VERSION "HNNBNNNYNNNNNNNNNNNNNNNNNNNNNNNNNNNNNNNNNN/4/%%%/4/'%**4NNN///"

NS_ :

BS_:

BU_: BAP_Tester ELV Gateway_Max HUD Kombi

BO_ 2527679748 RDK_11: 32 Gateway_Max
 SG_ TPMS_CalTyp : 12|2@1+ (1.0,0.0) [0.0|3] ""  Vector__XXX
 SG_ TPMS_WhlChgDetFrLe : 14|1@1+ (1.0,0.0) [0.0|1] ""  Vector__XXX
 SG_ TPMS_WhlChgDetFrRi : 15|1@1+ (1.0,0.0) [0.0|1] ""  Vector__XXX
 SG_ TPMS_WhlChgDetReLe : 16|1@1+ (1.0,0.0) [0.0|1] ""  Vector__XXX
 SG_ TPMS_WhlChgDetReRi : 17|1@1+ (1.0,0.0) [0.0|1] ""  Vector__XXX
 SG_ TPMS_Warn1 : 18|1@1+ (1.0,0.0) [0.0|1] ""  Kombi
 SG_ TPMS_Warn1TireFrLe : 19|1@1+ (1.0,0.0) [0.0|1] ""  Vector__XXX
 SG_ TPMS_Warn1TireFrRi : 20|1@1+ (1.0,0.0) [0.0|1] ""  Vector__XXX
 SG_ TPMS_Warn1TireReLe : 21|1@1+ (1.0,0.0) [0.0|1] ""  Vector__XXX
 SG_ TPMS_Warn1TireReRi : 22|1@1+ (1.0,0.0) [0.0|1] ""  Vector__XXX
 SG_ TPMS_Warn2 : 23|1@1+ (1.0,0.0) [0.0|1] ""  Kombi
 SG_ TPMS_Warn2TireFrLe : 24|1@1+ (1.0,0.0) [0.0|1] ""  Vector__XXX
 SG_ TPMS_Warn2TireFrRi : 25|1@1+ (1.0,0.0) [0.0|1] ""  Vector__XXX
 SG_ TPMS_Warn2TireReLe : 26|1@1+ (1.0,0.0) [0.0|1] ""  Vector__XXX
 SG_ TPMS_Warn2TireReRi : 27|1@1+ (1.0,0.0) [0.0|1] ""  Vector__XXX
 SG_ TPMS_Warn3 : 28|1@1+ (1.0,0.0) [0.0|1] ""  Kombi
 SG_ TPMS_Warn3TireFrLe : 29|1@1+ (1.0,0.0) [0.0|1] ""  Vector__XXX
 SG_ TPMS_Warn3TireFrRi : 30|1@1+ (1.0,0.0) [0.0|1] ""  Vector__XXX
 SG_ TPMS_Warn3TireReLe : 31|1@1+ (1.0,0.0) [0.0|1] ""  Vector__XXX
 SG_ TPMS_Warn3TireReRi : 32|1@1+ (1.0,0.0) [0.0|1] ""  Vector__XXX
 SG_ TPMS_Warn4 : 33|1@1+ (1.0,0.0) [0.0|1] ""  Vector__XXX
 SG_ TPMS_Warn4TireFrLe : 34|1@1+ (1.0,0.0) [0.0|1] ""  Vector__XXX
 SG_ TPMS_Warn4TireFrRi : 35|1@1+ (1.0,0.0) [0.0|1] ""  Vector__XXX
 SG_ TPMS_Warn4TireReLe : 36|1@1+ (1.0,0.0) [0.0|1] ""  Vector__XXX
 SG_ TPMS_Warn4TireReRi : 37|1@1+ (1.0,0.0) [0.0|1] ""  Vector__XXX
 SG_ TPMS_WarnCalOk : 38|1@1+ (1.0,0.0) [0.0|1] ""  Vector__XXX
 SG_ TPMS_WarnLmpStMil : 39|1@1+ (1.0,0.0) [0.0|1] ""  Kombi
 SG_ TPMS_WarnSysLrn : 40|1@1+ (1.0,0.0) [0.0|1] ""  Vector__XXX
 SG_ TPMS_WarnTmpFlt : 41|1@1+ (1.0,0.0) [0.0|1] ""  Kombi
 SG_ TPMS_WarnWhlChgDet : 42|1@1+ (1.0,0.0) [0.0|1] ""  Vector__XXX
 SG_ TPMS_RaceTrckMdSts : 43|1@1+ (1.0,0.0) [0.0|1] ""  Vector__XXX
 SG_ TPMS_WarnAcoCalOk : 44|1@1+ (1.0,0.0) [0.0|1] ""  Vector__XXX
 SG_ TPMS_WarnCmftP : 45|1@1+ (1.0,0.0) [0.0|1] ""  Vector__XXX
 SG_ TPMS_WarnFltIdc : 46|1@1+ (1.0,0.0) [0.0|1] ""  Kombi
 SG_ TPMS_WarnFr : 47|1@1+ (1.0,0.0) [0.0|1] ""  Vector__XXX
 SG_ TPMS_WarnLmpStP : 48|1@1+ (1.0,0.0) [0.0|1] ""  Kombi
 SG_ TPMS_WarnMaxV : 49|1@1+ (1.0,0.0) [0.0|1] ""  Vector__XXX
 SG_ TPMS_WarnRaceTrckMdMinP : 50|1@1+ (1.0,0.0) [0.0|1] ""  Vector__XXX
 SG_ TPMS_WarnRe : 51|1@1+ (1.0,0.0) [0.0|1] ""  Vector__XXX
 SG_ TPMS_SensTFrLe : 52|8@1+ (1,-60) [-60|193] "Unit_DegreCelsi"  Vector__XXX
 SG_ TPMS_SensTFrRi : 60|8@1+ (1,-60) [-60|193] "Unit_DegreCelsi"  Vector__XXX
 SG_ TPMS_SensTReLe : 68|8@1+ (1,-60) [-60|193] "Unit_DegreCelsi"  Vector__XXX
 SG_ TPMS_SensTReRi : 76|8@1+ (1,-60) [-60|193] "Unit_DegreCelsi"  Vector__XXX
 SG_ TPMS_SensPFrLe : 84|6@1+ (0.1,0) [0.0|6.2] "Unit_Bar"  Vector__XXX
 SG_ TPMS_SensPFrRi : 90|6@1+ (0.1,0) [0.0|6.2] "Unit_Bar"  Vector__XXX
 SG_ TPMS_SensPReLe : 96|6@1+ (0.1,0) [0.0|6.2] "Unit_Bar"  Vector__XXX
 SG_ TPMS_SensPReRi : 102|6@1+ (0.1,0) [0.0|6.2] "Unit_Bar"  Vector__XXX
 SG_ TPMS_PDeFrLe : 108|7@1+ (0.1,-6.3) [-6.3|6.3] "Unit_Bar"  Vector__XXX
 SG_ TPMS_PDeFrRi : 115|7@1+ (0.1,-6.3) [-6.3|6.3] "Unit_Bar"  Vector__XXX
 SG_ TPMS_PDeReLe : 122|7@1+ (0.1,-6.3) [-6.3|6.3] "Unit_Bar"  Vector__XXX
 SG_ TPMS_PDeReRi : 129|7@1+ (0.1,-6.3) [-6.3|6.3] "Unit_Bar"  Vector__XXX
 SG_ TPMS_SensBattStsFrLe : 136|7@1+ (1,0) [0|100] "Unit_PerCent"  Vector__XXX
 SG_ TPMS_SensBattStsFrRi : 143|7@1+ (1,0) [0|100] "Unit_PerCent"  Vector__XXX
 SG_ TPMS_SensBattStsReLe : 150|7@1+ (1,0) [0|100] "Unit_PerCent"  Vector__XXX
 SG_ TPMS_SensBattStsReRi : 157|7@1+ (1,0) [0|100] "Unit_PerCent"  Vector__XXX
 SG_ TPMS_SensSigAgeFrLe : 164|4@1+ (1,0) [0|10] "Unit_Minut"  Vector__XXX
 SG_ TPMS_SensSigAgeFrRi : 168|4@1+ (1,0) [0|10] "Unit_Minut"  Vector__XXX
 SG_ TPMS_SensSigAgeReLe : 172|4@1+ (1,0) [0|10] "Unit_Minut"  Vector__XXX
 SG_ TPMS_SensSigAgeReRi : 176|4@1+ (1,0) [0|10] "Unit_Minut"  Vector__XXX
 SG_ TPMS_SensStsFrLe : 180|1@1+ (1.0,0.0) [0.0|1] ""  Vector__XXX
 SG_ TPMS_SensStsFrRi : 181|1@1+ (1.0,0.0) [0.0|1] ""  Vector__XXX
 SG_ TPMS_SensStsReLe : 182|1@1+ (1.0,0.0) [0.0|1] ""  Vector__XXX
 SG_ TPMS_SensStsReRi : 183|1@1+ (1.0,0.0) [0.0|1] ""  Vector__XXX
 SG_ TPMS_SensTypFrLe : 184|1@1+ (1.0,0.0) [0.0|1] ""  Vector__XXX
 SG_ TPMS_SensTypFrRi : 185|1@1+ (1.0,0.0) [0.0|1] ""  Vector__XXX
 SG_ TPMS_SensTypReLe : 186|1@1+ (1.0,0.0) [0.0|1] ""  Vector__XXX
 SG_ TPMS_SensTypReRi : 187|1@1+ (1.0,0.0) [0.0|1] ""  Vector__XXX
 SG_ TPMS_enable : 188|1@1+ (1.0,0.0) [0.0|1] ""  Vector__XXX
 SG_ TPMS_disable : 189|1@1+ (1.0,0.0) [0.0|1] ""  Vector__XXX
 SG_ TPMS_TarPTmpDepFrLe : 190|6@1+ (0.1,0) [0.0|6.2] "Unit_Bar"  Vector__XXX
 SG_ TPMS_TarPTmpDepFrRi : 196|6@1+ (0.1,0) [0.0|6.2] "Unit_Bar"  Vector__XXX
 SG_ TPMS_TarPTmpDepReLe : 202|6@1+ (0.1,0) [0.0|6.2] "Unit_Bar"  Vector__XXX
 SG_ TPMS_TarPTmpDepReRi : 208|6@1+ (0.1,0) [0.0|6.2] "Unit_Bar"  Vector__XXX
 SG_ TPMS_LearningState : 214|4@1+ (1.0,0.0) [0.0|15] ""  Vector__XXX
 SG_ SOK_RDK_11_Signatur : 224|32@1+ (1,0) [0|4294967295] ""  Vector__XXX

BO_ 2527679742 Rear_View_06: 8 Gateway_Max
 SG_ Kam_Anf_Meldung : 12|3@1+ (1.0,0.0) [0.0|7] ""  Vector__XXX
 SG_ Kam_PaCo_MainState : 15|3@1+ (1.0,0.0) [0.0|7] ""  Vector__XXX

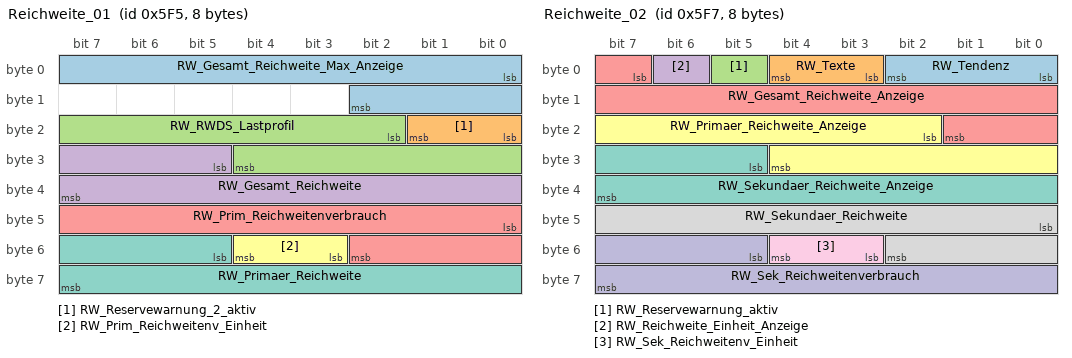
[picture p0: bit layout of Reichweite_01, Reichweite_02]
BO_ 1525 Reichweite_01: 8 Gateway_Max
 SG_ RW_Gesamt_Reichweite_Max_Anzeige : 0|11@1+ (1,0) [0|2044] "Unit_None"  Kombi
 SG_ RW_Reservewarnung_2_aktiv : 16|2@1+ (1.0,0.0) [0.0|3] ""  Vector__XXX
 SG_ RW_RWDS_Lastprofil : 18|11@1+ (1,0) [0|2045] "Unit_Amper"  Vector__XXX
 SG_ RW_Gesamt_Reichweite : 29|11@1+ (1,0) [0|2044] "Unit_KiloMeter"  Kombi
 SG_ RW_Prim_Reichweitenverbrauch : 40|11@1+ (0.1,0) [0.0|204.4] "Unit_None"  Kombi
 SG_ RW_Prim_Reichweitenv_Einheit : 51|2@1+ (1.0,0.0) [0.0|3] ""  Kombi
 SG_ RW_Primaer_Reichweite : 53|11@1+ (1,0) [0|2044] "Unit_KiloMeter"  Kombi

BO_ 1527 Reichweite_02: 8 Gateway_Max
 SG_ RW_Tendenz : 0|3@1+ (1.0,0.0) [0.0|7] ""  Vector__XXX
 SG_ RW_Texte : 3|2@1+ (1.0,0.0) [0.0|3] ""  Kombi
 SG_ RW_Reservewarnung_aktiv : 5|1@1+ (1.0,0.0) [0.0|1] ""  Kombi
 SG_ RW_Reichweite_Einheit_Anzeige : 6|1@1+ (1.0,0.0) [0.0|1] ""  Kombi
 SG_ RW_Gesamt_Reichweite_Anzeige : 7|11@1+ (1,0) [0|2044] "Unit_None"  Kombi
 SG_ RW_Primaer_Reichweite_Anzeige : 18|11@1+ (1,0) [0|2044] "Unit_None"  Kombi
 SG_ RW_Sekundaer_Reichweite_Anzeige : 29|11@1+ (1,0) [0|2044] "Unit_None"  Kombi
 SG_ RW_Sekundaer_Reichweite : 40|11@1+ (1,0) [0|2044] "Unit_KiloMeter"  Kombi
 SG_ RW_Sek_Reichweitenv_Einheit : 51|2@1+ (1.0,0.0) [0.0|3] ""  Kombi
 SG_ RW_Sek_Reichweitenverbrauch : 53|11@1+ (0.1,0) [0.0|204.4] "Unit_None"  Kombi

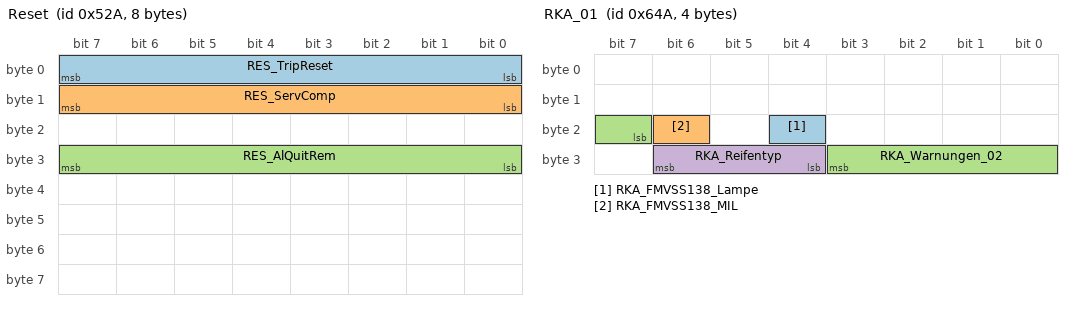
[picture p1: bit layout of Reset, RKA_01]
BO_ 1322 Reset: 8 Kombi
 SG_ RES_TripReset : 0|8@1+ (1.0,0.0) [0.0|255] ""  Vector__XXX
 SG_ RES_ServComp : 8|8@1+ (1,0) [0|255] ""  Vector__XXX
 SG_ RES_AlQuitRem : 24|8@1+ (1.0,0.0) [0.0|255] ""  Vector__XXX

BO_ 2331596042 RHP_02: 48 Gateway_Max
 SG_ RHP_02_CRC : 0|8@1+ (1,0) [0|255] ""  Kombi
 SG_ RHP_02_BZ : 8|4@1+ (1,0) [0|15] ""  Kombi
 SG_ RHP_Wunschgeschw : 12|10@1+ (0.32,0) [0.00|327.04] "Unit_KiloMeterPerHour"  Kombi
 SG_ RHP_Wunschgeschw_Farbe : 22|2@1+ (1.0,0.0) [0.0|3] ""  Kombi
 SG_ RHP_Text_02 : 24|5@1+ (1.0,0.0) [0.0|31] ""  Kombi
 SG_ RHP_Gong : 29|2@1+ (1.0,0.0) [0.0|3] ""  Kombi
 SG_ RHP_Tempolimit : 31|5@1+ (1.0,0.0) [0.0|31] ""  Kombi
 SG_ RHP_Tempolimit_Farbe : 36|2@1+ (1.0,0.0) [0.0|3] ""  Kombi
 SG_ RHP_Texte_Sekundaeranz : 38|5@1+ (1.0,0.0) [0.0|31] ""  Kombi
 SG_ RHP_aktiv_HMI : 43|2@1+ (1.0,0.0) [0.0|3] ""  Kombi
 SG_ RHP_FoD_Status : 45|2@1+ (1.0,0.0) [0.0|3] ""  Vector__XXX
 SG_ RHP_Anzeige_Objektregelung : 47|5@1+ (1.0,0.0) [0.0|31] ""  Kombi
 SG_ RHP_HMI_DetectedLane : 52|2@1+ (1.0,0.0) [0.0|3] ""  Kombi
 SG_ RHP_HMI_Ego_li_Anzeige : 54|3@1+ (1.0,0.0) [0.0|7] ""  Kombi
 SG_ RHP_HMI_Ego_li_Seg1_QuerAbst : 57|12@1+ (0.00390625,-8) [-8.00000000|7.99609375] "Unit_Meter"  Kombi
 SG_ RHP_HMI_Ego_li_Typ : 69|3@1+ (1.0,0.0) [0.0|7] ""  Kombi
 SG_ RHP_HMI_Ego_re_Anzeige : 72|3@1+ (1.0,0.0) [0.0|7] ""  Kombi
 SG_ RHP_HMI_Ego_re_Seg1_QuerAbst : 75|12@1+ (0.00390625,-8) [-8.00000000|7.99609375] "Unit_Meter"  Kombi
 SG_ RHP_HMI_Ego_re_Typ : 87|3@1+ (1.0,0.0) [0.0|7] ""  Kombi
 SG_ RHP_HMI_EgoObj_dy : 90|7@1+ (0.007874,0) [0.000000|0.999998] "Unit_PerCent"  Kombi
 SG_ RHP_HMI_Kurvenwarnung : 97|2@1+ (1.0,0.0) [0.0|3] ""  Kombi
 SG_ RHP_HMI_LaneChangeIndicator : 99|1@1+ (1.0,0.0) [0.0|1] ""  Kombi
 SG_ RHP_HMI_LaneChangeTrajectory : 100|3@1+ (1.0,0.0) [0.0|7] ""  Kombi
 SG_ RHP_HMI_Nachb_li_Anzeige : 103|3@1+ (1.0,0.0) [0.0|7] ""  Kombi
 SG_ RHP_HMI_Nachb_li_Seg1_QuerAbst : 106|12@1+ (0.00390625,-8) [-8.00000000|7.99609375] "Unit_Meter"  Kombi
 SG_ RHP_HMI_Nachb_li_Typ : 118|3@1+ (1.0,0.0) [0.0|7] ""  Kombi
 SG_ RHP_HMI_Nachb_re_Anzeige : 121|3@1+ (1.0,0.0) [0.0|7] ""  Kombi
 SG_ RHP_HMI_Nachb_re_Seg1_QuerAbst : 124|12@1+ (0.00390625,-8) [-8.00000000|7.99609375] "Unit_Meter"  Kombi
 SG_ RHP_HMI_Nachb_re_Typ : 136|3@1+ (1.0,0.0) [0.0|7] ""  Kombi
 SG_ RHP_Abstand_WZO : 139|10@1+ (0.2,0) [0.2|204.6] "Unit_Meter"  Kombi
 SG_ RHP_Sollabstand_1 : 149|10@1+ (0.2,0) [0.2|204.6] "Unit_Meter"  Kombi
 SG_ RHP_Sollabstand_2 : 159|10@1+ (0.2,0) [0.2|204.6] "Unit_Meter"  Kombi
 SG_ RHP_Sollabstand_3 : 169|10@1+ (0.2,0) [0.2|204.6] "Unit_Meter"  Kombi
 SG_ RHP_Sollabstand_4 : 179|10@1+ (0.2,0) [0.2|204.6] "Unit_Meter"  Kombi
 SG_ RHP_Sollabstand_5 : 189|10@1+ (0.2,0) [0.2|204.6] "Unit_Meter"  Kombi
 SG_ RHP_Anzeige_Zeitluecke : 199|1@1+ (1.0,0.0) [0.0|1] ""  Kombi
 SG_ RHP_Abstandsindex : 200|10@1+ (1,0) [1|1021] ""  Kombi
 SG_ RHP_Abstand_LNS : 210|10@1+ (0.2,0) [0.2|204.6] "Unit_Meter"  Kombi
 SG_ RHP_Abstand_RNS : 220|10@1+ (0.2,0) [0.2|204.6] "Unit_Meter"  Kombi
 SG_ RHP_Typ_LNS : 230|3@1+ (1.0,0.0) [0.0|7] ""  Kombi
 SG_ RHP_Typ_RNS : 233|3@1+ (1.0,0.0) [0.0|7] ""  Kombi
 SG_ RHP_Typ_WZO : 236|3@1+ (1.0,0.0) [0.0|7] ""  Kombi
 SG_ RHP_Anzeige_Maximalabstand : 239|7@1+ (2,0) [0|254] "Unit_Meter"  Kombi
 SG_ RHP_Regelgeschw : 246|10@1+ (0.32,0) [0.00|327.04] "Unit_KiloMeterPerHour"  Kombi
 SG_ RHP_EGO_Fahrzeug : 256|3@1+ (1.0,0.0) [0.0|7] ""  Kombi
 SG_ RHP_Relevantes_Objekt : 259|2@1+ (1.0,0.0) [0.0|3] ""  Kombi
 SG_ RHP_Tempolimit_Einheit : 261|1@1+ (1.0,0.0) [0.0|1] ""  Kombi
 SG_ RHP_maxSetzgeschw : 262|9@1+ (1,0) [0|510] ""  Kombi
 SG_ RHP_Einheit_maxSetzgeschw : 271|1@1+ (1.0,0.0) [0.0|1] ""  Kombi
 SG_ RHP_TOR_Lamp : 272|2@1+ (1.0,0.0) [0.0|3] ""  Kombi
 SG_ RHP_Gesetzte_Zeitluecke : 274|3@1+ (1.0,0.0) [0.0|7] ""  Kombi
 SG_ RHP_StatusLamp : 277|3@1+ (1.0,0.0) [0.0|7] ""  Kombi
 SG_ RHP_LateralLamp : 280|2@1+ (1.0,0.0) [0.0|3] ""  Kombi
 SG_ RHP_Text_01 : 282|4@1+ (1.0,0.0) [0.0|15] ""  Kombi
 SG_ RHP_ErrorStatus : 286|3@1+ (1.0,0.0) [0.0|7] ""  Kombi
 SG_ RHP_Typ_CIO : 289|3@1+ (1.0,0.0) [0.0|7] ""  Kombi
 SG_ RHP_CIO : 292|2@1+ (1.0,0.0) [0.0|3] ""  Kombi
 SG_ RHP_Abstand_CIO : 294|10@1+ (0.2,0) [0.2|204.6] "Unit_Meter"  Kombi

BO_ 1610 RKA_01: 4 Gateway_Max
 SG_ RKA_FMVSS138_Lampe : 20|1@1+ (1.0,0.0) [0.0|1] ""  Kombi
 SG_ RKA_FMVSS138_MIL : 22|1@1+ (1,0) [0|1] ""  Kombi
 SG_ RKA_Warnungen_02 : 23|5@1+ (1.0,0.0) [0.0|31] ""  Kombi
 SG_ RKA_Reifentyp : 28|3@1+ (1.0,0.0) [0.0|7] ""  Vector__XXX

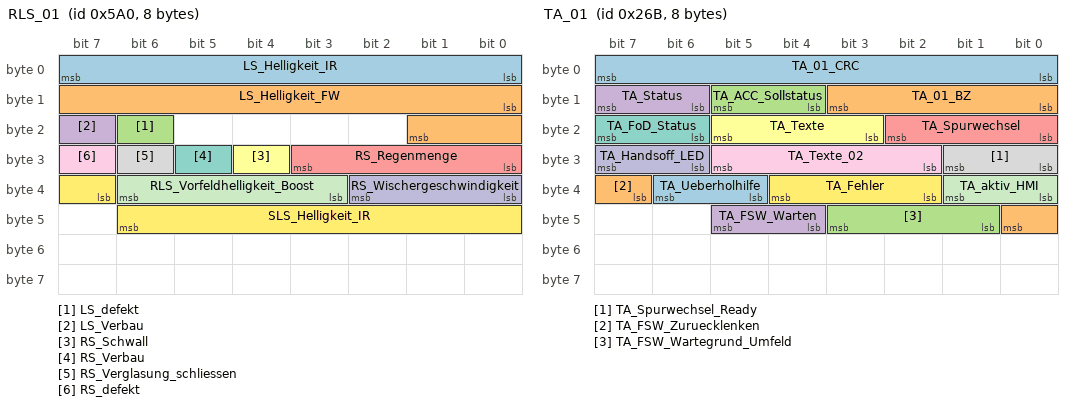
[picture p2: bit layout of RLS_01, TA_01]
BO_ 1440 RLS_01: 8 Gateway_Max
 SG_ LS_Helligkeit_IR : 0|8@1+ (400,0) [0|101200] "Unit_Lux"  Vector__XXX
 SG_ LS_Helligkeit_FW : 8|10@1+ (6,0) [0|6126] "Unit_Lux"  HUD
 SG_ LS_defekt : 22|1@1+ (1.0,0.0) [0.0|1] ""  Vector__XXX
 SG_ LS_Verbau : 23|1@1+ (1.0,0.0) [0.0|1] ""  Vector__XXX
 SG_ RS_Regenmenge : 24|4@1+ (1.0,0.0) [0.0|15] ""  Vector__XXX
 SG_ RS_Schwall : 28|1@1+ (1.0,0.0) [0.0|1] ""  Vector__XXX
 SG_ RS_Verbau : 29|1@1+ (1.0,0.0) [0.0|1] ""  Vector__XXX
 SG_ RS_Verglasung_schliessen : 30|1@1+ (1.0,0.0) [0.0|1] ""  Vector__XXX
 SG_ RS_defekt : 31|1@1+ (1.0,0.0) [0.0|1] ""  Kombi
 SG_ RS_Wischergeschwindigkeit : 32|3@1+ (1.0,0.0) [0.0|7] ""  Vector__XXX
 SG_ RLS_Vorfeldhelligkeit_Boost : 35|4@1+ (1.0,0.0) [0.0|15] ""  HUD
 SG_ SLS_Helligkeit_IR : 39|8@1+ (250,0) [0|7000] "Unit_Lux"  Vector__XXX

BO_ 2584746776 SACID_1_AuthTime_Req: 8 Gateway_Max
 SG_ SACID_1_AuthTime_Req_Data : 0|64@1+ (1.0,0.0) [0.0|18446744073709551615] ""  Kombi

BO_ 2584877848 SACID_1_AuthTime_Resp: 8 Kombi
 SG_ SACID_1_AuthTime_Resp_Data : 0|64@1+ (1.0,0.0) [0.0|18446744073709551615] ""  Gateway_Max

BO_ 1504 SAD_01: 8 Gateway_Max
 SG_ MD1_Position : 8|7@1+ (1,0) [0|100] "Unit_PerCent"  Vector__XXX
 SG_ MD1_Lage : 15|1@1+ (1.0,0.0) [0.0|1] ""  Vector__XXX
 SG_ MD3_Position : 16|7@1+ (1,0) [0|100] "Unit_PerCent"  Vector__XXX
 SG_ MD3_Lage : 23|1@1+ (1.0,0.0) [0.0|1] ""  Vector__XXX
 SG_ MRollo_Position : 24|7@1+ (1,0) [0|100] "Unit_PerCent"  Vector__XXX
 SG_ MRollo_Lage : 31|1@1+ (1.0,0.0) [0.0|1] ""  Vector__XXX
 SG_ SAD_normiert : 32|1@1+ (1.0,0.0) [0.0|1] ""  Vector__XXX
 SG_ SAD_Thermoschutz : 33|1@1+ (1.0,0.0) [0.0|1] ""  Vector__XXX
 SG_ SAD_UEKB_aktiv : 34|1@1+ (1.0,0.0) [0.0|1] ""  Vector__XXX
 SG_ Rollo_normiert : 35|1@1+ (1.0,0.0) [0.0|1] ""  Vector__XXX
 SG_ Rollo_Thermoschutz : 36|1@1+ (1.0,0.0) [0.0|1] ""  Vector__XXX
 SG_ Rollo_UEKB_aktiv : 37|1@1+ (1.0,0.0) [0.0|1] ""  Vector__XXX
 SG_ SAD_Taster_Deckel_hi : 38|4@1+ (1.0,0.0) [0.0|15] ""  Vector__XXX
 SG_ SAD_Taster_Deckel_vo : 42|4@1+ (1.0,0.0) [0.0|15] ""  Vector__XXX
 SG_ SAD_Taster_Rollo_hi : 46|3@1+ (1.0,0.0) [0.0|7] ""  Vector__XXX
 SG_ SAD_Taster_Rollo_vo : 49|3@1+ (1.0,0.0) [0.0|7] ""  Vector__XXX
 SG_ SAD_Anf_ESC_Zuschaltung : 52|1@1+ (1.0,0.0) [0.0|1] ""  Vector__XXX

BO_ 2463978605 SCode_01: 8 Kombi
 SG_ SCode_Target : 24|8@1+ (1.0,0.0) [0.0|255] ""  Gateway_Max
 SG_ SCode_Data : 32|32@1+ (1.0,0.0) [0.0|4294967295] ""  Gateway_Max

BO_ 1522 Sensorik_Dimmung_01: 2 Kombi
 SG_ KBI_Phototransistor : 0|8@1+ (1,0) [0|253] ""  Gateway_Max,HUD
 SG_ KBI_Dimmpoti : 8|7@1+ (1,0) [0|100] "Unit_PerCent"  Gateway_Max

BO_ 1167 Service_Key_01: 8 Kombi
 SG_ SK1_MUX M  : 0|8@1+ (1.0,0.0) [0.0|255] ""  Gateway_Max
 SG_ SK1_Key_Data_1 m0  : 8|56@1+ (1.0,0.0) [0.0|72057594037927935] ""  Gateway_Max
 SG_ SK1_Key_Data_2 m1  : 8|56@1+ (1.0,0.0) [0.0|72057594037927935] ""  Gateway_Max
 SG_ SK1_Key_Data_3 m2  : 8|56@1+ (1.0,0.0) [0.0|72057594037927935] ""  Gateway_Max
 SG_ SK1_Key_Data_4 m3  : 8|56@1+ (1.0,0.0) [0.0|72057594037927935] ""  Gateway_Max
 SG_ SK1_Key_Data_5 m4  : 8|56@1+ (1.0,0.0) [0.0|72057594037927935] ""  Gateway_Max
 SG_ SK1_Key_Data_6 m5  : 8|56@1+ (1.0,0.0) [0.0|72057594037927935] ""  Gateway_Max
 SG_ SK1_Key_Data_7 m6  : 8|56@1+ (1.0,0.0) [0.0|72057594037927935] ""  Gateway_Max
 SG_ SK1_Key_Data_8 m7  : 8|56@1+ (1.0,0.0) [0.0|72057594037927935] ""  Gateway_Max
 SG_ SK1_Key_Data_9 m8  : 8|56@1+ (1.0,0.0) [0.0|72057594037927935] ""  Gateway_Max
 SG_ SK1_Key_Data_10 m9  : 8|56@1+ (1.0,0.0) [0.0|72057594037927935] ""  Gateway_Max

BO_ 980 SMLS_01: 8 Gateway_Max
 SG_ SMLS_01_CRC : 0|8@1+ (1,0) [0|255] ""  Vector__XXX
 SG_ SMLS_01_BZ : 8|4@1+ (1,0) [0|15] ""  Vector__XXX
 SG_ BH_Blinker_li : 12|1@1+ (1.0,0.0) [0.0|1] ""  Vector__XXX
 SG_ BH_Blinker_re : 13|1@1+ (1.0,0.0) [0.0|1] ""  Vector__XXX
 SG_ BH_Lichthupe : 14|1@1+ (1.0,0.0) [0.0|1] ""  Vector__XXX
 SG_ BH_Fernlicht : 15|1@1+ (1.0,0.0) [0.0|1] ""  Vector__XXX
 SG_ WH_Tipwischen : 16|1@1+ (1.0,0.0) [0.0|1] ""  Vector__XXX
 SG_ WH_Intervall : 17|1@1+ (1.0,0.0) [0.0|1] ""  Vector__XXX
 SG_ WH_WischerStufe1 : 18|1@1+ (1.0,0.0) [0.0|1] ""  Vector__XXX
 SG_ WH_WischerStufe2 : 19|1@1+ (1.0,0.0) [0.0|1] ""  Vector__XXX
 SG_ WH_Frontwaschen : 20|1@1+ (1.0,0.0) [0.0|1] ""  Vector__XXX
 SG_ WH_Heckintervall : 21|1@1+ (1.0,0.0) [0.0|1] ""  Vector__XXX
 SG_ WH_Heckwaschen : 22|1@1+ (1.0,0.0) [0.0|1] ""  Vector__XXX
 SG_ WH_Intervallstufen : 23|4@1+ (1.0,0.0) [0.0|15] ""  Vector__XXX
 SG_ FAS_Taster : 27|1@1+ (1.0,0.0) [0.0|1] ""  Kombi
 SG_ FAS_Taster_Fehler : 28|1@1+ (1.0,0.0) [0.0|1] ""  Kombi
 SG_ SMLS_Hupe : 29|1@1+ (1.0,0.0) [0.0|1] ""  Vector__XXX
 SG_ LRH_On_Off : 30|2@1+ (1.0,0.0) [0.0|3] ""  Kombi
 SG_ LSS_Tastencode : 32|8@1+ (1.0,0.0) [0.0|255] ""  Kombi
 SG_ LRH_aktiv : 40|1@1+ (1.0,0.0) [0.0|1] ""  Vector__XXX
 SG_ SMLS_P_verriegelt : 41|2@1+ (1.0,0.0) [0.0|3] ""  Vector__XXX
 SG_ SMLS_P_verriegelt_plausibel : 43|1@1+ (1.0,0.0) [0.0|1] ""  Vector__XXX
 SG_ WH_SRA : 44|1@1+ (1.0,0.0) [0.0|1] ""  Vector__XXX
 SG_ WH_Wischer_Fehler : 45|1@1+ (1.0,0.0) [0.0|1] ""  Vector__XXX
 SG_ BH_Blinker_Fehler : 46|1@1+ (1.0,0.0) [0.0|1] ""  Vector__XXX
 SG_ SMLS_PTT : 47|1@1+ (1.0,0.0) [0.0|1] ""  Vector__XXX
 SG_ WH_Tipwischen_lang : 48|1@1+ (1.0,0.0) [0.0|1] ""  Vector__XXX

BO_ 2464157740 SOK_FoD_MFG_Req_Chal_02: 8 Vector__XXX
 SG_ SOK_FoD_MFG_Req_Challenge : 0|64@1+ (1,0) [0|18446744073709551615] "Unit_None"  Gateway_Max

BO_ 2464288812 SOK_FoD_MFG_Resp_Chal_02: 8 Gateway_Max
 SG_ SOK_FoD_MFG_Resp_Challenge : 0|64@1+ (1,0) [0|18446744073709551615] "Unit_None"  Vector__XXX

BO_ 2589283756 SOK_NoAuthenticTime_01: 8 Gateway_Max
 SG_ SOK_ungeschuetzte_Zeit : 8|56@1+ (1,0) [1|72057594037927935] "Unit_None"  Kombi

BO_ 2464153620 SOK_Zeit_Kombi_Chal_01: 8 Kombi
 SG_ SOK_Zeit_Kombi_Challenge : 0|64@1+ (1,0) [0|18446744073709551615] "Unit_None"  Gateway_Max

BO_ 2464284692 SOK_Zeit_Kombi_Signatur_Resp_01: 8 Gateway_Max
 SG_ SOK_Zeit_Kombi_Signatur : 0|64@1+ (1,0) [0|18446744073709551615] "Unit_None"  Kombi

BO_ 2464288788 SOK_Zeit_Kombi_Zeit_Resp_01: 8 Gateway_Max
 SG_ SOK_Zeit_Kombi_Zeit : 0|56@1+ (1,0) [0|72057594037927935] "Unit_None"  Kombi

BO_ 2464153644 SOK_Zeit_MFG_Chal_01: 8 Vector__XXX
 SG_ SOK_Zeit_MFG_Challenge : 0|64@1+ (1,0) [0|18446744073709551615] "Unit_None"  Gateway_Max

BO_ 2464284716 SOK_Zeit_MFG_Resp_01: 16 Gateway_Max
 SG_ SOK_Zeit_MFG_Zeit : 0|56@1+ (1,0) [0|72057594037927935] "Unit_None"  Vector__XXX
 SG_ SOK_Zeit_MFG_Signatur : 64|64@1+ (1,0) [0|18446744073709551615] "Unit_None"  Vector__XXX

BO_ 1467 SoSe_01: 8 Gateway_Max
 SG_ SoSe_SunInt_2D_Li : 0|8@1+ (5,0) [0|1200] "Unit_WattPerMeterSquar"  Vector__XXX
 SG_ SoSe_SunInt_2D_Re : 8|8@1+ (5,0) [0|1200] "Unit_WattPerMeterSquar"  Vector__XXX

BO_ 2527679739 Standklima_01: 8 Gateway_Max
 SG_ STK_Betriebsdauer : 5|7@1+ (1,0) [0|120] "Unit_Minut"  Vector__XXX
 SG_ STK_FSH_Anf : 12|1@1+ (1.0,0.0) [0.0|1] ""  Vector__XXX
 SG_ STK_HSH_Anf : 13|1@1+ (1.0,0.0) [0.0|1] ""  Vector__XXX
 SG_ STK_Klima_Temp : 14|5@1+ (0.5,15.5) [15.5|29.5] "Unit_DegreCelsi"  Vector__XXX
 SG_ STK_KurzVK_Anf : 19|1@1+ (1.0,0.0) [0.0|1] ""  Vector__XXX
 SG_ STK_Standklima_Anf : 20|1@1+ (1.0,0.0) [0.0|1] ""  Vector__XXX
 SG_ STK_Standklima_Timer_Status : 21|1@1+ (1.0,0.0) [0.0|1] ""  Vector__XXX
 SG_ STK_AirCLeaner_Anf : 22|1@1+ (1.0,0.0) [0.0|1] ""  Vector__XXX
 SG_ STK_VK_Modus : 23|2@1+ (1.0,0.0) [0.0|3] ""  Vector__XXX
 SG_ STK_ErwVK_Anf : 25|1@1+ (1.0,0.0) [0.0|1] ""  Vector__XXX
 SG_ STK_ErwVK_Modus : 26|4@1+ (1.0,0.0) [0.0|15] ""  Vector__XXX
 SG_ STK_Berechnungsphase : 30|2@1+ (1.0,0.0) [0.0|3] ""  Vector__XXX
 SG_ STK_VK_Timer_Status : 32|2@1+ (1.0,0.0) [0.0|3] ""  Vector__XXX
 SG_ STK_Anf_AussenspiegelHZ : 34|1@1+ (1.0,0.0) [0.0|1] ""  Vector__XXX
 SG_ STK_ErwVK_Beifahrerzone : 35|1@1+ (1.0,0.0) [0.0|1] ""  Vector__XXX
 SG_ STK_ErwVK_Fahrerzone : 36|1@1+ (1.0,0.0) [0.0|1] ""  Vector__XXX
 SG_ STK_ErwVK_Heckzone_links : 37|1@1+ (1.0,0.0) [0.0|1] ""  Vector__XXX
 SG_ STK_ErwVK_Heckzone_rechts : 38|1@1+ (1.0,0.0) [0.0|1] ""  Vector__XXX
 SG_ STK_ErwVK_Scheibenheizung : 39|1@1+ (1.0,0.0) [0.0|1] ""  Vector__XXX
 SG_ STK_VK_STH_Einsatz : 40|3@1+ (1.0,0.0) [0.0|7] ""  Vector__XXX
 SG_ STK_Voko_LED : 43|1@1+ (1.0,0.0) [0.0|1] ""  Kombi
 SG_ STK_MaxLeistung : 44|8@1+ (0.1,0) [0.0|15.0] "Unit_KiloWatt"  Vector__XXX
 SG_ STK_GesamtEnergiebedarf : 52|8@1+ (0.1,0) [0.0|15.0] "Unit_KiloWattHour"  Vector__XXX
 SG_ STK_Stecker_Status : 60|2@1+ (1.0,0.0) [0.0|3] ""  Vector__XXX
 SG_ STK_ErwVK_Heckzone2_links : 62|1@1+ (1.0,0.0) [0.0|1] ""  Vector__XXX
 SG_ STK_ErwVK_Heckzone2_rechts : 63|1@1+ (1.0,0.0) [0.0|1] ""  Vector__XXX

BO_ 1313 STH_01: 8 Gateway_Max
 SG_ STH_Funk_ein : 0|1@1+ (1.0,0.0) [0.0|1] ""  Vector__XXX
 SG_ STH_Funk_aus : 1|1@1+ (1.0,0.0) [0.0|1] ""  Vector__XXX
 SG_ STH_Zusatzheizung : 2|1@1+ (1.0,0.0) [0.0|1] ""  Vector__XXX
 SG_ STH_LED : 3|1@1+ (1.0,0.0) [0.0|1] ""  Vector__XXX
 SG_ STH_Pumpe_ein : 4|1@1+ (1,0) [0|1] ""  Vector__XXX
 SG_ STH_Geblaese : 5|1@1+ (1.0,0.0) [0.0|1] ""  Vector__XXX
 SG_ STH_EKP_Anst : 6|1@1+ (1.0,0.0) [0.0|1] ""  Vector__XXX
 SG_ STH_Start_folgt : 7|1@1+ (1.0,0.0) [0.0|1] ""  Vector__XXX
 SG_ STH_Ventiloeffnungszeit : 8|6@1+ (1,0) [0|63] "Unit_Minut"  Vector__XXX
 SG_ STH_Ventil_Status : 14|1@1+ (1.0,0.0) [0.0|1] ""  Vector__XXX
 SG_ STH_Fehler_ElWaPu : 15|1@1+ (1.0,0.0) [0.0|1] ""  Vector__XXX
 SG_ STH_Waermeeintrag : 16|6@1+ (1,0) [0|63] "Unit_None"  Vector__XXX
 SG_ STH_Pumpen_Anf_extern : 22|1@1+ (1.0,0.0) [0.0|1] ""  Vector__XXX
 SG_ STH_KL_HUP : 23|1@1+ (1.0,0.0) [0.0|1] ""  Vector__XXX
 SG_ STH_KVS : 24|13@1+ (1,0) [0|8191] "Unit_MilliLiter"  Kombi
 SG_ STH_Fehlerstatus : 37|3@1+ (1.0,0.0) [0.0|7] ""  Vector__XXX
 SG_ STH_Heizleistung : 40|8@1+ (1,0) [0|255] ""  Kombi
 SG_ STH_Wassertemp : 48|8@1+ (0.75,-40) [-40.00|142.25] "Unit_DegreCelsi"  Vector__XXX
 SG_ STH_Texte : 56|3@1+ (1.0,0.0) [0.0|7] ""  Kombi
 SG_ STH_Motorvorwaermung : 59|1@1+ (1.0,0.0) [0.0|1] ""  Vector__XXX
 SG_ STH_Servicemode : 60|1@1+ (1.0,0.0) [0.0|1] ""  Vector__XXX
 SG_ STH_war_aktiv : 61|1@1+ (1.0,0.0) [0.0|1] ""  Vector__XXX
 SG_ STH_KVS_Ueberlauf : 62|1@1+ (1.0,0.0) [0.0|1] ""  Kombi
 SG_ STH_SH_ZH : 63|1@1+ (1.0,0.0) [0.0|1] ""  Vector__XXX

BO_ 1413 Systeminfo_01: 8 Gateway_Max
 SG_ SI_Sammel_SG_Fehler : 0|6@1+ (1,0) [0|60] ""  Kombi
 SG_ SI_P_Mode_gueltig : 6|1@1+ (1.0,0.0) [0.0|1] ""  Kombi
 SG_ SI_Diagnose_Aktiv : 7|1@1+ (1.0,0.0) [0.0|1] ""  Vector__XXX
 SG_ SI_QRS_Mode : 8|1@1+ (1.0,0.0) [0.0|1] ""  HUD,Kombi
 SG_ SI_T_Mode : 9|1@1+ (1.0,0.0) [0.0|1] ""  HUD,Kombi
 SG_ SI_NWDF : 10|1@1+ (1.0,0.0) [0.0|1] ""  ELV,HUD,Kombi
 SG_ SI_NWDF_gueltig : 11|1@1+ (1.0,0.0) [0.0|1] ""  ELV,HUD,Kombi
 SG_ SI_Sammelfehler : 12|1@1+ (1.0,0.0) [0.0|1] ""  Vector__XXX
 SG_ GW_KD_Fehler : 13|1@1+ (1.0,0.0) [0.0|1] ""  Vector__XXX
 SG_ SI_T_Schutz : 14|1@1+ (1.0,0.0) [0.0|1] ""  Kombi
 SG_ SI_P_Mode : 15|1@1+ (1.0,0.0) [0.0|1] ""  Kombi
 SG_ SI_BUS_01 : 16|1@1+ (1.0,0.0) [0.0|1] ""  Kombi
 SG_ SI_BUS_02 : 17|1@1+ (1.0,0.0) [0.0|1] ""  Kombi
 SG_ SI_BUS_03 : 18|1@1+ (1.0,0.0) [0.0|1] ""  Kombi
 SG_ SI_BUS_04 : 19|1@1+ (1.0,0.0) [0.0|1] ""  Kombi
 SG_ SI_BUS_05 : 20|1@1+ (1.0,0.0) [0.0|1] ""  Kombi
 SG_ SI_BUS_06 : 21|1@1+ (1.0,0.0) [0.0|1] ""  Kombi
 SG_ SI_BUS_07 : 22|1@1+ (1.0,0.0) [0.0|1] ""  Vector__XXX
 SG_ SI_BUS_08 : 23|1@1+ (1.0,0.0) [0.0|1] ""  Vector__XXX
 SG_ SI_BUS_09 : 24|1@1+ (1.0,0.0) [0.0|1] ""  Vector__XXX
 SG_ SI_BUS_10 : 25|1@1+ (1.0,0.0) [0.0|1] ""  Kombi
 SG_ SI_BUS_11 : 26|1@1+ (1.0,0.0) [0.0|1] ""  Vector__XXX
 SG_ SI_BUS_12 : 27|1@1+ (1.0,0.0) [0.0|1] ""  Kombi
 SG_ SI_BUS_13 : 28|1@1+ (1.0,0.0) [0.0|1] ""  Kombi
 SG_ SI_BUS_14 : 29|1@1+ (1.0,0.0) [0.0|1] ""  Kombi
 SG_ SI_BUS_15 : 30|1@1+ (1.0,0.0) [0.0|1] ""  Vector__XXX
 SG_ SI_NWDF_30 : 31|1@1+ (1.0,0.0) [0.0|1] ""  Vector__XXX
 SG_ SI_Bus_Identifikation : 32|8@1+ (1.0,0.0) [0.0|255] ""  Kombi
 SG_ SI_CAB_V14 : 40|24@1+ (1.0,0.0) [0.0|16777215] ""  Kombi

BO_ 619 TA_01: 8 Gateway_Max
 SG_ TA_01_CRC : 0|8@1+ (1,0) [0|255] ""  Vector__XXX
 SG_ TA_01_BZ : 8|4@1+ (1,0) [0|15] ""  Vector__XXX
 SG_ TA_ACC_Sollstatus : 12|2@1+ (1.0,0.0) [0.0|3] ""  Vector__XXX
 SG_ TA_Status : 14|2@1+ (1.0,0.0) [0.0|3] ""  HUD,Kombi
 SG_ TA_Spurwechsel : 16|3@1+ (1.0,0.0) [0.0|7] ""  HUD,Kombi
 SG_ TA_Texte : 19|3@1+ (1.0,0.0) [0.0|7] ""  HUD,Kombi
 SG_ TA_FoD_Status : 22|2@1+ (1.0,0.0) [0.0|3] ""  Kombi
 SG_ TA_Spurwechsel_Ready : 24|2@1+ (1.0,0.0) [0.0|3] ""  Vector__XXX
 SG_ TA_Texte_02 : 26|4@1+ (1.0,0.0) [0.0|15] ""  HUD,Kombi
 SG_ TA_Handsoff_LED : 30|2@1+ (1.0,0.0) [0.0|3] ""  Kombi
 SG_ TA_aktiv_HMI : 32|2@1+ (1.0,0.0) [0.0|3] ""  HUD,Kombi
 SG_ TA_Fehler : 34|3@1+ (1.0,0.0) [0.0|7] ""  HUD,Kombi
 SG_ TA_Ueberholhilfe : 37|2@1+ (1.0,0.0) [0.0|3] ""  Vector__XXX
 SG_ TA_FSW_Zuruecklenken : 39|2@1+ (1.0,0.0) [0.0|3] ""  Vector__XXX
 SG_ TA_FSW_Wartegrund_Umfeld : 41|3@1+ (1.0,0.0) [0.0|7] ""  HUD,Kombi
 SG_ TA_FSW_Warten : 44|2@1+ (1.0,0.0) [0.0|3] ""  HUD,Kombi

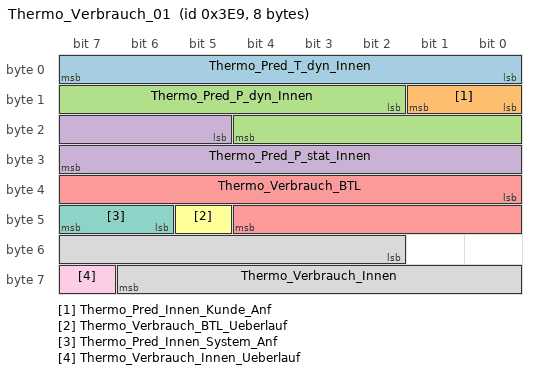
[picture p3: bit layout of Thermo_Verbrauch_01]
BO_ 1001 Thermo_Verbrauch_01: 8 Gateway_Max
 SG_ Thermo_Pred_T_dyn_Innen : 0|8@1+ (1,0) [0|253] "Unit_Minut"  Vector__XXX
 SG_ Thermo_Pred_Innen_Kunde_Anf : 8|2@1+ (1,0) [0|3] "Unit_None"  Vector__XXX
 SG_ Thermo_Pred_P_dyn_Innen : 10|11@1+ (10,0) [0|20450] "Unit_Watt"  Vector__XXX
 SG_ Thermo_Pred_P_stat_Innen : 21|11@1+ (10,0) [0|20450] "Unit_Watt"  Vector__XXX
 SG_ Thermo_Verbrauch_BTL : 32|13@1+ (1,0) [0|8191] "Unit_WattSecond"  Kombi
 SG_ Thermo_Verbrauch_BTL_Ueberlauf : 45|1@1+ (1.0,0.0) [0.0|1] ""  Kombi
 SG_ Thermo_Pred_Innen_System_Anf : 46|2@1+ (1,0) [0|3] "Unit_None"  Vector__XXX
 SG_ Thermo_Verbrauch_Innen : 50|13@1+ (1,0) [0|8191] "Unit_WattSecond"  Kombi
 SG_ Thermo_Verbrauch_Innen_Ueberlauf : 63|1@1+ (1.0,0.0) [0.0|1] ""  Kombi

BO_ 1447 TM_01: 8 Gateway_Max
 SG_ ORU_KombiTimer : 20|2@1+ (1.0,0.0) [0.0|3] ""  Kombi
 SG_ MOD_Energie_Anf : 22|2@1+ (1.0,0.0) [0.0|3] ""  Vector__XXX
 SG_ FaceRec_Enroll_Challenge_Request : 24|1@1+ (1.0,0.0) [0.0|1] ""  Vector__XXX
 SG_ eCall_Mute_Anf : 25|1@1+ (1.0,0.0) [0.0|1] ""  Kombi
 SG_ eCall_MCC : 26|10@1+ (1,0) [0|999] "Unit_None"  Vector__XXX
 SG_ FoD_Anz_Funktionsabschaltung : 36|2@1+ (1.0,0.0) [0.0|3] ""  Kombi
 SG_ iCall_active : 38|1@1+ (1.0,0.0) [0.0|1] ""  Vector__XXX
 SG_ bCall_active : 39|1@1+ (1.0,0.0) [0.0|1] ""  Vector__XXX
 SG_ MOD_Request_ServiceKey : 40|1@1+ (1.0,0.0) [0.0|1] ""  Kombi
 SG_ eCall_Funktionsstatus_02 : 41|3@1+ (1.0,0.0) [0.0|7] ""  Vector__XXX
 SG_ eCall_Funktionsstatus : 44|3@1+ (1.0,0.0) [0.0|7] ""  Kombi
 SG_ TM_Spiegel_Anklappen : 47|1@1+ (1.0,0.0) [0.0|1] ""  Vector__XXX
 SG_ TM_Nur_Hupen : 48|1@1+ (1.0,0.0) [0.0|1] ""  Vector__XXX
 SG_ TM_Door_Lock : 49|1@1+ (1.0,0.0) [0.0|1] ""  Vector__XXX
 SG_ TM_Door_Unlock : 50|1@1+ (1.0,0.0) [0.0|1] ""  Vector__XXX
 SG_ TM_Warnblinken : 51|1@1+ (1.0,0.0) [0.0|1] ""  Vector__XXX
 SG_ TM_Panik_Alarm : 52|1@1+ (1.0,0.0) [0.0|1] ""  Vector__XXX
 SG_ TM_ZV_Signatur : 53|11@1+ (1,0) [1|2047] "Unit_None"  Vector__XXX

BO_ 977 TSG_BT_01: 8 Gateway_Max
 SG_ BT_Tuer_geoeffnet : 0|1@1+ (1.0,0.0) [0.0|1] ""  HUD
 SG_ BT_verriegelt : 1|1@1+ (1.0,0.0) [0.0|1] ""  Vector__XXX
 SG_ BT_gesafet : 2|1@1+ (1.0,0.0) [0.0|1] ""  Vector__XXX
 SG_ BT_Schluesselschalter_auf : 3|1@1+ (1.0,0.0) [0.0|1] ""  Vector__XXX
 SG_ BT_Schluesselschalter_zu : 4|1@1+ (1.0,0.0) [0.0|1] ""  Vector__XXX
 SG_ BT_Unlock_Taster : 5|1@1+ (1.0,0.0) [0.0|1] ""  Vector__XXX
 SG_ BT_Lock_Taster : 6|1@1+ (1.0,0.0) [0.0|1] ""  Vector__XXX
 SG_ BT_Sperrklinke : 7|1@1+ (1.0,0.0) [0.0|1] ""  Vector__XXX
 SG_ BT_TAG_betaetigt : 8|1@1+ (1.0,0.0) [0.0|1] ""  Vector__XXX
 SG_ BT_TIG_betaetigt : 9|1@1+ (1.0,0.0) [0.0|1] ""  Vector__XXX
 SG_ BT_EC_Spiegel_Helligkeit : 10|5@1+ (3.125,0) [0.000|96.875] "Unit_PerCent"  Vector__XXX
 SG_ BT_Sp_Heizung_Anf : 15|1@1+ (100,0) [0|100] "Unit_PerCent"  Vector__XXX
 SG_ BT_Tuer_Status : 16|2@1+ (1.0,0.0) [0.0|3] ""  Vector__XXX
 SG_ BT_TSG_hinten_verbaut : 18|1@1+ (1.0,0.0) [0.0|1] ""  Vector__XXX
 SG_ BT_Sp_Blk_def : 19|1@1+ (1.0,0.0) [0.0|1] ""  Vector__XXX
 SG_ BT_FH_S_ManHoch : 20|1@1+ (1.0,0.0) [0.0|1] ""  Vector__XXX
 SG_ BT_FH_S_AutoHoch : 21|1@1+ (1.0,0.0) [0.0|1] ""  Vector__XXX
 SG_ BT_FH_S_ManTief : 22|1@1+ (1.0,0.0) [0.0|1] ""  Vector__XXX
 SG_ BT_FH_S_AutoTief : 23|1@1+ (1.0,0.0) [0.0|1] ""  Vector__XXX
 SG_ BT_FH_Oeffnung : 24|8@1+ (0.5,0) [0.0|100.0] "Unit_PerCent"  Vector__XXX
 SG_ BT_FH_Bew_hoch : 32|1@1+ (1.0,0.0) [0.0|1] ""  Vector__XXX
 SG_ BT_FH_Bew_tief : 33|1@1+ (1.0,0.0) [0.0|1] ""  Vector__XXX
 SG_ BT_FH_Fang : 34|1@1+ (1.0,0.0) [0.0|1] ""  Vector__XXX
 SG_ BT_FH_Block : 35|1@1+ (1.0,0.0) [0.0|1] ""  Vector__XXX
 SG_ BT_FH_Thermo : 36|1@1+ (1.0,0.0) [0.0|1] ""  Vector__XXX
 SG_ BT_UEKB_aktiviert : 37|1@1+ (1.0,0.0) [0.0|1] ""  Vector__XXX
 SG_ BT_Kisi_Fehler : 38|1@1+ (1.0,0.0) [0.0|1] ""  Vector__XXX
 SG_ BT_FH_normiert : 39|1@1+ (1.0,0.0) [0.0|1] ""  Vector__XXX
 SG_ BT_Schliesstaster : 40|1@1+ (1.0,0.0) [0.0|1] ""  Vector__XXX
 SG_ BT_Zuziehhilfe_aktiv : 41|1@1+ (1.0,0.0) [0.0|1] ""  Vector__XXX
 SG_ BT_SP_ausgerastet : 42|1@1+ (1.0,0.0) [0.0|1] ""  Vector__XXX
 SG_ BT_SP_lr_aktiv : 43|1@1+ (1.0,0.0) [0.0|1] ""  Vector__XXX
 SG_ BT_SP_ht_aktiv : 44|1@1+ (1.0,0.0) [0.0|1] ""  Vector__XXX
 SG_ BT_SP_Heizung_aktiv : 45|1@1+ (1.0,0.0) [0.0|1] ""  Vector__XXX
 SG_ BT_Oben_Block_erw : 46|1@1+ (1.0,0.0) [0.0|1] ""  Vector__XXX
 SG_ BT_Unten_Block_erw : 47|1@1+ (1.0,0.0) [0.0|1] ""  Vector__XXX
 SG_ BT_Tuer_Status_QBit : 48|1@1+ (1.0,0.0) [0.0|1] ""  Vector__XXX
 SG_ BFS_Status_eTAG : 49|2@1+ (1.0,0.0) [0.0|3] ""  Vector__XXX
 SG_ BT_TCR_Mode_aktiv : 51|1@1+ (1.0,0.0) [0.0|1] ""  Vector__XXX
 SG_ BT_Lock_Unlock_Taster : 52|1@1+ (1.0,0.0) [0.0|1] ""  Vector__XXX
 SG_ BT_SP_Heizung_Status : 55|1@1+ (1.0,0.0) [0.0|1] ""  Vector__XXX
 SG_ ASW_Warnung_aktiv_BFS : 56|1@1+ (1.0,0.0) [0.0|1] ""  Vector__XXX
 SG_ BT_FH_Pos_oben : 57|1@1+ (1.0,0.0) [0.0|1] ""  Vector__XXX
 SG_ BT_Tuerschloss_defekt : 58|1@1+ (1.0,0.0) [0.0|1] ""  Vector__XXX
 SG_ BT_Tueroeffnen_Warnung : 59|1@1+ (1.0,0.0) [0.0|1] ""  Vector__XXX
 SG_ BT_Lock_Taster_inv : 60|1@1+ (1.0,0.0) [0.0|1] ""  Vector__XXX
 SG_ BT_Schluesselschalter_zu_inv : 61|1@1+ (1.0,0.0) [0.0|1] ""  Vector__XXX
 SG_ BT_SWA_HMI_defekt : 62|1@1+ (1.0,0.0) [0.0|1] ""  Vector__XXX
 SG_ BT_ASW_HMI_defekt : 63|1@1+ (1.0,0.0) [0.0|1] ""  Vector__XXX

BO_ 976 TSG_FT_01: 8 Gateway_Max
 SG_ FT_Tuer_geoeffnet : 0|1@1+ (1.0,0.0) [0.0|1] ""  ELV
 SG_ FT_verriegelt : 1|1@1+ (1.0,0.0) [0.0|1] ""  Vector__XXX
 SG_ FT_gesafet : 2|1@1+ (1.0,0.0) [0.0|1] ""  Vector__XXX
 SG_ FT_Schluesselschalter_auf : 3|1@1+ (1.0,0.0) [0.0|1] ""  Vector__XXX
 SG_ FT_Schluesselschalter_zu : 4|1@1+ (1.0,0.0) [0.0|1] ""  Vector__XXX
 SG_ FT_Unlock_Taster : 5|1@1+ (1.0,0.0) [0.0|1] ""  Vector__XXX
 SG_ FT_Lock_Taster : 6|1@1+ (1.0,0.0) [0.0|1] ""  Vector__XXX
 SG_ FT_Sperrklinke : 7|1@1+ (1.0,0.0) [0.0|1] ""  Vector__XXX
 SG_ FT_TAG_betaetigt : 8|1@1+ (1.0,0.0) [0.0|1] ""  Vector__XXX
 SG_ FT_TIG_betaetigt : 9|1@1+ (1.0,0.0) [0.0|1] ""  Vector__XXX
 SG_ FT_IRUE_Taste : 10|1@1+ (1.0,0.0) [0.0|1] ""  Vector__XXX
 SG_ FT_HD_Taste : 11|1@1+ (1.0,0.0) [0.0|1] ""  Vector__XXX
 SG_ FT_TD_Taste_Fehler : 12|1@1+ (1.0,0.0) [0.0|1] ""  Vector__XXX
 SG_ FT_TD_Taste : 13|1@1+ (1.0,0.0) [0.0|1] ""  Vector__XXX
 SG_ SSR_Temp_Freigabe : 14|1@1+ (1.0,0.0) [0.0|1] ""  Vector__XXX
 SG_ FT_Sp_Heizung_Anf : 15|1@1+ (100,0) [0|100] "Unit_PerCent"  Vector__XXX
 SG_ FT_HD_Taste_2 : 16|1@1+ (1.0,0.0) [0.0|1] ""  Vector__XXX
 SG_ FT_Lock_Unlock_Taster : 17|1@1+ (1.0,0.0) [0.0|1] ""  Vector__XXX
 SG_ FT_TSG_hinten_verbaut : 18|1@1+ (1.0,0.0) [0.0|1] ""  Vector__XXX
 SG_ FT_Sp_Blk_def : 19|1@1+ (1.0,0.0) [0.0|1] ""  Vector__XXX
 SG_ FT_FH_S_ManHoch : 20|1@1+ (1.0,0.0) [0.0|1] ""  Vector__XXX
 SG_ FT_FH_S_AutoHoch : 21|1@1+ (1.0,0.0) [0.0|1] ""  Vector__XXX
 SG_ FT_FH_S_ManTief : 22|1@1+ (1.0,0.0) [0.0|1] ""  Vector__XXX
 SG_ FT_FH_S_AutoTief : 23|1@1+ (1.0,0.0) [0.0|1] ""  Vector__XXX
 SG_ FT_FH_Oeffnung : 24|8@1+ (0.5,0) [0.0|100.0] "Unit_PerCent"  Vector__XXX
 SG_ FT_FH_Bew_hoch : 32|1@1+ (1.0,0.0) [0.0|1] ""  Vector__XXX
 SG_ FT_FH_Bew_tief : 33|1@1+ (1.0,0.0) [0.0|1] ""  Vector__XXX
 SG_ FT_FH_Fang : 34|1@1+ (1.0,0.0) [0.0|1] ""  Vector__XXX
 SG_ FT_FH_Block : 35|1@1+ (1.0,0.0) [0.0|1] ""  Vector__XXX
 SG_ FT_FH_Thermo : 36|1@1+ (1.0,0.0) [0.0|1] ""  Vector__XXX
 SG_ FT_UEKB_aktiviert : 37|1@1+ (1.0,0.0) [0.0|1] ""  Vector__XXX
 SG_ ASW_HMI_defekt : 38|1@1+ (1.0,0.0) [0.0|1] ""  Vector__XXX
 SG_ FT_FH_normiert : 39|1@1+ (1.0,0.0) [0.0|1] ""  Vector__XXX
 SG_ FT_Schliesstaster : 40|1@1+ (1.0,0.0) [0.0|1] ""  Vector__XXX
 SG_ FT_Zuziehhilfe_aktiv : 41|1@1+ (1.0,0.0) [0.0|1] ""  Vector__XXX
 SG_ FT_SP_ausgerastet : 42|1@1+ (1.0,0.0) [0.0|1] ""  Vector__XXX
 SG_ FT_SP_lr_aktiv : 43|1@1+ (1.0,0.0) [0.0|1] ""  Vector__XXX
 SG_ FT_SP_ht_aktiv : 44|1@1+ (1.0,0.0) [0.0|1] ""  Vector__XXX
 SG_ ASW_wakeup : 45|1@1+ (1.0,0.0) [0.0|1] ""  Vector__XXX
 SG_ FT_Oben_Block_erw : 46|1@1+ (1.0,0.0) [0.0|1] ""  Vector__XXX
 SG_ FT_Unten_Block_erw : 47|1@1+ (1.0,0.0) [0.0|1] ""  Vector__XXX
 SG_ FT_Kisi_li_aktiv : 48|1@1+ (1.0,0.0) [0.0|1] ""  Vector__XXX
 SG_ FT_Kisi_re_aktiv : 49|1@1+ (1.0,0.0) [0.0|1] ""  Vector__XXX
 SG_ FT_Kisi_Taster_li : 50|1@1+ (1.0,0.0) [0.0|1] ""  Vector__XXX
 SG_ FT_Kisi_Taster_re : 51|1@1+ (1.0,0.0) [0.0|1] ""  Vector__XXX
 SG_ FT_BFS_Fond_Freigabe : 52|1@1+ (1.0,0.0) [0.0|1] ""  Vector__XXX
 SG_ FT_Kisi_Fehler : 53|1@1+ (1.0,0.0) [0.0|1] ""  Kombi
 SG_ FT_Daemmglas : 54|1@1+ (1.0,0.0) [0.0|1] ""  Vector__XXX
 SG_ FT_SP_Heizung_Status : 55|1@1+ (1.0,0.0) [0.0|1] ""  Vector__XXX
 SG_ ASW_Warnung_aktiv_FS : 56|1@1+ (1.0,0.0) [0.0|1] ""  Vector__XXX
 SG_ FT_FH_Pos_oben : 57|1@1+ (1.0,0.0) [0.0|1] ""  Vector__XXX
 SG_ FT_Tuerschloss_defekt : 58|1@1+ (1.0,0.0) [0.0|1] ""  Vector__XXX
 SG_ FT_SWA_Taster : 59|1@1+ (1.0,0.0) [0.0|1] ""  Vector__XXX
 SG_ SWA_HMI_Diagnose : 60|2@1+ (1.0,0.0) [0.0|3] ""  Vector__XXX
 SG_ FS_Status_eTAG : 62|2@1+ (1.0,0.0) [0.0|3] ""  Vector__XXX

CM_ BO_ 1440 "8Byte ab MLBevo
LIN-CAN (1:1) Botschaften werden geroutet
-  wenn entsprechender Slave codiert ist
-  wenn fehlerfreie Kommunikation zum Slave besteht
-  bei fehlerhafter Kommunikation zum Slave wird die Botschaft für 4s mit den letzten gültigen Werte";
CM_ BO_ 1504 "MLBevo 8Byte
LIN-CAN (1:1) Botschaft wird geroutet:
- wenn entsprechender Slave codiert ist
- wenn fehlerfreie Kommunikation zum Slave besteht
- bei fehlerhafter Kommunikation zum Slave wird die Botschaft für 4s mit den letzten gültigen Werten versend";
CM_ BO_ 1522 "MQB";
CM_ BO_ 980 "Ab MQB 7.2";
CM_ BO_ 1413 "MQB, MLBevo";
CM_ BO_ 977 "ab MQB 7.05";
CM_ BO_ 976 "ab MQB 7.05";

CM_ SG_ 2527679748 SOK_RDK_11_Signatur "Signatur im Rahmen der durch SOK geschützen Broadcast-Kommunikation
";
CM_ SG_ 2527679748 TPMS_CalTyp "Specification type of target pressure";
CM_ SG_ 2527679748 TPMS_disable "Das Signal wird zur Textanzeige im Fahrerdisplay benötigt. TPMS wird automatisch ausgeschaltet.";
CM_ SG_ 2527679748 TPMS_enable "Das Signal wird zur Textanzeige im Fahrerdisplay benötigt. TPMS wird automatisch eingeschaltet.";
CM_ SG_ 2527679748 TPMS_LearningState "Status of the TPMS learning process";
CM_ SG_ 2527679748 TPMS_PDeFrLe "Pressure deviation between actual and set pressure front left, normalized to 20°C";
CM_ SG_ 2527679748 TPMS_PDeFrRi "Pressure deviation between actual and set pressure front right, normalized to 20°C";
CM_ SG_ 2527679748 TPMS_PDeReLe "Pressure deviation between actual and set pressure rear left, normalized to 20°C";
CM_ SG_ 2527679748 TPMS_PDeReRi "Pressure deviation between actual and set pressure rear right, normalized to 20°C";
CM_ SG_ 2527679748 TPMS_RaceTrckMdSts "State of the racetrack mode";
CM_ SG_ 2527679748 TPMS_SensBattStsFrLe "Sensor Battery Status front left";
CM_ SG_ 2527679748 TPMS_SensBattStsFrRi "Sensor Battery Status front right";
CM_ SG_ 2527679748 TPMS_SensBattStsReLe "Sensor Battery Status rear left";
CM_ SG_ 2527679748 TPMS_SensBattStsReRi "Sensor Battery Status rear right";
CM_ SG_ 2527679748 TPMS_SensPFrLe "Sensor measured pressure (tire pressure uncompensated) front left";
CM_ SG_ 2527679748 TPMS_SensPFrRi "Sensor measured pressure (tire pressure uncompensated) front right";
CM_ SG_ 2527679748 TPMS_SensPReLe "Sensor measured pressure (tire pressure uncompensated) rear left";
CM_ SG_ 2527679748 TPMS_SensPReRi "Sensor measured pressure (tire pressure uncompensated) rear right";
CM_ SG_ 2527679748 TPMS_SensSigAgeFrLe "Indicates the age of the sensor signal front left";
CM_ SG_ 2527679748 TPMS_SensSigAgeFrRi "Indicates the age of the sensor signal front right";
CM_ SG_ 2527679748 TPMS_SensSigAgeReLe "Indicates the age of the sensor signal rear left";
CM_ SG_ 2527679748 TPMS_SensSigAgeReRi "Indicates the age of the sensor signal rear right";
CM_ SG_ 2527679748 TPMS_SensStsFrLe "Own diagnostic of TPMS-Sensor front left";
CM_ SG_ 2527679748 TPMS_SensStsFrRi "Own diagnostic of TPMS-Sensor front right";
CM_ SG_ 2527679748 TPMS_SensStsReLe "Own diagnostic of TPMS-Sensor rear left";
CM_ SG_ 2527679748 TPMS_SensStsReRi "Own diagnostic of TPMS-Sensor rear right";
CM_ SG_ 2527679748 TPMS_SensTFrLe "Sensor measured temperature front left";
CM_ SG_ 2527679748 TPMS_SensTFrRi "Sensor measured temperature front right";
CM_ SG_ 2527679748 TPMS_SensTReLe "Sensor measured temperature rear left";
CM_ SG_ 2527679748 TPMS_SensTReRi "Sensor measured temperature rear right";
CM_ SG_ 2527679748 TPMS_SensTypFrLe "TPM sensor type front left";
CM_ SG_ 2527679748 TPMS_SensTypFrRi "TPM sensor type front right";
CM_ SG_ 2527679748 TPMS_SensTypReLe "TPM sensor type rear left";
CM_ SG_ 2527679748 TPMS_SensTypReRi "TPM sensor type rear right";
CM_ SG_ 2527679748 TPMS_TarPTmpDepFrLe "Temperature dependent target pressure front left";
CM_ SG_ 2527679748 TPMS_TarPTmpDepFrRi "Temperature dependent target pressure front right";
CM_ SG_ 2527679748 TPMS_TarPTmpDepReLe "Temperature dependent target pressure rear left";
CM_ SG_ 2527679748 TPMS_TarPTmpDepReRi "Temperature dependent target pressure rear right";
CM_ SG_ 2527679748 TPMS_Warn1 "General Warning Level 1";
CM_ SG_ 2527679748 TPMS_Warn1TireFrLe "Stage 1 warning for left front tires";
CM_ SG_ 2527679748 TPMS_Warn1TireFrRi "Stage 1 warning for left right tires";
CM_ SG_ 2527679748 TPMS_Warn1TireReLe "Stage 1 warning for left rear tires";
CM_ SG_ 2527679748 TPMS_Warn1TireReRi "Stage 1 warning for right front tires";
CM_ SG_ 2527679748 TPMS_Warn2 "General Warning Level 2";
CM_ SG_ 2527679748 TPMS_Warn2TireFrLe "Stage 2 warning for left front tires";
CM_ SG_ 2527679748 TPMS_Warn2TireFrRi "Stage 2 warning for right front tires";
CM_ SG_ 2527679748 TPMS_Warn2TireReLe "Stage 2 warning for left rear tires";
CM_ SG_ 2527679748 TPMS_Warn2TireReRi "Stage 2 warning for right rear tires";
CM_ SG_ 2527679748 TPMS_Warn3 "General Warning Level 3";
CM_ SG_ 2527679748 TPMS_Warn3TireFrLe "Stage 3 warning for left front tire";
CM_ SG_ 2527679748 TPMS_Warn3TireFrRi "Stage 3 warning for right front tire";
CM_ SG_ 2527679748 TPMS_Warn3TireReLe "Stage 3 warning for left rear tire";
CM_ SG_ 2527679748 TPMS_Warn3TireReRi "Stage 3 warning for right rear tire";
CM_ SG_ 2527679748 TPMS_Warn4 "General Warning Level 4";
CM_ SG_ 2527679748 TPMS_Warn4TireFrLe "Stage 4 warning for left front tyres";
CM_ SG_ 2527679748 TPMS_Warn4TireFrRi "Stage 4 warning for right front tyres";
CM_ SG_ 2527679748 TPMS_Warn4TireReLe "Stage 4 warning for left rear tyres";
CM_ SG_ 2527679748 TPMS_Warn4TireReRi "Stage 4 warning for right rear tyres";
CM_ SG_ 2527679748 TPMS_WarnAcoCalOk "Acoustic output for correct calibration (only necessary for switch calibration)";
CM_ SG_ 2527679748 TPMS_WarnCalOk "Text output for correct calibration (only necessary for switch calibration)";
CM_ SG_ 2527679748 TPMS_WarnCmftP "Warning when the comfort pressure is active";
CM_ SG_ 2527679748 TPMS_WarnFltIdc "Warning when the TPMS is in fault";
CM_ SG_ 2527679748 TPMS_WarnFr "Imbalance warning - front axle";
CM_ SG_ 2527679748 TPMS_WarnLmpStMil "Control of the TPMS lamp in the instrument cluster for system fault";
CM_ SG_ 2527679748 TPMS_WarnLmpStP "Control of the TPMS warning lamp  in the instrument cluster for pressure warning";
CM_ SG_ 2527679748 TPMS_WarnMaxV "Warning when the maximum speed for TPMS is active";
CM_ SG_ 2527679748 TPMS_WarnRaceTrckMdMinP "If the minimum pressure for race track mode is not reached, a warning should be displayed";
CM_ SG_ 2527679748 TPMS_WarnRe "Imbalance warning - rear axle";
CM_ SG_ 2527679748 TPMS_WarnSysLrn "Warning when the TPMS system is learning";
CM_ SG_ 2527679748 TPMS_WarnTmpFlt "Warning when the TPMS has a temporary fault";
CM_ SG_ 2527679748 TPMS_WarnWhlChgDet "Warning on wheel change detected";
CM_ SG_ 2527679748 TPMS_WhlChgDetFrLe "Wheel change front left detected";
CM_ SG_ 2527679748 TPMS_WhlChgDetFrRi "Wheel change front right detected";
CM_ SG_ 2527679748 TPMS_WhlChgDetReLe "Wheel change rear left detected";
CM_ SG_ 2527679748 TPMS_WhlChgDetReRi "Wheel change rear right detected";

CM_ SG_ 2527679742 Kam_Anf_Meldung "Über das Signal fordert die Funktion AEB-PR die Warnmeldungen an den Fahrer an.";
CM_ SG_ 2527679742 Kam_PaCo_MainState "Hauptzustand der Kundenfunktion AEB-PR

0 Init: AEB-PR befindet sich in der Initialisierung
1 InOperation_NoError: AEB-PR befindet sich im Betrieb ohne Fehler
2 Eingeschraenkt: AEB-PR ist eingeschraenkt verfügbar
7 Fehler: AEB-PR befindet sich im Feh";

CM_ SG_ 1525 RW_Gesamt_Reichweite "Reichweite für primär und sekundär Reichweite (eventuell Gewichtet)";
CM_ SG_ 1525 RW_Gesamt_Reichweite_Max_Anzeige "Angabe der Maximalen Anzeige der gesamten Reichweite.
Ergänzt das Signal RW_Gesamt_Reichweite_Anzeige.Die Einheit dieser Signal ist über RW_Reichweite_Einheit_Anzeige bereitgestellt.";
CM_ SG_ 1525 RW_Prim_Reichweitenv_Einheit "Für primäre  Reichweitenberechnung (KBI_Prim_Reichweitenverbrauch) zugrunde gelegte Einheit";
CM_ SG_ 1525 RW_Prim_Reichweitenverbrauch "Für primäre Reichweitenberechnung zugrunde gelegter Verbrauch";
CM_ SG_ 1525 RW_Primaer_Reichweite "Reichweite der primären Antriebsart";
CM_ SG_ 1525 RW_Reservewarnung_2_aktiv "Ansteuerung der Reservewarnung im Kombiinstrument (Leuchte und MFA-Warnhinweis). Wird gesetzt bei Erreichen / Unterschreiten eines unteren Reichweitenschwellwerts und zurückgenommen bei Erreich.
Zusätzlich erfolgt eine logische Verknüpfung mit einer akti";
CM_ SG_ 1525 RW_RWDS_Lastprofil "Lastprofil zur Bestimmung der notwendigen Nachladeenergie (Reichweitendurchschnittstrom)";

CM_ SG_ 1527 RW_Gesamt_Reichweite_Anzeige "Reichweite für primär und sekundär Reichweite (eventuell Gewichtet) zur Anzeige im Kombi. Die Einheit dieser Signal ist über RW_Reichweite_Einheit_Anzeige bereitgestellt.";
CM_ SG_ 1527 RW_Primaer_Reichweite_Anzeige "Reichweite der primären Antriebsart zur Anzeige im Kombi";
CM_ SG_ 1527 RW_Reichweite_Einheit_Anzeige "Einheit für Primaer-/Sekundaer-/Gesamt- Reichweite zur Anzeige im Kombi";
CM_ SG_ 1527 RW_Reservewarnung_aktiv "Ansteuerung der Reservewarnung im Kombiinstrument (Leuchte und MFA-Warnhinweis). Wird gesetzt bei Erreichen / Unterschreiten eines unteren Reichweitenschwellwerts und zurückgenommen bei Erreichen / Überschreiten eines oberen Reichweitenschwellwerts.";
CM_ SG_ 1527 RW_Sek_Reichweitenv_Einheit "Für sekundäre Reichweitenberechnung (KBI_Sek_Reichweitenverbrauch) zugrunde gelegte Einheit";
CM_ SG_ 1527 RW_Sek_Reichweitenverbrauch "Für sekundäre Reichweitenberechnung zugrunde gelegter Verbrauch";
CM_ SG_ 1527 RW_Sekundaer_Reichweite "Reichweite der sekundaeren Antriebsart";
CM_ SG_ 1527 RW_Sekundaer_Reichweite_Anzeige "Reichweite der sekundaeren Antriebsart zur Anzeige im Kombi";
CM_ SG_ 1527 RW_Tendenz "Signalisierung der RW-Tendenz auf Basis der aktuellen Fahrweise. ";
CM_ SG_ 1527 RW_Texte "Signal zum Steuern von reichweitenbezogenen Hinweistexten für Pop-Up Anzeigen im Kombiinstrument";

CM_ SG_ 1322 RES_AlQuitRem "Alarm Quit Remote";
CM_ SG_ 1322 RES_ServComp "Service component to reset";
CM_ SG_ 1322 RES_TripReset "require ACKNOWLEDGE response";

CM_ SG_ 2331596042 RHP_02_BZ "4bit Botschaftszähler, wird mit jeder Sendebotschaft inkrementiert";
CM_ SG_ 2331596042 RHP_02_CRC "Für MLB:
Berechnung siehe Lastenheft 'Kommunikationsabsicherung für FlexRay und CAN'
Ab MQB und MLBevo:
Berechnung siehe Lastenheft 'End-to-End Kommunikationsabsicherung'

Endwerte siehe Begleitdokument 'S-PDU Kennungsfolgen'";
CM_ SG_ 2331596042 RHP_Abstand_CIO "VW: Anzeige des gemessenen Abstands zum Einschererobjekt (CIO) als Entfernung von der Hinterachse des Egofahrzeugs";
CM_ SG_ 2331596042 RHP_Abstand_LNS "VW: Anzeige des gemessenen Abstands zum linkten Nebenspurobjekt (RNS) als Entfernung von der Hinterachse des Egofahrzeugs";
CM_ SG_ 2331596042 RHP_Abstand_RNS "VW: Anzeige des gemessenen Abstands zum rechten Nebenspurobjekt (RNS) als Entfernung von der Hinterachse des Egofahrzeugs";
CM_ SG_ 2331596042 RHP_Abstand_WZO "VW: Anzeige des gemessenen Abstands zum Zielobjekt (WZO) als Entfernung von der Hinterachse des Egofahrzeugs";
CM_ SG_ 2331596042 RHP_Abstandsindex "Für die optionale Anzeige einer einheitenlosen Abstandsreserve oder einer gemessenen Zeitlücke in der Zusatzanzeige. Der Wertebereich 1..1021 entspricht aktiv_Folgefahrt";
CM_ SG_ 2331596042 RHP_aktiv_HMI "Signalwert an Anzeigegerät welche Funktion aktiv";
CM_ SG_ 2331596042 RHP_Anzeige_Maximalabstand "VW: Zur Skalierung der Anzeige auf die maximale Reichweite (geschwindigkeitsabhängig) als Entfernung von der Hinterachse des Egofahrzeugs";
CM_ SG_ 2331596042 RHP_Anzeige_Objektregelung "VW: Hervorhebung relevantes Regelobjekt in der ACC-Anzeige";
CM_ SG_ 2331596042 RHP_Anzeige_Zeitluecke "Anforderung zur Umschaltung zwischen dem Anzeigemodus 'Keine Änderung Zeitlücke' und 'Änderung Zeitlücke' (z.B. Pfeildarstellung in Zusatzanzeige)";
CM_ SG_ 2331596042 RHP_CIO "VW: Anzeige des Einschererobjektes (CIO)";
CM_ SG_ 2331596042 RHP_EGO_Fahrzeug "Ansteuerung einer Statusanzeige für RHP in verschiedenen Farben";
CM_ SG_ 2331596042 RHP_Einheit_maxSetzgeschw "Einheit zu Signal RHP_maxSetzgeschw";
CM_ SG_ 2331596042 RHP_ErrorStatus "Fehler im Modus Rush Hour Pilot";
CM_ SG_ 2331596042 RHP_FoD_Status "Informiert Kombi, ob die RHP-Funktion freigeschaltet ist oder nicht.";
CM_ SG_ 2331596042 RHP_Gesetzte_Zeitluecke "Zusatzanzeige: 0 = aus / ungleich 0 = ein;";
CM_ SG_ 2331596042 RHP_Gong "Löst ein definiertes akustisches Signal aus.";
CM_ SG_ 2331596042 RHP_HMI_DetectedLane "Anzeige für die Durchführung eines Spurwechsels im Kombi, Highlight von Spur";
CM_ SG_ 2331596042 RHP_HMI_Ego_li_Anzeige "Umfeldvisualisierung des RHP: Farbe der Spurlinie";
CM_ SG_ 2331596042 RHP_HMI_Ego_li_Seg1_QuerAbst "Umfeldvisualisierung des RHP: Querabstand der linken Egospur (bezogen auf Fahrzeug USK)";
CM_ SG_ 2331596042 RHP_HMI_Ego_li_Typ "Umfeldvisualisierung des RHP: Typ der linken Egospur";
CM_ SG_ 2331596042 RHP_HMI_Ego_re_Anzeige "Umfeldvisualisierung des RHP: Farbe der Spurlinie";
CM_ SG_ 2331596042 RHP_HMI_Ego_re_Seg1_QuerAbst "Umfeldvisualisierung des RHP: Querabstand der rechten Egospur (bezogen auf Fahrzeug USK)";
CM_ SG_ 2331596042 RHP_HMI_Ego_re_Typ "Umfeldvisualisierung des RHP: Typ der rechten Egospur";
CM_ SG_ 2331596042 RHP_HMI_EgoObj_dy "Umfeldvisualisierung des RHP: Prozentuale Position des Egofahrzeugs innerhalb der eigenen Spur";
CM_ SG_ 2331596042 RHP_HMI_Kurvenwarnung "Umfeldvisualisierung des RHP: Darstellung einer Kurvenwarnung";
CM_ SG_ 2331596042 RHP_HMI_LaneChangeIndicator "Anzeige für die Durchführung eines Spurwechsels im Kombi, Zeigen der Spurwechsel-Indikator";
CM_ SG_ 2331596042 RHP_HMI_LaneChangeTrajectory "Anzeige für die Durchführung eines Spurwechsels im Kombi, Highlight von Spurwechselpfeil";
CM_ SG_ 2331596042 RHP_HMI_Nachb_li_Anzeige "Umfeldvisualisierung des RHP: Farbe der Spurlinie";
CM_ SG_ 2331596042 RHP_HMI_Nachb_li_Seg1_QuerAbst "Umfeldvisualisierung des RHP: Querabstand der linken Nachbarspur (bezogen auf Fahrzeug USK)";
CM_ SG_ 2331596042 RHP_HMI_Nachb_li_Typ "Umfeldvisualisierung des RHP: Typ der linken Nachbarspur";
CM_ SG_ 2331596042 RHP_HMI_Nachb_re_Anzeige "Umfeldvisualisierung des RHP: Farbe der Spurlinie";
CM_ SG_ 2331596042 RHP_HMI_Nachb_re_Seg1_QuerAbst "Umfeldvisualisierung des RHP: Querabstand der rechten Nachbarspur (bezogen auf Fahrzeug USK)";
CM_ SG_ 2331596042 RHP_HMI_Nachb_re_Typ "Umfeldvisualisierung des RHP: Typ der rechten Nachbarspur";
CM_ SG_ 2331596042 RHP_LateralLamp "Anzeige Rush Hour Pilot-Lateralleuchte im Kombi";
CM_ SG_ 2331596042 RHP_maxSetzgeschw "maximale RHP-Setzgeschwindigkeit zur Ansteuerung des RHP-Setzbereichs im Kombi
Hinweis: Signal ist mit Signal RHP_Einheit_maxSetzgeschw zu interpretieren";
CM_ SG_ 2331596042 RHP_Regelgeschw "Zur Anzeige der Regelgeschwindigkeit (z.B. Kurven- / Tempolimitassistent) im Kombiinstrument";
CM_ SG_ 2331596042 RHP_Relevantes_Objekt "Ansteuerung einer primären Anzeige 'Relevantes Objekt' für RHP in verschiedenen Farben.";
CM_ SG_ 2331596042 RHP_Sollabstand_1 "VW: Anzeige der Fahrerwunschzeitlücke 1 zum Zielobjekt (WZO) als Entfernung von der Hinterachse des Egofahrzeugs";
CM_ SG_ 2331596042 RHP_Sollabstand_2 "VW: Anzeige der Fahrerwunschzeitlücke 2 zum Zielobjekt (WZO) als Entfernung von der Hinterachse des Egofahrzeugs";
CM_ SG_ 2331596042 RHP_Sollabstand_3 "VW: Anzeige der Fahrerwunschzeitlücke 3 zum Zielobjekt (WZO) als Entfernung von der Hinterachse des Egofahrzeugs";
CM_ SG_ 2331596042 RHP_Sollabstand_4 "VW: Anzeige der Fahrerwunschzeitlücke 4 zum Zielobjekt (WZO) als Entfernung von der Hinterachse des Egofahrzeugs";
CM_ SG_ 2331596042 RHP_Sollabstand_5 "VW: Anzeige der Fahrerwunschzeitlücke 5 zum Zielobjekt (WZO) als Entfernung von der Hinterachse des Egofahrzeugs";
CM_ SG_ 2331596042 RHP_StatusLamp "Anzeige Rush Hour Pilot-Statusleuchte im Kombi";
CM_ SG_ 2331596042 RHP_Tempolimit "Anzeige einer Tempolimit-Vorgabe (Geschwindigkeitsbegrenzung, Aufhebung einer Geschwindigkeitsbegrenzung)";
CM_ SG_ 2331596042 RHP_Tempolimit_Einheit "Einheit des Verkehrszeichen in RHP_Tempolimit";
CM_ SG_ 2331596042 RHP_Tempolimit_Farbe "Umschaltung der Farbe der angezeigten Tempolimit";
CM_ SG_ 2331596042 RHP_Text_01 "Anzeige Rush Hour Pilot-Texte im Kombi, FuSi relevant";
CM_ SG_ 2331596042 RHP_Text_02 "Anzeige Rush Hour Pilot-Texte im Kombi";
CM_ SG_ 2331596042 RHP_Texte_Sekundaeranz "Anzeige ACC Informationen, wie z.B. die Vorankündigung, oder die Anfahrbereitschaft";
CM_ SG_ 2331596042 RHP_TOR_Lamp "Anfordern der Anzeige des LAHO-Icon in verschiedenen Zuständen";
CM_ SG_ 2331596042 RHP_Typ_CIO "VW: Anzeige der Klasse des Einschererobjektes (CIO)";
CM_ SG_ 2331596042 RHP_Typ_LNS "VW: Anzeige der Klasse des linken Nebenspurobjektes (LNS)";
CM_ SG_ 2331596042 RHP_Typ_RNS "VW: Anzeige der Klasse des rechten Nebenspurobjektes (RNS)";
CM_ SG_ 2331596042 RHP_Typ_WZO "VW: Anzeige der Klasse des Zielobjektes (WZO)";
CM_ SG_ 2331596042 RHP_Wunschgeschw "Zur Anzeige der Wunschgeschwindigkeit im Kombiinstrument";
CM_ SG_ 2331596042 RHP_Wunschgeschw_Farbe "Umschaltung der Farbe der angezeigten Setzgeschwindigkeit im Tacho";

CM_ SG_ 1610 RKA_FMVSS138_Lampe "Kein Einsatz RKA im D4 Hybrid";
CM_ SG_ 1610 RKA_FMVSS138_MIL "Zentral blinkend für 1 Minute immer nur gelbe Lampe, dann statisch an. 

Kein Einsatz RKA im D4 Hybrid";
CM_ SG_ 1610 RKA_Reifentyp "Ausgabe von Reifentyp";
CM_ SG_ 1610 RKA_Warnungen_02 "Ansteuerung der Warnungen (Texte, Töne, Lampen) im Kombi für Funktion RKA+

Kein Einsatz RKA im D4 Hybrid";

CM_ SG_ 1440 LS_defekt "Fehlererkennung Lichtsensor
";
CM_ SG_ 1440 LS_Helligkeit_FW "Vorfeldhelligkeit";
CM_ SG_ 1440 LS_Helligkeit_IR "Globalfeldhelligkeit";
CM_ SG_ 1440 LS_Verbau "Verbauinfo Lichtsensor";
CM_ SG_ 1440 RLS_Vorfeldhelligkeit_Boost "erweiterte Helligkeitssensierung für HUD";
CM_ SG_ 1440 RS_defekt "Fehlererkennung Regensensor";
CM_ SG_ 1440 RS_Regenmenge "Regenmenge";
CM_ SG_ 1440 RS_Schwall "Schwallereignis";
CM_ SG_ 1440 RS_Verbau "Verbauinfo Regensensor";
CM_ SG_ 1440 RS_Verglasung_schliessen "Anforderung: Verglasung schliessen
";
CM_ SG_ 1440 RS_Wischergeschwindigkeit "Wischergeschwindigkeit (Hübe/min)";
CM_ SG_ 1440 SLS_Helligkeit_IR "Helligkeitswert des 'Smart-Light-Sensor' im Dashboard analog / alternativ zu LS_Helligkeit_IR.

Es ist entweder ein RLS_LIN oder ein Smart-LS im FZG verbaut.";

CM_ SG_ 2584746776 SACID_1_AuthTime_Req_Data "AuthTime - Authentische Zeit
ISO-TP Datenkanal - NA2FID

SACID_1 an Funktion Authentische Zeit (Request)";

CM_ SG_ 2584877848 SACID_1_AuthTime_Resp_Data "AuthTime - Authentische Zeit
ISO-TP Datenkanal - NA2FID
Response Funktion 0x18 AuthTime

Funktion Authentische Zeit an SACID_1 (Response)";

CM_ SG_ 1504 MD1_Lage "Lage Schiebedachstellung 1 (Signal wird 1:1 vom BCM2 geroutet; ursprünglicher Sender: SAD = LIN-Slave vom BCM2)";
CM_ SG_ 1504 MD1_Position "Aktuelle Öffnungsweite Schiebedach.";
CM_ SG_ 1504 MD3_Lage "Lage Schiebedachstellung 3 
(Signal wird 1:1 vom BCM2 geroutet; ursprünglicher Sender: SAD = LIN-Slave vom BCM2) 
";
CM_ SG_ 1504 MD3_Position "Schiebedachstellung 3 
(Signal wird 1:1 vom BCM2 geroutet; ursprünglicher Sender: SAD = LIN-Slave vom BCM2)
";
CM_ SG_ 1504 MRollo_Lage "Lage Rollo
(Signal wird 1:1 vom BCM2 geroutet; ursprünglicher Sender: Rollo = LIN-Slave vom BCM2)";
CM_ SG_ 1504 MRollo_Position "Aktuelle Öffnungsweite des Dachrollos.";
CM_ SG_ 1504 Rollo_normiert "Anzeigen Normierung des Dachrollos";
CM_ SG_ 1504 Rollo_Thermoschutz "Anzeigen aktivierter Thermoschutz des Dachrollo";
CM_ SG_ 1504 Rollo_UEKB_aktiv "Anzeigen aktivierter Überschusskraftbegrenzung des Dachrollos";
CM_ SG_ 1504 SAD_Anf_ESC_Zuschaltung "Zwangsaktivierung ESP durch SAD-SG (bei geöffnetem Schiebedach und V> xx km/h).";
CM_ SG_ 1504 SAD_normiert "Anzeige Normierung des Schiebeausstelldaches";
CM_ SG_ 1504 SAD_Taster_Deckel_hi "Taster für SAD Deckel hinten";
CM_ SG_ 1504 SAD_Taster_Deckel_vo "Taster für SAD Deckel vorne";
CM_ SG_ 1504 SAD_Taster_Rollo_hi "Taster für SAD Rollo hinten";
CM_ SG_ 1504 SAD_Taster_Rollo_vo "Taster für SAD Rollo vorne";
CM_ SG_ 1504 SAD_Thermoschutz "Anzeige aktivierter Thermoschutz des Schiebeausstelldaches";
CM_ SG_ 1504 SAD_UEKB_aktiv "Anzeige aktivierter Überschusskraftbegrenzung des Schiebeausstelldaches";

CM_ SG_ 2463978605 SCode_Data "Komfortcodierung
Antwort auf Komfort-Radio-Request
Security Acces_Mode_2
Timeout, siehe Radio-spec.";
CM_ SG_ 2463978605 SCode_Target "Komfortcodierung
Adresse des anfragenden Teilnehmers
Zieladresse Security_Request";

CM_ SG_ 1522 KBI_Dimmpoti "Signal wird benötigt für Dimmung im Audi B8. Der Signalfluss erfolgt vom Kombi an das BCM1.";
CM_ SG_ 1522 KBI_Phototransistor "Signal wird benötigt für die Dimmung von Such- Funktions- und Displaybeleuchtungen. Der Signalfluss erfolgt vom Steuergerät mit Fotosensor an die jeweiligen Dimmmaster-Steuergeräte.

Für Audi B8/Q5 und D4/C7/VW526 vor PA: 
0xFE Phototransistor nicht ve";

CM_ SG_ 1167 SK1_Key_Data_1 "1. Multiplexbotschaft der Service-Key Funktion";
CM_ SG_ 1167 SK1_Key_Data_10 "10. Multiplexbotschaft der Service-Key Funktion";
CM_ SG_ 1167 SK1_Key_Data_2 "2. Multiplexbotschaft der Service-Key Funktion";
CM_ SG_ 1167 SK1_Key_Data_3 "3. Multiplexbotschaft der Service-Key Funktion";
CM_ SG_ 1167 SK1_Key_Data_4 "4. Multiplexbotschaft der Service-Key Funktion";
CM_ SG_ 1167 SK1_Key_Data_5 "5. Multiplexbotschaft der Service-Key Funktion";
CM_ SG_ 1167 SK1_Key_Data_6 "6. Multiplexbotschaft der Service-Key Funktion";
CM_ SG_ 1167 SK1_Key_Data_7 "7. Multiplexbotschaft der Service-Key Funktion";
CM_ SG_ 1167 SK1_Key_Data_8 "8. Multiplexbotschaft der Service-Key Funktion";
CM_ SG_ 1167 SK1_Key_Data_9 "9. Multiplexbotschaft der Service-Key Funktion";
CM_ SG_ 1167 SK1_MUX "Multiplexer-Signal der Service-Key Botschaft";

CM_ SG_ 980 BH_Blinker_Fehler "Anzeige, ob am Lenkstockschalter ein Fehler anliegt.
Notwendig aufgrund ASIL-Einstufung";
CM_ SG_ 980 BH_Blinker_li "Blinkerhebel Richtung links";
CM_ SG_ 980 BH_Blinker_re "Blinkerhebel Richtung rechts";
CM_ SG_ 980 BH_Fernlicht "Betaetigung Fernlicht
";
CM_ SG_ 980 BH_Lichthupe "Betaetigung Lichthupe
";
CM_ SG_ 980 FAS_Taster "Betaetigung FAS Taster
";
CM_ SG_ 980 FAS_Taster_Fehler "Fehlerstatus FAS Taster
";
CM_ SG_ 980 LRH_aktiv "Signal gibt an, ob ein Heizstrom durch die Lenkradheizung fließt. Es dient der Auswertung durch das Energiemanagement.";
CM_ SG_ 980 LRH_On_Off "Status Lenkradheizung";
CM_ SG_ 980 LSS_Tastencode "0x00 = No key pressed / key released
0x01 = Menu
0x02 = Menu Up / Next Screen
0x03 = Menu Down / Previous Screen
0x04 = Up
0x05 = Down
0x06 = Up / Down ThumbWheel
0x07 = OK (ThumbWheel-Button)
0x08 = Cancel / Escape
0x09..0x0F = reserved for furt";
CM_ SG_ 980 SMLS_01_BZ "4bit Botschaftszaehler, wird mit jeder Sendebotschaft inkrementiert";
CM_ SG_ 980 SMLS_01_CRC "Für MLB:
'Berechnung siehe Lastenheft 'Kommunikationsabsicherung für FlexRay und CAN''

Ab MQB und MLBevo:
'Berechnung siehe Lastenheft 'End-to-End Kommunikationsabsicherung''

Endwerte siehe Begleitdokument 'S-PDU Kennungsfolgen'";
CM_ SG_ 980 SMLS_Hupe "Betaetigung Hupe
";
CM_ SG_ 980 SMLS_P_verriegelt "Signal stellt den Status des Signals P-verriegelt auf den Fahrzeugbus zur Verfügung. Nutzer sind z.B. die ELV, die das Signal für die Verriegelung benötigt und die Funktion Verlassenswarnung, die den Fahrer beim Verrollen des Fahrzeugs warnt.";
CM_ SG_ 980 SMLS_P_verriegelt_plausibel "Signal stellt den Plausibilisierungstatus des Signals p_verriegelt auf den Fahrzeugbus zur Verfügung. Eine Plausibilität muss explizit erkannt werden. Initial wird 'unplausibel' gesendet. Ein plausibles Signal wird erkannt, wenn p_verriegelt plausibel geg";
CM_ SG_ 980 SMLS_PTT "Betaetigung PTT";
CM_ SG_ 980 WH_Frontwaschen "Wischerhebel: Stellung Wisch Wasch vorne
";
CM_ SG_ 980 WH_Heckintervall "Wischerhebel: Stellung Heckintervall
";
CM_ SG_ 980 WH_Heckwaschen "Wischerhebel: Stellung Wisch Wasch hinten
";
CM_ SG_ 980 WH_Intervall "Wischerhebel: Stellung Intervall
";
CM_ SG_ 980 WH_Intervallstufen "Wischerhebel: Stellung Intervallstufen";
CM_ SG_ 980 WH_SRA "Scheinwerferreinigungsanlage

derzeit nur bei PAG umgesetzt";
CM_ SG_ 980 WH_Tipwischen "Wischerhebel: Tippwischen

MQB A0/ PQ26: Bei Verbau LSS (kein SMLS): gespiegelter Wert zu Signal WH_WischerStufe1";
CM_ SG_ 980 WH_Tipwischen_lang "Wischerhebel: Tippwischen lang
(dient zur Auswertung für die Unterscheidung Tippwischen oder Serviceposition Wischer)";
CM_ SG_ 980 WH_Wischer_Fehler "Anzeige, ob am Lenkstockschalter ein Fehler anliegt.
Notwendig aufgrund ASIL-Einstufung";
CM_ SG_ 980 WH_WischerStufe1 "Wischerhebel: Stufe Wischen 1
";
CM_ SG_ 980 WH_WischerStufe2 "Wischerhebel: Stufe Wischen 2
";

CM_ SG_ 2464157740 SOK_FoD_MFG_Req_Challenge "Challenge im Rahmen des SOK Challenge-Response Protokolls.

Geschützte Funktion: Function on Demand
Signal: FoD_MFG_Req_Data (GW-> KFG)";

CM_ SG_ 2464288812 SOK_FoD_MFG_Resp_Challenge "Challenge im Rahmen des SOK Challenge-Response Protokolls.

Geschützte Funktion: Function on Demand
Signal: FoD_MFG_Resp_Data (KFG -> GW)";

CM_ SG_ 2589283756 SOK_ungeschuetzte_Zeit "Periodisch verschickter SOK Zeitwert des SOK Zeitmasters als Referenzzeit zur Erkennung von Clockjitter durch andere SOK Teilnehmer.

Der Empfang dieses Signals ist verpflichtend für jedes Steuergerät, das durch die authentische Broadcast Funktionalität";

CM_ SG_ 2464153620 SOK_Zeit_Kombi_Challenge "Challenge im Rahmen des SOK Challenge-Response Protokolls.

Geschützte Funktion: Empfang der SOK-Zeit vom SOK-Zeitmaster; verbindlich für Steuergeräte, welche mit der durch SOK geschützten Broadcast Nachrichten empfangen oder versenden";

CM_ SG_ 2464284692 SOK_Zeit_Kombi_Signatur "SOK_Zeit_Kombi_Signatur";

CM_ SG_ 2464288788 SOK_Zeit_Kombi_Zeit "Aktueller Wert der SOK-Zeit des SOK-Zeitmasters; geschützt durch das SOK Challenge-Response Protokoll";

CM_ SG_ 2464153644 SOK_Zeit_MFG_Challenge "Challenge im Rahmen des SOK Challenge-Response Protokolls.

Geschützte Funktion: Empfang der SOK-Zeit vom SOK-Zeitmaster; verbindlich für Steuergeräte, welche mit der durch SOK geschützten Broadcast Nachrichten empfangen oder versenden";

CM_ SG_ 2464284716 SOK_Zeit_MFG_Signatur "Signatur im Rahmen des SOK Challenge-Response Protokolls.

Geschützte Funktion: Empfang der SOK-Zeit vom SOK-Zeitmaster; verbindlich für Steuergeräte, welche mit der durch SOK geschützten Broadcast Nachrichten empfangen oder versenden";
CM_ SG_ 2464284716 SOK_Zeit_MFG_Zeit "Aktueller Wert der SOK-Zeit des SOK-Zeitmasters; geschützt durch das SOK Challenge-Response Protokoll";

CM_ SG_ 1467 SoSe_SunInt_2D_Li "Sonnenintensität links (2D Sensor)";
CM_ SG_ 1467 SoSe_SunInt_2D_Re "Sonnenintensität rechts (2D Sensor)";

CM_ SG_ 2527679739 STK_AirCLeaner_Anf "Anforderung an das Klimasteuergerät dien Zustand der Umluftklappe zu ändern.";
CM_ SG_ 2527679739 STK_Anf_AussenspiegelHZ "Anforderung Außenspiegelheizung seitens Klimafunktion (z.B. bei Erweiterter VoKo)";
CM_ SG_ 2527679739 STK_Berechnungsphase "Status der Berechnungsphase Vorkonditionierung.

0 = keine Berechnungsphase
1 = Berechnungsphase erforderlich
2 = Init
3 = Fehler";
CM_ SG_ 2527679739 STK_Betriebsdauer "Betriebsdauer (TimeRemaining) Standklima Frontend";
CM_ SG_ 2527679739 STK_ErwVK_Anf "Anforderung  zur Aktivierung der Erweiterten-Vorkonditionierung  im  Innenraum";
CM_ SG_ 2527679739 STK_ErwVK_Beifahrerzone "Erweiterte Voko Beifahrerseite";
CM_ SG_ 2527679739 STK_ErwVK_Fahrerzone "Erweiterte Voko Fahrerseite";
CM_ SG_ 2527679739 STK_ErwVK_Heckzone2_links "Anforderung der erweiterten Standklimatisierung in der dritten Sitzreihe links";
CM_ SG_ 2527679739 STK_ErwVK_Heckzone2_rechts "Anforderung der erweiterten Standklimatisierung für die dritte Sitzreihe rechts.";
CM_ SG_ 2527679739 STK_ErwVK_Heckzone_links "Erweiterte Voko Sitzheizung hinten links";
CM_ SG_ 2527679739 STK_ErwVK_Heckzone_rechts "Erweiterte Voko Sitzheizung hinten rechts";
CM_ SG_ 2527679739 STK_ErwVK_Modus "Erweiterte Voko angefordert";
CM_ SG_ 2527679739 STK_ErwVK_Scheibenheizung "Erweiterte Voko Scheibenheizung Freigabe";
CM_ SG_ 2527679739 STK_FSH_Anf "Frontscheibenheizung anfordern";
CM_ SG_ 2527679739 STK_GesamtEnergiebedarf "Für den Klimavorgang benötigte Energie von ca. 15 kWh für Signal 
STK_GesamtEnergiebedarf";
CM_ SG_ 2527679739 STK_HSH_Anf "Heckscheibenheizung anfordern";
CM_ SG_ 2527679739 STK_Klima_Temp "MEB: Gewünschte Innenraumtemperatur, auf die bei der Standklimatisierung geregelt werden soll.
MQB: Temperatur die vom Nutzer vorgewählt wurde (VW: low=15,5 °C/ high=30,0°C)";
CM_ SG_ 2527679739 STK_KurzVK_Anf "Anforderung der kurz-Vorkonditionierung  zur Aktivierung der Vorkonditionierung Innenraum";
CM_ SG_ 2527679739 STK_MaxLeistung "Anforderung an  HVLM über den Maximalwert der angeforderten Energieleistung für Klima-Vorkonditionierung";
CM_ SG_ 2527679739 STK_Standklima_Anf "Anforderung der Vorkonditionierung zur Aktivierung der Vorkonditionierung Innenraum";
CM_ SG_ 2527679739 STK_Standklima_Timer_Status "Signalisierung an die Klima Black Box ob mind. ein Timer zur Standklimatisierung programmiert ist";
CM_ SG_ 2527679739 STK_Stecker_Status "Übermittlung Status des Ladesteckers für das Klima Steuergerät";
CM_ SG_ 2527679739 STK_VK_Modus "Übermittlung des aktuellen Konditionierungs-Status für HMI, Mobile Online Dienste";
CM_ SG_ 2527679739 STK_VK_STH_Einsatz "Anforderung(STK) an CCM zur Freigabe der Standheizung";
CM_ SG_ 2527679739 STK_VK_Timer_Status "Statusmeldung an BMCe zum Vorkonditionierungsmodus, zur Aktivierung der Vorkonditionierung der HV-Batterie.
'aktiv' = falls die Batterie einen Kühl-/Heizbedarf festgestellt hat, darf diese Batterie darf diese eine HV-Aktivierung anfordern und die Batteri";
CM_ SG_ 2527679739 STK_Voko_LED "Signalisierung des Standheizungsbetriebs";

CM_ SG_ 1313 STH_EKP_Anst "STH sendet die Anforderung zur Ansteuerung der EKP an den Motor, um Kraftstoffbehälter der STH zu befüllen.";
CM_ SG_ 1313 STH_Fehler_ElWaPu "Fehler der el. Zusatzwasserpumpe der zur Deaktivierung der Wasserpumpe führt ";
CM_ SG_ 1313 STH_Fehlerstatus "Übermittlung der unterschiedlichen Fehlerzustände der Standheizung";
CM_ SG_ 1313 STH_Funk_aus "Funkbefehl über Funkfernbedienung zum Ausschalten Standheizung";
CM_ SG_ 1313 STH_Funk_ein "Funkbefehl über Funkfernbedienung zum Einschalten Standheizung";
CM_ SG_ 1313 STH_Geblaese "Ein-/ Ausschaltbefehl an die Klimaanlage, Gebläse";
CM_ SG_ 1313 STH_Heizleistung "Heizleistung in %";
CM_ SG_ 1313 STH_KL_HUP "Signal HUP Aktivierung an Klima

0 = HUP aus
1 = HUP ein";
CM_ SG_ 1313 STH_KVS "Kraftstoffverbrauch";
CM_ SG_ 1313 STH_KVS_Ueberlauf "Kraftstoffverbrauch, Überlauf hat stattgefunden";
CM_ SG_ 1313 STH_LED "Funktionslampe";
CM_ SG_ 1313 STH_Motorvorwaermung "Info an der Motor, dass der Aufheizvorgang mit Motorvorwärmung erfolgt ist";
CM_ SG_ 1313 STH_Pumpen_Anf_extern "Anforderung der motorseitigen elektr. (externen) Wasserpumpe zur Kreislaufunterstützung im Standheizbetrieb";
CM_ SG_ 1313 STH_Servicemode "Rückmeldung, dass die Standheizung sich gerade im Diagnosemodus befindet, gestartet über Diagnosetester";
CM_ SG_ 1313 STH_SH_ZH "0 = Heizgerät ist Standheizung
1 = Heizgerät ist Zuheizer
Gerätekennung WZH oder ZH
";
CM_ SG_ 1313 STH_Start_folgt "Thema Start/Stop: Im Stop-Modus muß das KBT einen Wiederstart anfordern, da ein STH-Start notwendig ist.";
CM_ SG_ 1313 STH_Texte "Anforderung der unterschiedlichen Anzeigetexte im Mitteldisplay des Kombi.

0: Keine Anzeige
1: Kein Standheizungs- bzw Lueftungsbetrieb wegen Batteriemanagementeinschraenkung
2: Kein Standheizungs- bzw Lueftungsbetrieb wegen Kraftstoffmangels
3: Kei";
CM_ SG_ 1313 STH_Ventil_Status "Statusrückmeldung Ansteuerung 3/2 Wege-Ventil";
CM_ SG_ 1313 STH_Ventiloeffnungszeit "Die Standheizung sendet an den Motor die Information darüber wie lange das Magnetventil die Wasserkreisläufe von 'klein' aus 'gross' geschaltet hat. ";
CM_ SG_ 1313 STH_Waermeeintrag "Signal enthält die Brenndauer in 1min-Schritten, über welche die Standheizung gelaufen ist";
CM_ SG_ 1313 STH_war_aktiv "Bit beeinhaltet die Info, dass die Standheizung während der letzten halbe Stunde aktiv war.";
CM_ SG_ 1313 STH_Wassertemp "Kühlmitteltemperatur der Standheizung";
CM_ SG_ 1313 STH_Zusatzheizung "Kraftstoffzuheizer aktiv";

CM_ SG_ 1413 GW_KD_Fehler "Kundendienstfehlerbit Gateway zur Anzeige eines im Gateway abgelegten Fehlerspeichereintrages.";
CM_ SG_ 1413 SI_BUS_01 "MQB/MQB_A0/PQ26: ACAN
MQB2020: ACAN(FD)
MLBevo: HCAN
E3_Volumen: ACAN(FD)
MQBw_Baseline: ACAN(FD)";
CM_ SG_ 1413 SI_BUS_02 "MQB/MQB A0 Standard+, High: FCAN
MQB2020: FCAN(FD)
MLBevo: Frei
E3_Volumen: FCAN(FD)
MQBw_Baseline: FCAN(FD)";
CM_ SG_ 1413 SI_BUS_03 "MQB/MQB A0/PQ26: KCAN
MQB2020: KCAN
MLBevo: KCAN
E3_Volumen: KCAN(HS) / K2CAN(FD) (Buskopplung)
MQBw_Baseline: KCAN(HS)";
CM_ SG_ 1413 SI_BUS_04 "MQB/MQB A0 Standard+, High: ICAN
MQB2020: ICAN(HS)
MLBevo: ICAN
E3_Volumen: ABCAN(FD)
MQBw_Baseline: ICAN(HS)";
CM_ SG_ 1413 SI_BUS_05 "MQB/MQB A0/PQ26: DiagCAN
MQB2020: DiagCAN(FD)
MLBevo: DiagCAN
E3_Volumen: DiagCAN(FD)
MQBw_Baseline: DiagCAN(FD)";
CM_ SG_ 1413 SI_BUS_06 "MQB/MQB A0/PQ26: ECAN
MQB2020: FASCAN(FD)
MLBevo: ECAN
E3_Volumen: FASCAN_1(FD)
MQBw_Baseline: FASCAN_1(FD)";
CM_ SG_ 1413 SI_BUS_07 "MQB: LIN1 (Energie)
MQB2020: LIN1 (Energie)
MLBevo: LIN1 (Energie)
E3_Volumen: LIN 1 (Energie)
MQBw_Baseline: LIN1 (Energie)";
CM_ SG_ 1413 SI_BUS_08 "MQB: LIN2 (MFL)
MQB2020: LIN2 (MFL)
MLBevo: LIN2 (MFL)
E3_Volumen: LIN2 (MFL)
MQBw_Baseline: LIN2 (MFL)";
CM_ SG_ 1413 SI_BUS_09 "MQB: LIN3 (unbelegt)
MQB2020: LIN3 (Uhr/FES)
MLBevo: LIN3 (Energie2)
MEB: LIN3
E³ 1.1 UNECE: MDKCAN";
CM_ SG_ 1413 SI_BUS_10 "MLBevo: Flexray
MQB2020: MCAN
MQBw_Baseline: FASCAN_2(FD)
E³ 1.1 UNECE: FASCAN_2(FD)";
CM_ SG_ 1413 SI_BUS_11 "MLBevo: Ethernet
MEB: LIN4";
CM_ SG_ 1413 SI_BUS_12 "MQB: unbelegt
MLBevo: K2CAN
E3_Volumen: MFLCAN
MQBw_Baseline: K2CAN(FD)";
CM_ SG_ 1413 SI_BUS_13 "MQB: unbelegt
MLBevo: DCAN
MEB: CCAN
MQBw_Baseline: K3CAN(FD)";
CM_ SG_ 1413 SI_BUS_14 "MQB/MQB A0: unbelegt
MQB2020: HCAN
MLBevo: CCAN
E3_Volumen: EVCAN(FD)
MQBw_Baseline: EVCANFD(FD)";
CM_ SG_ 1413 SI_BUS_15 "MQB: frei
MQB2020: frei
MLBevo: frei
MEB: AFSCAN";
CM_ SG_ 1413 SI_Bus_Identifikation "Das Signal identifiziert den Bus eindeutig. Das Signal ist konstant auf jedem Bus.
Der Signalwert entspricht dem Wert 'Busnummer' aus der VW80127 Gateway_component_list_databus_identification (0x2A2D) 'Bus-Identifier'.";
CM_ SG_ 1413 SI_CAB_V14 "CAB = Clusteraktivbits (V14)";
CM_ SG_ 1413 SI_Diagnose_Aktiv "Gibt an ob Diagnose-Botschaften empfangen werden und somit eine Diagnose aktiv ist.
MQB: Gibt an ob Diagnose-Bus Botschaften empfangen werden und somit eine Diagnose aktiv ist.";
CM_ SG_ 1413 SI_NWDF "Netzwerk-Diagnose Freigebe zur zentralen Aktivierung der Netzwerkdiagnose";
CM_ SG_ 1413 SI_NWDF_30 "Netzwerk-Diagnose Freigabe zur zentralen Aktivierung der Netzwerkdiagnose (keine Ausblendbedingung aktiv)";
CM_ SG_ 1413 SI_NWDF_gueltig "Gültigkeitsbit zu SI_NWDF gemäß Lastenheft: Zentrale Aktivierung Netzwerkdiagnose";
CM_ SG_ 1413 SI_P_Mode "Zentrale Steuerung des Produktionsmodes gemäß Q-LAH-Produktionsmode (LAH.DUM.907.AS)";
CM_ SG_ 1413 SI_P_Mode_gueltig "zeigt an, ob es sich um ein Fahrzeug mit zentraler oder dezentraler Steu-erung des Produktionsmodes handelt
Siehe Q-LAH Produktionsmode (LAH.DUM.907.AS)";
CM_ SG_ 1413 SI_QRS_Mode "Messmodus Quick-Ruhestrom";
CM_ SG_ 1413 SI_Sammel_SG_Fehler "Anzahl der gesetzten KD-Fehler direkt angeschlossener Steuergeräte der DK3 und DK4 gemäß 80127.
Hinweis: Ein Subbusmaster stellt nur die gesammelte Information der an ihn angeschlossenen Steuergeräte der DK3 und DK4 zur Verfügung.

Für ServiceKey Auswe";
CM_ SG_ 1413 SI_Sammelfehler "Sammelfehlermeldung zur Anzeige im Kombi - siehe Spez. Sammelfehlermeldung
Hinweis: Einzelne Steuergeräte können zur Anpassung an den Produktionsprozess im Gateway auskodiert werden!";
CM_ SG_ 1413 SI_T_Mode "0x0: Transportmodus nicht aktiv
0x1: Transportmodus aktiv";
CM_ SG_ 1413 SI_T_Schutz "Transportschutz-Signal, das bei Transportmodus und Motorlauf aktiv bleibt
0x0: Transportschutz nicht aktiv
0x1: Transportschutz aktiv";

CM_ SG_ 619 TA_01_BZ "4bit Botschaftszähler, wird mit jeder Sendebotschaft inkrementiert";
CM_ SG_ 619 TA_01_CRC "Für MLB:
Berechnung siehe Lastenheft 'Kommunikationsabsicherung für FlexRay und CAN'
Ab MQB und MLBevo:
Berechnung siehe Lastenheft 'End-to-End Kommunikationsabsicherung'

Endwerte siehe Begleitdokument 'S-PDU Kennungsfolgen'";
CM_ SG_ 619 TA_ACC_Sollstatus "Status-Anforderung ACC vom TravelAssist";
CM_ SG_ 619 TA_aktiv_HMI "Signalwert an Anzeigegerät welche Funktion aktiv";
CM_ SG_ 619 TA_Fehler "Fehler im Modus Travel Assist";
CM_ SG_ 619 TA_FoD_Status "TAwird durch FoD geschützt sein und so reicht die PR/Zieldatencontainer basierte Codierung nicht mehr aus.

Aus diesem Grund brauch wir ein separates Signal, dass uns den Freischaltezustand mitteilt.";
CM_ SG_ 619 TA_FSW_Wartegrund_Umfeld "Anzeige des Wartegrunds für den assist. Spurwechsel in Sichtachse.";
CM_ SG_ 619 TA_FSW_Warten "Umsetzung Kopplung ACC <--> TA während Fahrspurwechsel";
CM_ SG_ 619 TA_FSW_Zuruecklenken "Signal zur Kopplung ACC <--> TA im FSW";
CM_ SG_ 619 TA_Handsoff_LED "Anfordern der Anzeige des LAHO-Icon in weiß und rot unabhängig von der Textmeldung";
CM_ SG_ 619 TA_Spurwechsel "Anzeige für die Durchführung eines Spurwechsels im Kombi";
CM_ SG_ 619 TA_Spurwechsel_Ready "Angabe der assistierten Spurwechselmöglichkeiten durch die Funktion 'Travel Assist'";
CM_ SG_ 619 TA_Status "Anzeige TravelAssist-Statusleuchte im Kombi";
CM_ SG_ 619 TA_Texte "Anzeige TravelAssist-Texte im Kombi";
CM_ SG_ 619 TA_Texte_02 "Anzeige TravelAssist-Texte im Kombi";
CM_ SG_ 619 TA_Ueberholhilfe "zusätzliches Signal für Handshake TA <--> ACC hinsichtlich Überholhilfe";

CM_ SG_ 1001 Thermo_Pred_Innen_Kunde_Anf "Änderung der Prädiktion iniziiert durch Kundenaktion";
CM_ SG_ 1001 Thermo_Pred_Innen_System_Anf "Systemseitig initiierte Änderung der Prädiktion; Signal ist einheitsloser Zähler mit Überlauf. 
Eine Inkrementierung steht für die Änderung der Umgebungsbedingungen mit dazugehöriger Klimaleistungsänderung.";
CM_ SG_ 1001 Thermo_Pred_P_dyn_Innen "Dynamsiche Leistung für Headup / Cooldown";
CM_ SG_ 1001 Thermo_Pred_P_stat_Innen "Stationäre Leistung für Heizen / Kühlen";
CM_ SG_ 1001 Thermo_Pred_T_dyn_Innen "Zeit bis zum Übergang vom dynamischen in stationären Betrieb";
CM_ SG_ 1001 Thermo_Verbrauch_BTL "Verbrauch für Heizen und Kühlen der Bauteile";
CM_ SG_ 1001 Thermo_Verbrauch_BTL_Ueberlauf "Überlauf-Bit Verbrauch Bauteil";
CM_ SG_ 1001 Thermo_Verbrauch_Innen "Verbrauch für Heizen und Kühlen Innenraum";
CM_ SG_ 1001 Thermo_Verbrauch_Innen_Ueberlauf "Überlauf-Bit Verbrauch Innenraum";

CM_ SG_ 1447 bCall_active "1: Breakdown call is active
0: BreakdownCall is inactive";
CM_ SG_ 1447 eCall_Funktionsstatus "HMI-Aufruf im Kombi (Broadcast)
Fehlerfälle die im Kombi angezeigt werden können";
CM_ SG_ 1447 eCall_Funktionsstatus_02 "Erweiterung des Funktionsstatus für andere Funktionen
ACN aktiv, MEC aktiv
MEC = manual emergency call = maueller Notruf
ACN = automatic emergency call = automatischer Notruf";
CM_ SG_ 1447 eCall_MCC "Mobile Country Code of the current mobile network
ITU-T E.212";
CM_ SG_ 1447 eCall_Mute_Anf "Signalisiert die Aufforderungen alle Soundquellen im Fahrzeug während eines aktiven Notrufs zu muten";
CM_ SG_ 1447 FaceRec_Enroll_Challenge_Request "When FaceRec on MIK receives this signal it will provide a challenge via SOK_FR_Enroll_MIK_Challenge.";
CM_ SG_ 1447 FoD_Anz_Funktionsabschaltung "Signal triggert Aufschaltung eines Popups, um dem Fahrer die Abschaltung einer Funktion zu melden.";
CM_ SG_ 1447 iCall_active "Statusrückmeldung von OCU über Infocall aktiv/inaktiv";
CM_ SG_ 1447 MOD_Energie_Anf "Anforderung Energieversorgung MOD-Job an das NVEM";
CM_ SG_ 1447 MOD_Request_ServiceKey "Sendet ein Signal zum ServiceKey-Master, welcher daraufhin einen aktuellen ServiceKey1c auf den Bus legt.";
CM_ SG_ 1447 ORU_KombiTimer "Ankündigung eines ORU OCU zum Kombi zur Darstellung entsprechender Symbole";
CM_ SG_ 1447 TM_Door_Lock "Remote Door lock angefordert: ZV zu/verriegeln";
CM_ SG_ 1447 TM_Door_Unlock "Remote Door unlock angefordert: ZV auf/entriegeln";
CM_ SG_ 1447 TM_Nur_Hupen "Remote Hupen (ohne Blinken) aktiviert";
CM_ SG_ 1447 TM_Panik_Alarm "Remote Hupen und Blinken aktiv";
CM_ SG_ 1447 TM_Spiegel_Anklappen "Anklappen der Außenspiegel über Remote MOD Anforderung";
CM_ SG_ 1447 TM_Warnblinken "Remote Blinken aktiviert";
CM_ SG_ 1447 TM_ZV_Signatur "Gespeicherte Signatur der ZV für Authentifizierung";

CM_ SG_ 977 ASW_Warnung_aktiv_BFS "Abschaltung der Ambientefunktion Beifahrertür bei aktiver ASW Warnung an der Fahrertür";
CM_ SG_ 977 BFS_Status_eTAG "Status des elektrischen Tueraussengriffes Beifahrertuer";
CM_ SG_ 977 BT_ASW_HMI_defekt "Zeigt an, ob die ASW-Anzeige defekt ist.";
CM_ SG_ 977 BT_EC_Spiegel_Helligkeit "Dimmung für den Aussenspiegel in %";
CM_ SG_ 977 BT_FH_Bew_hoch "Fensterheber in Bewegung Richtung hoch";
CM_ SG_ 977 BT_FH_Bew_tief "Fensterheber in Bewegung Richtung tief";
CM_ SG_ 977 BT_FH_Block "Fensterscheibe befindet sich im mechanischen Block (oben oder unten)";
CM_ SG_ 977 BT_FH_Fang "Fangbereich ist 4mm von oberer Lippendichtung";
CM_ SG_ 977 BT_FH_normiert "Die Position der Fensterheberscheibe ist bekannt";
CM_ SG_ 977 BT_FH_Oeffnung "Gibt den Fensteröffnungswert in % an.";
CM_ SG_ 977 BT_FH_S_AutoHoch "FH Schalter automatisch hoch gedrückt";
CM_ SG_ 977 BT_FH_S_AutoTief "FH Schalter automatisch tief gedrückt";
CM_ SG_ 977 BT_FH_S_ManHoch "FH Schalter manuell hoch gedrückt";
CM_ SG_ 977 BT_FH_S_ManTief "FH Schalter manuell tief gedrückt";
CM_ SG_ 977 BT_FH_Thermo "gibt an ob Fensterheber im Thermoschutz ist";
CM_ SG_ 977 BT_gesafet "Im Zustand Safe wird auch das Signal BT_verriegelt = 1 gesendet";
CM_ SG_ 977 BT_Kisi_Fehler "Fehlerstatus Kindersicherungsfunktion";
CM_ SG_ 977 BT_Lock_Taster "Verriegelungstaster";
CM_ SG_ 977 BT_Lock_Taster_inv "Lock Taster nicht betätigt";
CM_ SG_ 977 BT_Lock_Unlock_Taster "ZV Funktion Lock Unlock mit Toggle-Logik";
CM_ SG_ 977 BT_Oben_Block_erw "Fensterheber in Blockerwartung oben";
CM_ SG_ 977 BT_Schliesstaster "Schliesstaster Beifahrertür";
CM_ SG_ 977 BT_Schluesselschalter_auf "Schlüsselschalter Richtung auf betätigt";
CM_ SG_ 977 BT_Schluesselschalter_zu "Schluesselschalter Richtung zu betaetigt";
CM_ SG_ 977 BT_Schluesselschalter_zu_inv "Schluesselschalter zu nicht betaetigt";
CM_ SG_ 977 BT_SP_ausgerastet "Spiegel ausgerastet";
CM_ SG_ 977 BT_Sp_Blk_def "Blinker am Spiegel defekt";
CM_ SG_ 977 BT_SP_Heizung_aktiv "Zustand Spiegelheizung Beifahrertür";
CM_ SG_ 977 BT_Sp_Heizung_Anf "Kundenanforderung der Außenspiegelheizung Beifahrertür";
CM_ SG_ 977 BT_SP_Heizung_Status "Status der Spiegelheizung";
CM_ SG_ 977 BT_SP_ht_aktiv "Spiegelverstellung in Richtung hoch/tief aktiv";
CM_ SG_ 977 BT_SP_lr_aktiv "Spiegelverstellung in Richtung links/rechts aktiv";
CM_ SG_ 977 BT_Sperrklinke "Vorraste für Schloß

zwischen Vor- und Hauptraste Signal kurz auf 1, danach wieder auf 0 wenn Tür in Hauptraste (Tür ist sicher zu wenn Sperrklinke und Türkontakt auf 0 sind)";
CM_ SG_ 977 BT_SWA_HMI_defekt "Zeigt an, ob die SWA-Anzeige defekt ist.";
CM_ SG_ 977 BT_TAG_betaetigt "Türaussengriff";
CM_ SG_ 977 BT_TCR_Mode_aktiv "Signal zeigt eine aktive mechanische Redundanz am Türschloss an.";
CM_ SG_ 977 BT_TIG_betaetigt "Türinnengriff";
CM_ SG_ 977 BT_Tuer_geoeffnet "Zeigt eine geöffnete Tür an";
CM_ SG_ 977 BT_Tuer_Status "Türstatus mit Fehler und Initwert";
CM_ SG_ 977 BT_Tuer_Status_QBit "Dieses Bit gibt die Zuverlässigkeit des Türkontakts an. Ein auf dieses Bit folgender Fehlereintrag ist mit dem Sender des Bits abzustimmen (gültig ab PPE).";
CM_ SG_ 977 BT_Tueroeffnen_Warnung "Bit wird gesetzt, wenn Tür während der Fahrt geoeffnet werden soll.";
CM_ SG_ 977 BT_Tuerschloss_defekt "Das Beifahrertürschloss ist nicht mehr funktionsfähig.";
CM_ SG_ 977 BT_UEKB_aktiviert "Überschutzbegrenzungskraft bei Reversieren";
CM_ SG_ 977 BT_Unlock_Taster "Entriegelungstaster betätigt";
CM_ SG_ 977 BT_Unten_Block_erw "Fensterheber in Blockerwartung unten";
CM_ SG_ 977 BT_verriegelt "Zeigt eine verriegelte Tür an ( Status wird erst nach vollständiger Schlossansteuerung ausgegeben (<=1,5sek))";
CM_ SG_ 977 BT_Zuziehhilfe_aktiv "Zuziehhilfe aktiv";

CM_ SG_ 976 ASW_HMI_defekt "HMI Status der Funktion AusstiegsWarnung (ASW). HMI wird durch das TSG angesteuert.";
CM_ SG_ 976 ASW_wakeup "Trigger Start Nachlaufzeit t_1 für die Funktion Ausstieswarnung (ASW)";
CM_ SG_ 976 ASW_Warnung_aktiv_FS "Abschaltung der Ambientefunktion Fahrertür bei aktiver ASW Warnung an der Fahrertür";
CM_ SG_ 976 FS_Status_eTAG "Status des elektrischen Tueraussengriffes Fahrertuer";
CM_ SG_ 976 FT_BFS_Fond_Freigabe "Freigabe für Fondverstellung";
CM_ SG_ 976 FT_Daemmglas "Daemmglas verbaut";
CM_ SG_ 976 FT_FH_Bew_hoch "Fensterheber in Bewegung Richtung hoch";
CM_ SG_ 976 FT_FH_Bew_tief "Fensterheber in Bewegung Richtung tief";
CM_ SG_ 976 FT_FH_Block "Fensterscheibe befindet sich im mechanischen Block (oben oder unten)";
CM_ SG_ 976 FT_FH_Fang "Fangbereich ist 4mm von oberer Lippendichtung";
CM_ SG_ 976 FT_FH_normiert "Die Position der Fensterheberscheibe ist bekannt";
CM_ SG_ 976 FT_FH_Oeffnung "Gibt den Fensteröffnungswert in % an.";
CM_ SG_ 976 FT_FH_S_AutoHoch "FH Schalter automatisch hoch gedrückt";
CM_ SG_ 976 FT_FH_S_AutoTief "FH Schalter automatisch tief gedrückt";
CM_ SG_ 976 FT_FH_S_ManHoch "FH Schalter manuell hoch gedrückt";
CM_ SG_ 976 FT_FH_S_ManTief "FH Schalter manuell tief gedrückt";
CM_ SG_ 976 FT_FH_Thermo "gibt an ob Fensterheber im Thermoschutz ist";
CM_ SG_ 976 FT_gesafet "Im Zustand Safe wird auch das Signal FT_verriegelt = 1 gesendet";
CM_ SG_ 976 FT_HD_Taste "Taste in der Fahrertür zum Öffnen des Heckschlosses";
CM_ SG_ 976 FT_HD_Taste_2 "2. HD-Taste im Bedienfeld 
Funktion: Heckdeckel schließen";
CM_ SG_ 976 FT_IRUE_Taste "Betätigung IRUE-Taster (Innenraumüberwachung)
MQB: Bei Verbau eines einzelnen Taster zur Deaktivierung von IRUE und NGS wird dieses Signal als Deaktivierungsanforderung beider DWA-Alarmquellen gesendet.";
CM_ SG_ 976 FT_Kisi_Fehler "Fehlerstatus Kindersicherungsfunktion";
CM_ SG_ 976 FT_Kisi_li_aktiv "Aktivierungsstatus der Kindersicherung links";
CM_ SG_ 976 FT_Kisi_re_aktiv "Aktivierungsstatus der Kindersicherung rechts";
CM_ SG_ 976 FT_Kisi_Taster_li "Linker Kisi Taster betaetigt";
CM_ SG_ 976 FT_Kisi_Taster_re "Rechter Kisi Taster betaetigt";
CM_ SG_ 976 FT_Lock_Taster "Verriegelungstaster betätigt";
CM_ SG_ 976 FT_Lock_Unlock_Taster "ZV Funktion Lock Unlock mit Toggle-Logik";
CM_ SG_ 976 FT_Oben_Block_erw "Fensterheber in Blockerwartung oben";
CM_ SG_ 976 FT_Schliesstaster "Vorhalt";
CM_ SG_ 976 FT_Schluesselschalter_auf "Schlüsselschalter Richtung auf betätigt";
CM_ SG_ 976 FT_SP_ausgerastet "Spiegel ausgerastet";
CM_ SG_ 976 FT_Sp_Blk_def "Blinker am Spiegel defekt";
CM_ SG_ 976 FT_Sp_Heizung_Anf "Kundenanforderung der Außenspiegelheizung Fahrertür";
CM_ SG_ 976 FT_SP_Heizung_Status "Status der Spiegelheizung";
CM_ SG_ 976 FT_SP_ht_aktiv "Spiegelverstellung in Richtung hoch/tief aktiv";
CM_ SG_ 976 FT_SP_lr_aktiv "Spiegelverstellung in Richtung links/rechts aktiv";
CM_ SG_ 976 FT_Sperrklinke "Vorraste für Schloß

zwischen Vor- und Hauptraste Signal kurz auf 1, danach wieder auf 0 wenn Tür in Hauptraste (Tür ist sicher zu wenn Sperrklinke und Türkontakt auf 0 sind)";
CM_ SG_ 976 FT_SWA_Taster "SWA/ASW Taster Fahrertür";
CM_ SG_ 976 FT_TAG_betaetigt "Türaussengriff

wird nicht im MLB-B8 verwendet";
CM_ SG_ 976 FT_TD_Taste "Tankdeckelentriegelungs-Taste betätigt";
CM_ SG_ 976 FT_TD_Taste_Fehler "Fehlerstatus des Tankdeckelentriegelungstasters. Wird bei Drucktankkonzepten vom MSG zusammen mit dem Signal FT_TD_Taste ausgewertet, um Tankbereitschaft herzustellen.
Der Fehler beschreibt einen hängenden TD_Taster. Ein Kurzschluss oder Leitungsunterbre";
CM_ SG_ 976 FT_TIG_betaetigt "Türinnengriff

wird nicht im MLB-B8 verwendet";
CM_ SG_ 976 FT_Tuer_geoeffnet "Zeigt eine geöffnete Tür an";
CM_ SG_ 976 FT_Tuerschloss_defekt "Das Fahrertürschloss ist nicht mehr funktionsfähig.";
CM_ SG_ 976 FT_UEKB_aktiviert "Überschutzbegrenzungskraft bei Reversieren";
CM_ SG_ 976 FT_Unlock_Taster "Entriegelungstaster betätigt";
CM_ SG_ 976 FT_Unten_Block_erw "Fensterheber in Blockerwartung unten";
CM_ SG_ 976 FT_verriegelt "Zeigt eine verriegelte Tür an ( Status wird erst nach vollständiger Schlossansteuerung ausgegeben (<=1,5sek))";
CM_ SG_ 976 FT_Zuziehhilfe_aktiv "Zuziehhilfe aktiv";
CM_ SG_ 976 SSR_Temp_Freigabe "Freigabe des Seitenscheibenrollos. Bit wird  für die Deaktivierung des SSR bei Innenraumtemperaturen kleiner -10 Grad verwendet.";
CM_ SG_ 976 SWA_HMI_Diagnose "SWA HMI Diagnose beim TSG";
BA_DEF_REL_ BU_SG_REL_  "GenSigTimeoutTime" INT 0 65535;
BA_DEF_ BO_  "DiagRequest" ENUM "No", "Yes";
BA_DEF_ BO_  "DiagResponse" ENUM "No", "Yes";
BA_DEF_ BO_  "DiagState" ENUM "No", "Yes";
BA_DEF_ BO_  "GenMsgChkConstant" HEX 0 4095;
BA_DEF_ BO_  "GenMsgCycleTime" INT 0 65535;
BA_DEF_ BO_  "GenMsgCycleTimeFast" INT 0 65535;
BA_DEF_ BO_  "GenMsgDelayTime" INT 0 100000;
BA_DEF_ BO_  "GenMsgILSupport" ENUM "No", "Yes";
BA_DEF_ BO_  "GenMsgNrOfRepetition" INT 0 100;
BA_DEF_ BO_  "GenMsgPDUConstants" STRING;
BA_DEF_ BO_  "GenMsgSendType" ENUM "Cyclic", "not_used", "not_used", "not_used", "not_used", "not_used", "not_used", "IfActive", "NoMsgSendType";
BA_DEF_ BO_  "GenMsgStartDelayTime" INT 0 100000;
BA_DEF_ BO_  "NmMessage" ENUM "No", "Yes";
BA_DEF_ BO_  "NmhMessage" ENUM "No", "Yes";
BA_DEF_ BO_  "MsgType" ENUM "Application", "NM ", "NMH", "TP2.0", "ISO-TP ", "BAP", "EID", "KS", "XCP_PRE_CONFIGURED", "XCP_RUNTIME_CONFIGURED";
BA_DEF_ BO_  "VAGTP20_API" HEX 0 255;
BA_DEF_ BO_  "VAGTP20_DynConnection" ENUM "No", "Yes";
BA_DEF_ BO_  "VAGTP20_DynSetup" ENUM "No", "Yes";
BA_DEF_ BO_  "VAGTP20_StatConnection" ENUM "No", "Yes";
BA_DEF_ BO_  "CANFD_BRS" ENUM "0", "1";
BA_DEF_ BO_  "VFrameFormat" ENUM "StandardCAN", "ExtendedCAN", "reserved", "reserved", "reserved", "reserved", "reserved", "reserved", "reserved", "reserved", "reserved", "reserved", "reserved", "reserved", "StandardCAN_FD", "ExtendedCAN_FD";
BA_DEF_ SG_  "GenSigActiveRepetitions" INT -2147483648 2147483647;
BA_DEF_ SG_  "GenSigInactiveValue" INT -2147483648 2147483647;
BA_DEF_ SG_  "GenSigSendType" ENUM "Cyclic", "OnWrite", "OnWriteWithRepetition", "OnChange", "OnChangeWithRepetition", "IfActive", "IfActiveWithRepetition", "NoSigSendType", "OnChangeAndIfActive", "OnChangeAndIfActiveWithRepetition";
BA_DEF_ SG_  "GenSigStartValue" INT -2147483648 2147483647;
BA_DEF_ SG_  "NWM-WakeupAllowed" ENUM "No", "Yes";
BA_DEF_ SG_  "GenSigFuncType" ENUM "NoFunction", "MsgCounter", "CRC-8", "XOR", "XOR-2", "DatedBit", "SW-Kl15", "CHK", "Constant", "Protocol", "CRC-8-SAE_J1850", "CRC-32", "DataLength", "DataID", "MsgCounter16", "SOK-Signatur", "Cluster";
BA_DEF_ SG_  "GenSigSwitchedByIgnition" ENUM "No", "Yes";
BA_DEF_ SG_  "Fehlerwert" HEX 0 2147483647;
BA_DEF_ SG_  "GenSigMissingSourceValue" HEX 0 2147483647;
BA_DEF_DEF_REL_  "GenSigTimeoutTime" 0;
BA_DEF_DEF_  "DiagRequest" "No";
BA_DEF_DEF_  "DiagResponse" "No";
BA_DEF_DEF_  "DiagState" "No";
BA_DEF_DEF_  "GenMsgChkConstant" 0;
BA_DEF_DEF_  "GenMsgCycleTime" 0;
BA_DEF_DEF_  "GenMsgCycleTimeFast" 0;
BA_DEF_DEF_  "GenMsgDelayTime" 0;
BA_DEF_DEF_  "GenMsgILSupport" "No";
BA_DEF_DEF_  "GenMsgNrOfRepetition" 0;
BA_DEF_DEF_  "GenMsgPDUConstants" "";
BA_DEF_DEF_  "GenMsgSendType" "NoMsgSendType";
BA_DEF_DEF_  "GenMsgStartDelayTime" 0;
BA_DEF_DEF_  "NmMessage" "No";
BA_DEF_DEF_  "NmhMessage" "No";
BA_DEF_DEF_  "MsgType" "Application";
BA_DEF_DEF_  "VAGTP20_API" 0;
BA_DEF_DEF_  "VAGTP20_DynConnection" "No";
BA_DEF_DEF_  "VAGTP20_DynSetup" "No";
BA_DEF_DEF_  "VAGTP20_StatConnection" "No";
BA_DEF_DEF_  "CANFD_BRS" "1";
BA_DEF_DEF_  "VFrameFormat" "StandardCAN";
BA_DEF_DEF_  "GenSigActiveRepetitions" 0;
BA_DEF_DEF_  "GenSigInactiveValue" 0;
BA_DEF_DEF_  "GenSigSendType" "NoSigSendType";
BA_DEF_DEF_  "GenSigStartValue" 0;
BA_DEF_DEF_  "NWM-WakeupAllowed" "No";
BA_DEF_DEF_  "GenSigFuncType" "NoFunction";
BA_DEF_DEF_  "GenSigSwitchedByIgnition" "Yes";
BA_DEF_DEF_  "Fehlerwert" 0;
BA_DEF_DEF_  "GenSigMissingSourceValue" 0;
BA_ "GenMsgCycleTime" BO_ 2527679748 200;
BA_ "GenMsgILSupport" BO_ 2527679748 1;
BA_ "GenMsgSendType" BO_ 2527679748 0;
BA_ "VFrameFormat" BO_ 2527679748 15;
BA_ "GenMsgCycleTime" BO_ 2527679742 100;
BA_ "GenMsgILSupport" BO_ 2527679742 1;
BA_ "GenMsgSendType" BO_ 2527679742 0;
BA_ "VFrameFormat" BO_ 2527679742 15;
BA_ "GenMsgCycleTime" BO_ 1525 1000;
BA_ "GenMsgILSupport" BO_ 1525 1;
BA_ "GenMsgSendType" BO_ 1525 0;
BA_ "VFrameFormat" BO_ 1525 14;
BA_ "GenMsgCycleTime" BO_ 1527 1000;
BA_ "GenMsgDelayTime" BO_ 1527 100;
BA_ "GenMsgILSupport" BO_ 1527 1;
BA_ "GenMsgSendType" BO_ 1527 0;
BA_ "VFrameFormat" BO_ 1527 14;
BA_ "GenMsgCycleTime" BO_ 1322 1000;
BA_ "GenMsgILSupport" BO_ 1322 1;
BA_ "GenMsgSendType" BO_ 1322 0;
BA_ "VFrameFormat" BO_ 1322 14;
BA_ "GenMsgCycleTime" BO_ 2331596042 50;
BA_ "GenMsgDelayTime" BO_ 2331596042 20;
BA_ "GenMsgILSupport" BO_ 2331596042 1;
BA_ "GenMsgPDUConstants" BO_ 2331596042 "0x22,0x80,0x1e,0xd4,0x36,0x19,0x48,0x37,0xd6,0x3b,0x1a,0x91,0xe3,0x83,0xe0,0x7d";
BA_ "GenMsgSendType" BO_ 2331596042 0;
BA_ "VFrameFormat" BO_ 2331596042 15;
BA_ "GenMsgCycleTime" BO_ 1610 500;
BA_ "GenMsgILSupport" BO_ 1610 1;
BA_ "GenMsgSendType" BO_ 1610 0;
BA_ "VFrameFormat" BO_ 1610 14;
BA_ "GenMsgCycleTime" BO_ 1440 200;
BA_ "GenMsgILSupport" BO_ 1440 1;
BA_ "GenMsgSendType" BO_ 1440 0;
BA_ "VFrameFormat" BO_ 1440 14;
BA_ "MsgType" BO_ 2584746776 4;
BA_ "VFrameFormat" BO_ 2584746776 15;
BA_ "MsgType" BO_ 2584877848 4;
BA_ "VFrameFormat" BO_ 2584877848 15;
BA_ "GenMsgCycleTime" BO_ 1504 500;
BA_ "GenMsgCycleTimeFast" BO_ 1504 100;
BA_ "GenMsgDelayTime" BO_ 1504 50;
BA_ "GenMsgILSupport" BO_ 1504 1;
BA_ "GenMsgNrOfRepetition" BO_ 1504 5;
BA_ "GenMsgSendType" BO_ 1504 0;
BA_ "VFrameFormat" BO_ 1504 14;
BA_ "GenMsgCycleTimeFast" BO_ 2463978605 100;
BA_ "GenMsgILSupport" BO_ 2463978605 1;
BA_ "GenMsgSendType" BO_ 2463978605 7;
BA_ "VFrameFormat" BO_ 2463978605 15;
BA_ "GenMsgCycleTime" BO_ 1522 200;
BA_ "GenMsgDelayTime" BO_ 1522 50;
BA_ "GenMsgILSupport" BO_ 1522 1;
BA_ "GenMsgSendType" BO_ 1522 0;
BA_ "VFrameFormat" BO_ 1522 14;
BA_ "GenMsgCycleTimeFast" BO_ 1167 100;
BA_ "GenMsgILSupport" BO_ 1167 1;
BA_ "GenMsgSendType" BO_ 1167 7;
BA_ "VFrameFormat" BO_ 1167 14;
BA_ "GenMsgCycleTime" BO_ 980 1000;
BA_ "GenMsgCycleTimeFast" BO_ 980 100;
BA_ "GenMsgDelayTime" BO_ 980 50;
BA_ "GenMsgILSupport" BO_ 980 1;
BA_ "GenMsgNrOfRepetition" BO_ 980 5;
BA_ "GenMsgPDUConstants" BO_ 980 "0xc3,0x79,0xbf,0xdb,0xe9,0x11,0x46,0x86,0x69,0xb6,0x9b,0x29,0x15,0x9c,0x45,0x0d";
BA_ "GenMsgSendType" BO_ 980 0;
BA_ "VFrameFormat" BO_ 980 14;
BA_ "GenMsgDelayTime" BO_ 2464157740 50;
BA_ "GenMsgILSupport" BO_ 2464157740 1;
BA_ "VFrameFormat" BO_ 2464157740 15;
BA_ "GenMsgDelayTime" BO_ 2464288812 50;
BA_ "GenMsgILSupport" BO_ 2464288812 1;
BA_ "VFrameFormat" BO_ 2464288812 15;
BA_ "GenMsgDelayTime" BO_ 2589283756 100;
BA_ "GenMsgILSupport" BO_ 2589283756 1;
BA_ "VFrameFormat" BO_ 2589283756 15;
BA_ "DiagState" BO_ 2464153620 1;
BA_ "GenMsgDelayTime" BO_ 2464153620 100;
BA_ "GenMsgILSupport" BO_ 2464153620 1;
BA_ "VFrameFormat" BO_ 2464153620 15;
BA_ "GenMsgDelayTime" BO_ 2464284692 100;
BA_ "VFrameFormat" BO_ 2464284692 15;
BA_ "GenMsgDelayTime" BO_ 2464288788 100;
BA_ "GenMsgILSupport" BO_ 2464288788 1;
BA_ "VFrameFormat" BO_ 2464288788 15;
BA_ "GenMsgDelayTime" BO_ 2464153644 100;
BA_ "GenMsgILSupport" BO_ 2464153644 1;
BA_ "VFrameFormat" BO_ 2464153644 15;
BA_ "GenMsgDelayTime" BO_ 2464284716 100;
BA_ "GenMsgILSupport" BO_ 2464284716 1;
BA_ "VFrameFormat" BO_ 2464284716 15;
BA_ "GenMsgCycleTime" BO_ 1467 500;
BA_ "GenMsgILSupport" BO_ 1467 1;
BA_ "GenMsgSendType" BO_ 1467 0;
BA_ "VFrameFormat" BO_ 1467 14;
BA_ "GenMsgCycleTime" BO_ 2527679739 500;
BA_ "GenMsgDelayTime" BO_ 2527679739 50;
BA_ "GenMsgILSupport" BO_ 2527679739 1;
BA_ "GenMsgSendType" BO_ 2527679739 0;
BA_ "VFrameFormat" BO_ 2527679739 15;
BA_ "GenMsgCycleTime" BO_ 1313 200;
BA_ "GenMsgILSupport" BO_ 1313 1;
BA_ "GenMsgSendType" BO_ 1313 0;
BA_ "VFrameFormat" BO_ 1313 14;
BA_ "GenMsgCycleTime" BO_ 1413 1000;
BA_ "GenMsgDelayTime" BO_ 1413 10;
BA_ "GenMsgILSupport" BO_ 1413 1;
BA_ "GenMsgSendType" BO_ 1413 0;
BA_ "VFrameFormat" BO_ 1413 14;
BA_ "GenMsgCycleTime" BO_ 619 100;
BA_ "GenMsgDelayTime" BO_ 619 20;
BA_ "GenMsgILSupport" BO_ 619 1;
BA_ "GenMsgPDUConstants" BO_ 619 "0xce,0xcc,0xbd,0x69,0xa1,0x3c,0x18,0x76,0x0f,0x04,0xf2,0x3a,0x93,0x24,0x19,0x51";
BA_ "GenMsgSendType" BO_ 619 0;
BA_ "VFrameFormat" BO_ 619 14;
BA_ "GenMsgCycleTime" BO_ 1001 100;
BA_ "GenMsgILSupport" BO_ 1001 1;
BA_ "GenMsgSendType" BO_ 1001 0;
BA_ "VFrameFormat" BO_ 1001 14;
BA_ "GenMsgCycleTime" BO_ 1447 1000;
BA_ "GenMsgCycleTimeFast" BO_ 1447 100;
BA_ "GenMsgDelayTime" BO_ 1447 50;
BA_ "GenMsgILSupport" BO_ 1447 1;
BA_ "GenMsgSendType" BO_ 1447 0;
BA_ "VFrameFormat" BO_ 1447 14;
BA_ "GenMsgCycleTime" BO_ 977 100;
BA_ "GenMsgDelayTime" BO_ 977 20;
BA_ "GenMsgILSupport" BO_ 977 1;
BA_ "GenMsgSendType" BO_ 977 0;
BA_ "VFrameFormat" BO_ 977 14;
BA_ "GenMsgCycleTime" BO_ 976 100;
BA_ "GenMsgDelayTime" BO_ 976 20;
BA_ "GenMsgILSupport" BO_ 976 1;
BA_ "GenMsgSendType" BO_ 976 0;
BA_ "VFrameFormat" BO_ 976 14;
BA_ "GenSigSendType" SG_ 2527679748 SOK_RDK_11_Signatur 0;
BA_ "GenSigFuncType" SG_ 2527679748 SOK_RDK_11_Signatur 15;
BA_ "GenSigSendType" SG_ 2527679748 TPMS_CalTyp 0;
BA_ "GenSigSendType" SG_ 2527679748 TPMS_disable 0;
BA_ "GenSigSendType" SG_ 2527679748 TPMS_enable 0;
BA_ "GenSigSwitchedByIgnition" SG_ 2527679748 TPMS_enable 0;
BA_ "GenSigSendType" SG_ 2527679748 TPMS_LearningState 0;
BA_ "Fehlerwert" SG_ 2527679748 TPMS_LearningState 8;
BA_ "GenSigSendType" SG_ 2527679748 TPMS_PDeFrLe 0;
BA_ "GenSigSendType" SG_ 2527679748 TPMS_PDeFrRi 0;
BA_ "GenSigSendType" SG_ 2527679748 TPMS_PDeReLe 0;
BA_ "GenSigSendType" SG_ 2527679748 TPMS_PDeReRi 0;
BA_ "GenSigSendType" SG_ 2527679748 TPMS_RaceTrckMdSts 0;
BA_ "GenSigSendType" SG_ 2527679748 TPMS_SensBattStsFrLe 0;
BA_ "GenSigStartValue" SG_ 2527679748 TPMS_SensBattStsFrLe 126;
BA_ "Fehlerwert" SG_ 2527679748 TPMS_SensBattStsFrLe 127;
BA_ "GenSigSendType" SG_ 2527679748 TPMS_SensBattStsFrRi 0;
BA_ "GenSigStartValue" SG_ 2527679748 TPMS_SensBattStsFrRi 126;
BA_ "Fehlerwert" SG_ 2527679748 TPMS_SensBattStsFrRi 127;
BA_ "GenSigSendType" SG_ 2527679748 TPMS_SensBattStsReLe 0;
BA_ "GenSigStartValue" SG_ 2527679748 TPMS_SensBattStsReLe 126;
BA_ "Fehlerwert" SG_ 2527679748 TPMS_SensBattStsReLe 127;
BA_ "GenSigSendType" SG_ 2527679748 TPMS_SensBattStsReRi 0;
BA_ "GenSigStartValue" SG_ 2527679748 TPMS_SensBattStsReRi 126;
BA_ "Fehlerwert" SG_ 2527679748 TPMS_SensBattStsReRi 127;
BA_ "GenSigSendType" SG_ 2527679748 TPMS_SensPFrLe 0;
BA_ "GenSigStartValue" SG_ 2527679748 TPMS_SensPFrLe 63;
BA_ "GenSigSendType" SG_ 2527679748 TPMS_SensPFrRi 0;
BA_ "GenSigStartValue" SG_ 2527679748 TPMS_SensPFrRi 63;
BA_ "GenSigSendType" SG_ 2527679748 TPMS_SensPReLe 0;
BA_ "GenSigStartValue" SG_ 2527679748 TPMS_SensPReLe 63;
BA_ "GenSigSendType" SG_ 2527679748 TPMS_SensPReRi 0;
BA_ "GenSigStartValue" SG_ 2527679748 TPMS_SensPReRi 63;
BA_ "GenSigSendType" SG_ 2527679748 TPMS_SensSigAgeFrLe 0;
BA_ "GenSigStartValue" SG_ 2527679748 TPMS_SensSigAgeFrLe 14;
BA_ "Fehlerwert" SG_ 2527679748 TPMS_SensSigAgeFrLe 15;
BA_ "GenSigSendType" SG_ 2527679748 TPMS_SensSigAgeFrRi 0;
BA_ "GenSigStartValue" SG_ 2527679748 TPMS_SensSigAgeFrRi 14;
BA_ "Fehlerwert" SG_ 2527679748 TPMS_SensSigAgeFrRi 15;
BA_ "GenSigSendType" SG_ 2527679748 TPMS_SensSigAgeReLe 0;
BA_ "GenSigStartValue" SG_ 2527679748 TPMS_SensSigAgeReLe 14;
BA_ "Fehlerwert" SG_ 2527679748 TPMS_SensSigAgeReLe 15;
BA_ "GenSigSendType" SG_ 2527679748 TPMS_SensSigAgeReRi 0;
BA_ "GenSigStartValue" SG_ 2527679748 TPMS_SensSigAgeReRi 14;
BA_ "Fehlerwert" SG_ 2527679748 TPMS_SensSigAgeReRi 15;
BA_ "GenSigSendType" SG_ 2527679748 TPMS_SensStsFrLe 0;
BA_ "GenSigSendType" SG_ 2527679748 TPMS_SensStsFrRi 0;
BA_ "GenSigSendType" SG_ 2527679748 TPMS_SensStsReLe 0;
BA_ "GenSigSendType" SG_ 2527679748 TPMS_SensStsReRi 0;
BA_ "GenSigSendType" SG_ 2527679748 TPMS_SensTFrLe 0;
BA_ "GenSigStartValue" SG_ 2527679748 TPMS_SensTFrLe 254;
BA_ "Fehlerwert" SG_ 2527679748 TPMS_SensTFrLe 255;
BA_ "GenSigSendType" SG_ 2527679748 TPMS_SensTFrRi 0;
BA_ "GenSigStartValue" SG_ 2527679748 TPMS_SensTFrRi 254;
BA_ "Fehlerwert" SG_ 2527679748 TPMS_SensTFrRi 255;
BA_ "GenSigSendType" SG_ 2527679748 TPMS_SensTReLe 0;
BA_ "GenSigStartValue" SG_ 2527679748 TPMS_SensTReLe 254;
BA_ "Fehlerwert" SG_ 2527679748 TPMS_SensTReLe 255;
BA_ "GenSigSendType" SG_ 2527679748 TPMS_SensTReRi 0;
BA_ "GenSigStartValue" SG_ 2527679748 TPMS_SensTReRi 254;
BA_ "Fehlerwert" SG_ 2527679748 TPMS_SensTReRi 255;
BA_ "GenSigSendType" SG_ 2527679748 TPMS_SensTypFrLe 0;
BA_ "GenSigSendType" SG_ 2527679748 TPMS_SensTypFrRi 0;
BA_ "GenSigSendType" SG_ 2527679748 TPMS_SensTypReLe 0;
BA_ "GenSigSendType" SG_ 2527679748 TPMS_SensTypReRi 0;
BA_ "GenSigSendType" SG_ 2527679748 TPMS_TarPTmpDepFrLe 0;
BA_ "GenSigSwitchedByIgnition" SG_ 2527679748 TPMS_TarPTmpDepFrLe 0;
BA_ "GenSigSendType" SG_ 2527679748 TPMS_TarPTmpDepFrRi 0;
BA_ "GenSigSwitchedByIgnition" SG_ 2527679748 TPMS_TarPTmpDepFrRi 0;
BA_ "GenSigSendType" SG_ 2527679748 TPMS_TarPTmpDepReLe 0;
BA_ "GenSigSwitchedByIgnition" SG_ 2527679748 TPMS_TarPTmpDepReLe 0;
BA_ "GenSigSendType" SG_ 2527679748 TPMS_TarPTmpDepReRi 0;
BA_ "GenSigSwitchedByIgnition" SG_ 2527679748 TPMS_TarPTmpDepReRi 0;
BA_ "GenSigSendType" SG_ 2527679748 TPMS_Warn1 0;
BA_ "GenSigSendType" SG_ 2527679748 TPMS_Warn1TireFrLe 0;
BA_ "GenSigSendType" SG_ 2527679748 TPMS_Warn1TireFrRi 0;
BA_ "GenSigSendType" SG_ 2527679748 TPMS_Warn1TireReLe 0;
BA_ "GenSigSendType" SG_ 2527679748 TPMS_Warn1TireReRi 0;
BA_ "GenSigSendType" SG_ 2527679748 TPMS_Warn2 0;
BA_ "GenSigSendType" SG_ 2527679748 TPMS_Warn2TireFrLe 0;
BA_ "GenSigSendType" SG_ 2527679748 TPMS_Warn2TireFrRi 0;
BA_ "GenSigSendType" SG_ 2527679748 TPMS_Warn2TireReLe 0;
BA_ "GenSigSendType" SG_ 2527679748 TPMS_Warn2TireReRi 0;
BA_ "GenSigSendType" SG_ 2527679748 TPMS_Warn3 0;
BA_ "GenSigSendType" SG_ 2527679748 TPMS_Warn3TireFrLe 0;
BA_ "GenSigSendType" SG_ 2527679748 TPMS_Warn3TireFrRi 0;
BA_ "GenSigSendType" SG_ 2527679748 TPMS_Warn3TireReLe 0;
BA_ "GenSigSendType" SG_ 2527679748 TPMS_Warn3TireReRi 0;
BA_ "GenSigSendType" SG_ 2527679748 TPMS_Warn4 0;
BA_ "GenSigSendType" SG_ 2527679748 TPMS_Warn4TireFrLe 0;
BA_ "GenSigSendType" SG_ 2527679748 TPMS_Warn4TireFrRi 0;
BA_ "GenSigSendType" SG_ 2527679748 TPMS_Warn4TireReLe 0;
BA_ "GenSigSendType" SG_ 2527679748 TPMS_Warn4TireReRi 0;
BA_ "GenSigSendType" SG_ 2527679748 TPMS_WarnAcoCalOk 0;
BA_ "GenSigSendType" SG_ 2527679748 TPMS_WarnCalOk 0;
BA_ "GenSigSendType" SG_ 2527679748 TPMS_WarnCmftP 0;
BA_ "GenSigSendType" SG_ 2527679748 TPMS_WarnFltIdc 0;
BA_ "GenSigSendType" SG_ 2527679748 TPMS_WarnFr 0;
BA_ "GenSigSendType" SG_ 2527679748 TPMS_WarnLmpStMil 0;
BA_ "GenSigSendType" SG_ 2527679748 TPMS_WarnLmpStP 0;
BA_ "GenSigSendType" SG_ 2527679748 TPMS_WarnMaxV 0;
BA_ "GenSigSendType" SG_ 2527679748 TPMS_WarnRaceTrckMdMinP 0;
BA_ "GenSigSendType" SG_ 2527679748 TPMS_WarnRe 0;
BA_ "GenSigSendType" SG_ 2527679748 TPMS_WarnSysLrn 0;
BA_ "GenSigSendType" SG_ 2527679748 TPMS_WarnTmpFlt 0;
BA_ "GenSigSendType" SG_ 2527679748 TPMS_WarnWhlChgDet 0;
BA_ "GenSigSendType" SG_ 2527679748 TPMS_WhlChgDetFrLe 0;
BA_ "GenSigSendType" SG_ 2527679748 TPMS_WhlChgDetFrRi 0;
BA_ "GenSigSendType" SG_ 2527679748 TPMS_WhlChgDetReLe 0;
BA_ "GenSigSendType" SG_ 2527679748 TPMS_WhlChgDetReRi 0;
BA_ "GenSigSendType" SG_ 2527679742 Kam_Anf_Meldung 0;
BA_ "GenSigSendType" SG_ 2527679742 Kam_PaCo_MainState 0;
BA_ "GenSigSwitchedByIgnition" SG_ 2527679742 Kam_PaCo_MainState 0;
BA_ "Fehlerwert" SG_ 2527679742 Kam_PaCo_MainState 7;
BA_ "GenSigSendType" SG_ 1525 RW_Gesamt_Reichweite 0;
BA_ "GenSigStartValue" SG_ 1525 RW_Gesamt_Reichweite 2046;
BA_ "GenSigSwitchedByIgnition" SG_ 1525 RW_Gesamt_Reichweite 0;
BA_ "Fehlerwert" SG_ 1525 RW_Gesamt_Reichweite 2047;
BA_ "GenSigSendType" SG_ 1525 RW_Gesamt_Reichweite_Max_Anzeige 0;
BA_ "GenSigStartValue" SG_ 1525 RW_Gesamt_Reichweite_Max_Anzeige 2046;
BA_ "GenSigSwitchedByIgnition" SG_ 1525 RW_Gesamt_Reichweite_Max_Anzeige 0;
BA_ "Fehlerwert" SG_ 1525 RW_Gesamt_Reichweite_Max_Anzeige 2047;
BA_ "GenSigSendType" SG_ 1525 RW_Prim_Reichweitenv_Einheit 0;
BA_ "GenSigStartValue" SG_ 1525 RW_Prim_Reichweitenv_Einheit 3;
BA_ "GenSigSwitchedByIgnition" SG_ 1525 RW_Prim_Reichweitenv_Einheit 0;
BA_ "GenSigSendType" SG_ 1525 RW_Prim_Reichweitenverbrauch 0;
BA_ "GenSigStartValue" SG_ 1525 RW_Prim_Reichweitenverbrauch 2047;
BA_ "GenSigSwitchedByIgnition" SG_ 1525 RW_Prim_Reichweitenverbrauch 0;
BA_ "GenSigSendType" SG_ 1525 RW_Primaer_Reichweite 0;
BA_ "GenSigStartValue" SG_ 1525 RW_Primaer_Reichweite 2046;
BA_ "GenSigSwitchedByIgnition" SG_ 1525 RW_Primaer_Reichweite 0;
BA_ "Fehlerwert" SG_ 1525 RW_Primaer_Reichweite 2047;
BA_ "GenSigSendType" SG_ 1525 RW_Reservewarnung_2_aktiv 0;
BA_ "GenSigSwitchedByIgnition" SG_ 1525 RW_Reservewarnung_2_aktiv 0;
BA_ "GenSigSendType" SG_ 1525 RW_RWDS_Lastprofil 0;
BA_ "GenSigStartValue" SG_ 1525 RW_RWDS_Lastprofil 2046;
BA_ "GenSigSwitchedByIgnition" SG_ 1525 RW_RWDS_Lastprofil 0;
BA_ "Fehlerwert" SG_ 1525 RW_RWDS_Lastprofil 2047;
BA_ "GenSigSendType" SG_ 1527 RW_Gesamt_Reichweite_Anzeige 0;
BA_ "GenSigStartValue" SG_ 1527 RW_Gesamt_Reichweite_Anzeige 2046;
BA_ "GenSigSwitchedByIgnition" SG_ 1527 RW_Gesamt_Reichweite_Anzeige 0;
BA_ "Fehlerwert" SG_ 1527 RW_Gesamt_Reichweite_Anzeige 2047;
BA_ "GenSigSendType" SG_ 1527 RW_Primaer_Reichweite_Anzeige 0;
BA_ "GenSigStartValue" SG_ 1527 RW_Primaer_Reichweite_Anzeige 2046;
BA_ "GenSigSwitchedByIgnition" SG_ 1527 RW_Primaer_Reichweite_Anzeige 0;
BA_ "Fehlerwert" SG_ 1527 RW_Primaer_Reichweite_Anzeige 2047;
BA_ "GenSigSendType" SG_ 1527 RW_Reichweite_Einheit_Anzeige 0;
BA_ "GenSigSwitchedByIgnition" SG_ 1527 RW_Reichweite_Einheit_Anzeige 0;
BA_ "GenSigSendType" SG_ 1527 RW_Reservewarnung_aktiv 0;
BA_ "GenSigSwitchedByIgnition" SG_ 1527 RW_Reservewarnung_aktiv 0;
BA_ "GenSigSendType" SG_ 1527 RW_Sek_Reichweitenv_Einheit 0;
BA_ "GenSigStartValue" SG_ 1527 RW_Sek_Reichweitenv_Einheit 3;
BA_ "GenSigSwitchedByIgnition" SG_ 1527 RW_Sek_Reichweitenv_Einheit 0;
BA_ "GenSigSendType" SG_ 1527 RW_Sek_Reichweitenverbrauch 0;
BA_ "GenSigStartValue" SG_ 1527 RW_Sek_Reichweitenverbrauch 2047;
BA_ "GenSigSwitchedByIgnition" SG_ 1527 RW_Sek_Reichweitenverbrauch 0;
BA_ "GenSigSendType" SG_ 1527 RW_Sekundaer_Reichweite 0;
BA_ "GenSigStartValue" SG_ 1527 RW_Sekundaer_Reichweite 2046;
BA_ "GenSigSwitchedByIgnition" SG_ 1527 RW_Sekundaer_Reichweite 0;
BA_ "Fehlerwert" SG_ 1527 RW_Sekundaer_Reichweite 2047;
BA_ "GenSigSendType" SG_ 1527 RW_Sekundaer_Reichweite_Anzeige 0;
BA_ "GenSigStartValue" SG_ 1527 RW_Sekundaer_Reichweite_Anzeige 2046;
BA_ "GenSigSwitchedByIgnition" SG_ 1527 RW_Sekundaer_Reichweite_Anzeige 0;
BA_ "Fehlerwert" SG_ 1527 RW_Sekundaer_Reichweite_Anzeige 2047;
BA_ "GenSigSendType" SG_ 1527 RW_Tendenz 0;
BA_ "GenSigSwitchedByIgnition" SG_ 1527 RW_Tendenz 0;
BA_ "GenSigSendType" SG_ 1527 RW_Texte 3;
BA_ "GenSigSwitchedByIgnition" SG_ 1527 RW_Texte 0;
BA_ "GenSigSendType" SG_ 1322 RES_AlQuitRem 0;
BA_ "GenSigSendType" SG_ 1322 RES_ServComp 0;
BA_ "GenSigSendType" SG_ 1322 RES_TripReset 0;
BA_ "GenSigSendType" SG_ 2331596042 RHP_02_BZ 0;
BA_ "GenSigFuncType" SG_ 2331596042 RHP_02_BZ 1;
BA_ "GenSigSwitchedByIgnition" SG_ 2331596042 RHP_02_BZ 0;
BA_ "GenSigSendType" SG_ 2331596042 RHP_02_CRC 0;
BA_ "GenSigFuncType" SG_ 2331596042 RHP_02_CRC 2;
BA_ "GenSigSwitchedByIgnition" SG_ 2331596042 RHP_02_CRC 0;
BA_ "GenSigSendType" SG_ 2331596042 RHP_Abstand_CIO 0;
BA_ "GenSigSendType" SG_ 2331596042 RHP_Abstand_LNS 0;
BA_ "GenSigSwitchedByIgnition" SG_ 2331596042 RHP_Abstand_LNS 0;
BA_ "GenSigSendType" SG_ 2331596042 RHP_Abstand_RNS 0;
BA_ "GenSigSwitchedByIgnition" SG_ 2331596042 RHP_Abstand_RNS 0;
BA_ "GenSigSendType" SG_ 2331596042 RHP_Abstand_WZO 0;
BA_ "GenSigSwitchedByIgnition" SG_ 2331596042 RHP_Abstand_WZO 0;
BA_ "GenSigSendType" SG_ 2331596042 RHP_Abstandsindex 0;
BA_ "GenSigSwitchedByIgnition" SG_ 2331596042 RHP_Abstandsindex 0;
BA_ "GenSigSendType" SG_ 2331596042 RHP_aktiv_HMI 0;
BA_ "GenSigSwitchedByIgnition" SG_ 2331596042 RHP_aktiv_HMI 0;
BA_ "GenSigSendType" SG_ 2331596042 RHP_Anzeige_Maximalabstand 0;
BA_ "GenSigSwitchedByIgnition" SG_ 2331596042 RHP_Anzeige_Maximalabstand 0;
BA_ "GenSigSendType" SG_ 2331596042 RHP_Anzeige_Objektregelung 0;
BA_ "GenSigSwitchedByIgnition" SG_ 2331596042 RHP_Anzeige_Objektregelung 0;
BA_ "GenSigSendType" SG_ 2331596042 RHP_Anzeige_Zeitluecke 0;
BA_ "GenSigSwitchedByIgnition" SG_ 2331596042 RHP_Anzeige_Zeitluecke 0;
BA_ "GenSigSendType" SG_ 2331596042 RHP_CIO 0;
BA_ "GenSigSendType" SG_ 2331596042 RHP_EGO_Fahrzeug 0;
BA_ "GenSigSwitchedByIgnition" SG_ 2331596042 RHP_EGO_Fahrzeug 0;
BA_ "GenSigSendType" SG_ 2331596042 RHP_Einheit_maxSetzgeschw 0;
BA_ "GenSigSwitchedByIgnition" SG_ 2331596042 RHP_Einheit_maxSetzgeschw 0;
BA_ "GenSigSendType" SG_ 2331596042 RHP_ErrorStatus 3;
BA_ "GenSigSwitchedByIgnition" SG_ 2331596042 RHP_ErrorStatus 0;
BA_ "GenSigSendType" SG_ 2331596042 RHP_FoD_Status 0;
BA_ "GenSigSwitchedByIgnition" SG_ 2331596042 RHP_FoD_Status 0;
BA_ "GenSigSendType" SG_ 2331596042 RHP_Gesetzte_Zeitluecke 0;
BA_ "GenSigSwitchedByIgnition" SG_ 2331596042 RHP_Gesetzte_Zeitluecke 0;
BA_ "GenSigSendType" SG_ 2331596042 RHP_Gong 0;
BA_ "GenSigSwitchedByIgnition" SG_ 2331596042 RHP_Gong 0;
BA_ "GenSigSendType" SG_ 2331596042 RHP_HMI_DetectedLane 3;
BA_ "GenSigSendType" SG_ 2331596042 RHP_HMI_Ego_li_Anzeige 0;
BA_ "GenSigSendType" SG_ 2331596042 RHP_HMI_Ego_li_Seg1_QuerAbst 0;
BA_ "GenSigSendType" SG_ 2331596042 RHP_HMI_Ego_li_Typ 0;
BA_ "GenSigSendType" SG_ 2331596042 RHP_HMI_Ego_re_Anzeige 0;
BA_ "GenSigSendType" SG_ 2331596042 RHP_HMI_Ego_re_Seg1_QuerAbst 0;
BA_ "GenSigSendType" SG_ 2331596042 RHP_HMI_Ego_re_Typ 0;
BA_ "GenSigSendType" SG_ 2331596042 RHP_HMI_EgoObj_dy 0;
BA_ "GenSigSendType" SG_ 2331596042 RHP_HMI_Kurvenwarnung 0;
BA_ "GenSigSendType" SG_ 2331596042 RHP_HMI_LaneChangeIndicator 0;
BA_ "GenSigSendType" SG_ 2331596042 RHP_HMI_LaneChangeTrajectory 3;
BA_ "GenSigSendType" SG_ 2331596042 RHP_HMI_Nachb_li_Anzeige 0;
BA_ "GenSigSendType" SG_ 2331596042 RHP_HMI_Nachb_li_Seg1_QuerAbst 0;
BA_ "GenSigSendType" SG_ 2331596042 RHP_HMI_Nachb_li_Typ 0;
BA_ "GenSigSendType" SG_ 2331596042 RHP_HMI_Nachb_re_Anzeige 0;
BA_ "GenSigSendType" SG_ 2331596042 RHP_HMI_Nachb_re_Seg1_QuerAbst 0;
BA_ "GenSigSendType" SG_ 2331596042 RHP_HMI_Nachb_re_Typ 0;
BA_ "GenSigSendType" SG_ 2331596042 RHP_LateralLamp 3;
BA_ "GenSigSwitchedByIgnition" SG_ 2331596042 RHP_LateralLamp 0;
BA_ "GenSigSendType" SG_ 2331596042 RHP_maxSetzgeschw 0;
BA_ "GenSigStartValue" SG_ 2331596042 RHP_maxSetzgeschw 511;
BA_ "GenSigSwitchedByIgnition" SG_ 2331596042 RHP_maxSetzgeschw 0;
BA_ "GenSigSendType" SG_ 2331596042 RHP_Regelgeschw 0;
BA_ "GenSigStartValue" SG_ 2331596042 RHP_Regelgeschw 1023;
BA_ "GenSigSwitchedByIgnition" SG_ 2331596042 RHP_Regelgeschw 0;
BA_ "GenSigSendType" SG_ 2331596042 RHP_Relevantes_Objekt 0;
BA_ "GenSigSwitchedByIgnition" SG_ 2331596042 RHP_Relevantes_Objekt 0;
BA_ "GenSigSendType" SG_ 2331596042 RHP_Sollabstand_1 0;
BA_ "GenSigSwitchedByIgnition" SG_ 2331596042 RHP_Sollabstand_1 0;
BA_ "GenSigSendType" SG_ 2331596042 RHP_Sollabstand_2 0;
BA_ "GenSigSwitchedByIgnition" SG_ 2331596042 RHP_Sollabstand_2 0;
BA_ "GenSigSendType" SG_ 2331596042 RHP_Sollabstand_3 0;
BA_ "GenSigSwitchedByIgnition" SG_ 2331596042 RHP_Sollabstand_3 0;
BA_ "GenSigSendType" SG_ 2331596042 RHP_Sollabstand_4 0;
BA_ "GenSigSwitchedByIgnition" SG_ 2331596042 RHP_Sollabstand_4 0;
BA_ "GenSigSendType" SG_ 2331596042 RHP_Sollabstand_5 0;
BA_ "GenSigSwitchedByIgnition" SG_ 2331596042 RHP_Sollabstand_5 0;
BA_ "GenSigSendType" SG_ 2331596042 RHP_StatusLamp 3;
BA_ "GenSigSwitchedByIgnition" SG_ 2331596042 RHP_StatusLamp 0;
BA_ "GenSigSendType" SG_ 2331596042 RHP_Tempolimit 0;
BA_ "GenSigSwitchedByIgnition" SG_ 2331596042 RHP_Tempolimit 0;
BA_ "GenSigSendType" SG_ 2331596042 RHP_Tempolimit_Einheit 0;
BA_ "GenSigSwitchedByIgnition" SG_ 2331596042 RHP_Tempolimit_Einheit 0;
BA_ "GenSigSendType" SG_ 2331596042 RHP_Tempolimit_Farbe 0;
BA_ "GenSigSwitchedByIgnition" SG_ 2331596042 RHP_Tempolimit_Farbe 0;
BA_ "GenSigSendType" SG_ 2331596042 RHP_Text_01 3;
BA_ "GenSigSwitchedByIgnition" SG_ 2331596042 RHP_Text_01 0;
BA_ "GenSigSendType" SG_ 2331596042 RHP_Text_02 3;
BA_ "GenSigSwitchedByIgnition" SG_ 2331596042 RHP_Text_02 0;
BA_ "GenSigSendType" SG_ 2331596042 RHP_Texte_Sekundaeranz 0;
BA_ "GenSigSwitchedByIgnition" SG_ 2331596042 RHP_Texte_Sekundaeranz 0;
BA_ "GenSigSendType" SG_ 2331596042 RHP_TOR_Lamp 3;
BA_ "GenSigSwitchedByIgnition" SG_ 2331596042 RHP_TOR_Lamp 0;
BA_ "GenSigSendType" SG_ 2331596042 RHP_Typ_CIO 0;
BA_ "GenSigSendType" SG_ 2331596042 RHP_Typ_LNS 0;
BA_ "GenSigSwitchedByIgnition" SG_ 2331596042 RHP_Typ_LNS 0;
BA_ "GenSigSendType" SG_ 2331596042 RHP_Typ_RNS 0;
BA_ "GenSigSwitchedByIgnition" SG_ 2331596042 RHP_Typ_RNS 0;
BA_ "GenSigSendType" SG_ 2331596042 RHP_Typ_WZO 0;
BA_ "GenSigSwitchedByIgnition" SG_ 2331596042 RHP_Typ_WZO 0;
BA_ "GenSigSendType" SG_ 2331596042 RHP_Wunschgeschw 0;
BA_ "GenSigStartValue" SG_ 2331596042 RHP_Wunschgeschw 1023;
BA_ "GenSigSwitchedByIgnition" SG_ 2331596042 RHP_Wunschgeschw 0;
BA_ "GenSigSendType" SG_ 2331596042 RHP_Wunschgeschw_Farbe 0;
BA_ "GenSigSwitchedByIgnition" SG_ 2331596042 RHP_Wunschgeschw_Farbe 0;
BA_ "GenSigSendType" SG_ 1610 RKA_FMVSS138_Lampe 0;
BA_ "GenSigSwitchedByIgnition" SG_ 1610 RKA_FMVSS138_Lampe 0;
BA_ "GenSigSendType" SG_ 1610 RKA_FMVSS138_MIL 0;
BA_ "GenSigSwitchedByIgnition" SG_ 1610 RKA_FMVSS138_MIL 0;
BA_ "GenSigSendType" SG_ 1610 RKA_Reifentyp 0;
BA_ "GenSigSwitchedByIgnition" SG_ 1610 RKA_Reifentyp 0;
BA_ "GenSigSendType" SG_ 1610 RKA_Warnungen_02 0;
BA_ "GenSigSwitchedByIgnition" SG_ 1610 RKA_Warnungen_02 0;
BA_ "GenSigSendType" SG_ 1440 LS_defekt 0;
BA_ "GenSigSwitchedByIgnition" SG_ 1440 LS_defekt 0;
BA_ "GenSigSendType" SG_ 1440 LS_Helligkeit_FW 0;
BA_ "GenSigStartValue" SG_ 1440 LS_Helligkeit_FW 1022;
BA_ "GenSigSwitchedByIgnition" SG_ 1440 LS_Helligkeit_FW 0;
BA_ "Fehlerwert" SG_ 1440 LS_Helligkeit_FW 1023;
BA_ "GenSigMissingSourceValue" SG_ 1440 LS_Helligkeit_FW 1023;
BA_ "GenSigSendType" SG_ 1440 LS_Helligkeit_IR 0;
BA_ "GenSigStartValue" SG_ 1440 LS_Helligkeit_IR 254;
BA_ "GenSigSwitchedByIgnition" SG_ 1440 LS_Helligkeit_IR 0;
BA_ "Fehlerwert" SG_ 1440 LS_Helligkeit_IR 255;
BA_ "GenSigMissingSourceValue" SG_ 1440 LS_Helligkeit_IR 255;
BA_ "GenSigSendType" SG_ 1440 LS_Verbau 0;
BA_ "GenSigSwitchedByIgnition" SG_ 1440 LS_Verbau 0;
BA_ "GenSigSendType" SG_ 1440 RLS_Vorfeldhelligkeit_Boost 0;
BA_ "GenSigStartValue" SG_ 1440 RLS_Vorfeldhelligkeit_Boost 15;
BA_ "GenSigSwitchedByIgnition" SG_ 1440 RLS_Vorfeldhelligkeit_Boost 0;
BA_ "GenSigSendType" SG_ 1440 RS_defekt 0;
BA_ "GenSigSwitchedByIgnition" SG_ 1440 RS_defekt 0;
BA_ "GenSigSendType" SG_ 1440 RS_Regenmenge 0;
BA_ "GenSigStartValue" SG_ 1440 RS_Regenmenge 14;
BA_ "GenSigSwitchedByIgnition" SG_ 1440 RS_Regenmenge 0;
BA_ "Fehlerwert" SG_ 1440 RS_Regenmenge 15;
BA_ "GenSigMissingSourceValue" SG_ 1440 RS_Regenmenge 15;
BA_ "GenSigSendType" SG_ 1440 RS_Schwall 0;
BA_ "GenSigSwitchedByIgnition" SG_ 1440 RS_Schwall 0;
BA_ "GenSigSendType" SG_ 1440 RS_Verbau 0;
BA_ "GenSigSwitchedByIgnition" SG_ 1440 RS_Verbau 0;
BA_ "GenSigSendType" SG_ 1440 RS_Verglasung_schliessen 0;
BA_ "GenSigSwitchedByIgnition" SG_ 1440 RS_Verglasung_schliessen 0;
BA_ "GenSigSendType" SG_ 1440 RS_Wischergeschwindigkeit 0;
BA_ "GenSigSwitchedByIgnition" SG_ 1440 RS_Wischergeschwindigkeit 0;
BA_ "GenSigSendType" SG_ 1440 SLS_Helligkeit_IR 0;
BA_ "GenSigStartValue" SG_ 1440 SLS_Helligkeit_IR 254;
BA_ "GenSigSwitchedByIgnition" SG_ 1440 SLS_Helligkeit_IR 0;
BA_ "Fehlerwert" SG_ 1440 SLS_Helligkeit_IR 255;
BA_ "GenSigSendType" SG_ 2584746776 SACID_1_AuthTime_Req_Data 3;
BA_ "GenSigFuncType" SG_ 2584746776 SACID_1_AuthTime_Req_Data 9;
BA_ "GenSigSwitchedByIgnition" SG_ 2584746776 SACID_1_AuthTime_Req_Data 0;
BA_ "GenSigSendType" SG_ 2584877848 SACID_1_AuthTime_Resp_Data 3;
BA_ "GenSigFuncType" SG_ 2584877848 SACID_1_AuthTime_Resp_Data 9;
BA_ "GenSigSwitchedByIgnition" SG_ 2584877848 SACID_1_AuthTime_Resp_Data 0;
BA_ "GenSigSendType" SG_ 1504 MD1_Lage 0;
BA_ "GenSigSwitchedByIgnition" SG_ 1504 MD1_Lage 0;
BA_ "GenSigSendType" SG_ 1504 MD1_Position 0;
BA_ "GenSigStartValue" SG_ 1504 MD1_Position 126;
BA_ "GenSigSwitchedByIgnition" SG_ 1504 MD1_Position 0;
BA_ "GenSigSendType" SG_ 1504 MD3_Lage 0;
BA_ "GenSigSwitchedByIgnition" SG_ 1504 MD3_Lage 0;
BA_ "GenSigSendType" SG_ 1504 MD3_Position 0;
BA_ "GenSigSwitchedByIgnition" SG_ 1504 MD3_Position 0;
BA_ "GenSigSendType" SG_ 1504 MRollo_Lage 0;
BA_ "GenSigSwitchedByIgnition" SG_ 1504 MRollo_Lage 0;
BA_ "GenSigSendType" SG_ 1504 MRollo_Position 0;
BA_ "GenSigStartValue" SG_ 1504 MRollo_Position 126;
BA_ "GenSigSwitchedByIgnition" SG_ 1504 MRollo_Position 0;
BA_ "GenSigSendType" SG_ 1504 Rollo_normiert 3;
BA_ "GenSigSwitchedByIgnition" SG_ 1504 Rollo_normiert 0;
BA_ "GenSigSendType" SG_ 1504 Rollo_Thermoschutz 3;
BA_ "GenSigSwitchedByIgnition" SG_ 1504 Rollo_Thermoschutz 0;
BA_ "GenSigSendType" SG_ 1504 Rollo_UEKB_aktiv 3;
BA_ "GenSigSwitchedByIgnition" SG_ 1504 Rollo_UEKB_aktiv 0;
BA_ "GenSigSendType" SG_ 1504 SAD_Anf_ESC_Zuschaltung 3;
BA_ "GenSigSwitchedByIgnition" SG_ 1504 SAD_Anf_ESC_Zuschaltung 0;
BA_ "GenSigSendType" SG_ 1504 SAD_normiert 3;
BA_ "GenSigSwitchedByIgnition" SG_ 1504 SAD_normiert 0;
BA_ "GenSigSendType" SG_ 1504 SAD_Taster_Deckel_hi 4;
BA_ "GenSigSwitchedByIgnition" SG_ 1504 SAD_Taster_Deckel_hi 0;
BA_ "GenSigSendType" SG_ 1504 SAD_Taster_Deckel_vo 4;
BA_ "GenSigSwitchedByIgnition" SG_ 1504 SAD_Taster_Deckel_vo 0;
BA_ "GenSigSendType" SG_ 1504 SAD_Taster_Rollo_hi 4;
BA_ "GenSigSwitchedByIgnition" SG_ 1504 SAD_Taster_Rollo_hi 0;
BA_ "GenSigSendType" SG_ 1504 SAD_Taster_Rollo_vo 4;
BA_ "GenSigSwitchedByIgnition" SG_ 1504 SAD_Taster_Rollo_vo 0;
BA_ "GenSigSendType" SG_ 1504 SAD_Thermoschutz 3;
BA_ "GenSigSwitchedByIgnition" SG_ 1504 SAD_Thermoschutz 0;
BA_ "GenSigSendType" SG_ 1504 SAD_UEKB_aktiv 3;
BA_ "GenSigSwitchedByIgnition" SG_ 1504 SAD_UEKB_aktiv 0;
BA_ "GenSigSendType" SG_ 2463978605 SCode_Data 5;
BA_ "GenSigSwitchedByIgnition" SG_ 2463978605 SCode_Data 0;
BA_ "GenSigSendType" SG_ 2463978605 SCode_Target 5;
BA_ "GenSigSwitchedByIgnition" SG_ 2463978605 SCode_Target 0;
BA_ "GenSigSendType" SG_ 1522 KBI_Dimmpoti 0;
BA_ "GenSigSwitchedByIgnition" SG_ 1522 KBI_Dimmpoti 0;
BA_ "Fehlerwert" SG_ 1522 KBI_Dimmpoti 127;
BA_ "GenSigSendType" SG_ 1522 KBI_Phototransistor 3;
BA_ "GenSigStartValue" SG_ 1522 KBI_Phototransistor 254;
BA_ "GenSigSwitchedByIgnition" SG_ 1522 KBI_Phototransistor 0;
BA_ "Fehlerwert" SG_ 1522 KBI_Phototransistor 255;
BA_ "GenSigSwitchedByIgnition" SG_ 1167 SK1_Key_Data_1 0;
BA_ "GenSigSwitchedByIgnition" SG_ 1167 SK1_Key_Data_10 0;
BA_ "GenSigSwitchedByIgnition" SG_ 1167 SK1_Key_Data_2 0;
BA_ "GenSigSwitchedByIgnition" SG_ 1167 SK1_Key_Data_3 0;
BA_ "GenSigSwitchedByIgnition" SG_ 1167 SK1_Key_Data_4 0;
BA_ "GenSigSwitchedByIgnition" SG_ 1167 SK1_Key_Data_5 0;
BA_ "GenSigSwitchedByIgnition" SG_ 1167 SK1_Key_Data_6 0;
BA_ "GenSigSwitchedByIgnition" SG_ 1167 SK1_Key_Data_7 0;
BA_ "GenSigSwitchedByIgnition" SG_ 1167 SK1_Key_Data_8 0;
BA_ "GenSigSwitchedByIgnition" SG_ 1167 SK1_Key_Data_9 0;
BA_ "GenSigSendType" SG_ 1167 SK1_MUX 3;
BA_ "GenSigSwitchedByIgnition" SG_ 1167 SK1_MUX 0;
BA_ "GenSigSendType" SG_ 980 BH_Blinker_Fehler 4;
BA_ "GenSigSwitchedByIgnition" SG_ 980 BH_Blinker_Fehler 0;
BA_ "Fehlerwert" SG_ 980 BH_Blinker_Fehler 1;
BA_ "GenSigSendType" SG_ 980 BH_Blinker_li 4;
BA_ "GenSigSwitchedByIgnition" SG_ 980 BH_Blinker_li 0;
BA_ "GenSigSendType" SG_ 980 BH_Blinker_re 4;
BA_ "GenSigSwitchedByIgnition" SG_ 980 BH_Blinker_re 0;
BA_ "GenSigSendType" SG_ 980 BH_Fernlicht 3;
BA_ "GenSigSwitchedByIgnition" SG_ 980 BH_Fernlicht 0;
BA_ "GenSigSendType" SG_ 980 BH_Lichthupe 4;
BA_ "GenSigSwitchedByIgnition" SG_ 980 BH_Lichthupe 0;
BA_ "GenSigSendType" SG_ 980 FAS_Taster 3;
BA_ "GenSigSwitchedByIgnition" SG_ 980 FAS_Taster 0;
BA_ "GenSigSendType" SG_ 980 FAS_Taster_Fehler 3;
BA_ "GenSigSwitchedByIgnition" SG_ 980 FAS_Taster_Fehler 0;
BA_ "Fehlerwert" SG_ 980 FAS_Taster_Fehler 1;
BA_ "GenSigSendType" SG_ 980 LRH_aktiv 3;
BA_ "GenSigSwitchedByIgnition" SG_ 980 LRH_aktiv 0;
BA_ "GenSigSendType" SG_ 980 LRH_On_Off 3;
BA_ "GenSigSwitchedByIgnition" SG_ 980 LRH_On_Off 0;
BA_ "Fehlerwert" SG_ 980 LRH_On_Off 3;
BA_ "GenSigSendType" SG_ 980 LSS_Tastencode 3;
BA_ "GenSigSwitchedByIgnition" SG_ 980 LSS_Tastencode 0;
BA_ "GenSigSendType" SG_ 980 SMLS_01_BZ 0;
BA_ "GenSigFuncType" SG_ 980 SMLS_01_BZ 1;
BA_ "GenSigSwitchedByIgnition" SG_ 980 SMLS_01_BZ 0;
BA_ "GenSigSendType" SG_ 980 SMLS_01_CRC 0;
BA_ "GenSigFuncType" SG_ 980 SMLS_01_CRC 2;
BA_ "GenSigSwitchedByIgnition" SG_ 980 SMLS_01_CRC 0;
BA_ "GenSigSendType" SG_ 980 SMLS_Hupe 4;
BA_ "GenSigSwitchedByIgnition" SG_ 980 SMLS_Hupe 0;
BA_ "GenSigSendType" SG_ 980 SMLS_P_verriegelt 4;
BA_ "GenSigSwitchedByIgnition" SG_ 980 SMLS_P_verriegelt 0;
BA_ "Fehlerwert" SG_ 980 SMLS_P_verriegelt 3;
BA_ "GenSigSendType" SG_ 980 SMLS_P_verriegelt_plausibel 3;
BA_ "GenSigSwitchedByIgnition" SG_ 980 SMLS_P_verriegelt_plausibel 0;
BA_ "GenSigSendType" SG_ 980 SMLS_PTT 4;
BA_ "GenSigSendType" SG_ 980 WH_Frontwaschen 3;
BA_ "GenSigSwitchedByIgnition" SG_ 980 WH_Frontwaschen 0;
BA_ "GenSigSendType" SG_ 980 WH_Heckintervall 3;
BA_ "GenSigSwitchedByIgnition" SG_ 980 WH_Heckintervall 0;
BA_ "GenSigSendType" SG_ 980 WH_Heckwaschen 3;
BA_ "GenSigSwitchedByIgnition" SG_ 980 WH_Heckwaschen 0;
BA_ "GenSigSendType" SG_ 980 WH_Intervall 3;
BA_ "GenSigSwitchedByIgnition" SG_ 980 WH_Intervall 0;
BA_ "GenSigSendType" SG_ 980 WH_Intervallstufen 3;
BA_ "GenSigSwitchedByIgnition" SG_ 980 WH_Intervallstufen 0;
BA_ "Fehlerwert" SG_ 980 WH_Intervallstufen 15;
BA_ "GenSigMissingSourceValue" SG_ 980 WH_Intervallstufen 15;
BA_ "GenSigSendType" SG_ 980 WH_SRA 3;
BA_ "GenSigSwitchedByIgnition" SG_ 980 WH_SRA 0;
BA_ "GenSigSendType" SG_ 980 WH_Tipwischen 4;
BA_ "GenSigSwitchedByIgnition" SG_ 980 WH_Tipwischen 0;
BA_ "GenSigSendType" SG_ 980 WH_Tipwischen_lang 4;
BA_ "GenSigSwitchedByIgnition" SG_ 980 WH_Tipwischen_lang 0;
BA_ "GenSigSendType" SG_ 980 WH_Wischer_Fehler 3;
BA_ "GenSigSwitchedByIgnition" SG_ 980 WH_Wischer_Fehler 0;
BA_ "Fehlerwert" SG_ 980 WH_Wischer_Fehler 1;
BA_ "GenSigSendType" SG_ 980 WH_WischerStufe1 3;
BA_ "GenSigSwitchedByIgnition" SG_ 980 WH_WischerStufe1 0;
BA_ "GenSigSendType" SG_ 980 WH_WischerStufe2 3;
BA_ "GenSigSwitchedByIgnition" SG_ 980 WH_WischerStufe2 0;
BA_ "GenSigSendType" SG_ 2464157740 SOK_FoD_MFG_Req_Challenge 3;
BA_ "GenSigSwitchedByIgnition" SG_ 2464157740 SOK_FoD_MFG_Req_Challenge 0;
BA_ "GenSigSendType" SG_ 2464288812 SOK_FoD_MFG_Resp_Challenge 3;
BA_ "GenSigSwitchedByIgnition" SG_ 2464288812 SOK_FoD_MFG_Resp_Challenge 0;
BA_ "GenSigSendType" SG_ 2589283756 SOK_ungeschuetzte_Zeit 3;
BA_ "GenSigSwitchedByIgnition" SG_ 2589283756 SOK_ungeschuetzte_Zeit 0;
BA_ "GenSigSendType" SG_ 2464153620 SOK_Zeit_Kombi_Challenge 3;
BA_ "GenSigSwitchedByIgnition" SG_ 2464153620 SOK_Zeit_Kombi_Challenge 0;
BA_ "GenSigSendType" SG_ 2464284692 SOK_Zeit_Kombi_Signatur 3;
BA_ "GenSigFuncType" SG_ 2464284692 SOK_Zeit_Kombi_Signatur 15;
BA_ "GenSigSwitchedByIgnition" SG_ 2464284692 SOK_Zeit_Kombi_Signatur 0;
BA_ "GenSigSendType" SG_ 2464288788 SOK_Zeit_Kombi_Zeit 3;
BA_ "GenSigSwitchedByIgnition" SG_ 2464288788 SOK_Zeit_Kombi_Zeit 0;
BA_ "GenSigSendType" SG_ 2464153644 SOK_Zeit_MFG_Challenge 3;
BA_ "GenSigSwitchedByIgnition" SG_ 2464153644 SOK_Zeit_MFG_Challenge 0;
BA_ "GenSigSendType" SG_ 2464284716 SOK_Zeit_MFG_Signatur 3;
BA_ "GenSigFuncType" SG_ 2464284716 SOK_Zeit_MFG_Signatur 15;
BA_ "GenSigSwitchedByIgnition" SG_ 2464284716 SOK_Zeit_MFG_Signatur 0;
BA_ "GenSigSendType" SG_ 2464284716 SOK_Zeit_MFG_Zeit 3;
BA_ "GenSigSwitchedByIgnition" SG_ 2464284716 SOK_Zeit_MFG_Zeit 0;
BA_ "GenSigSendType" SG_ 1467 SoSe_SunInt_2D_Li 0;
BA_ "GenSigStartValue" SG_ 1467 SoSe_SunInt_2D_Li 254;
BA_ "GenSigSwitchedByIgnition" SG_ 1467 SoSe_SunInt_2D_Li 0;
BA_ "Fehlerwert" SG_ 1467 SoSe_SunInt_2D_Li 255;
BA_ "GenSigSendType" SG_ 1467 SoSe_SunInt_2D_Re 0;
BA_ "GenSigStartValue" SG_ 1467 SoSe_SunInt_2D_Re 254;
BA_ "GenSigSwitchedByIgnition" SG_ 1467 SoSe_SunInt_2D_Re 0;
BA_ "Fehlerwert" SG_ 1467 SoSe_SunInt_2D_Re 255;
BA_ "GenSigSendType" SG_ 2527679739 STK_AirCLeaner_Anf 3;
BA_ "GenSigSwitchedByIgnition" SG_ 2527679739 STK_AirCLeaner_Anf 0;
BA_ "GenSigSendType" SG_ 2527679739 STK_Anf_AussenspiegelHZ 0;
BA_ "GenSigSwitchedByIgnition" SG_ 2527679739 STK_Anf_AussenspiegelHZ 0;
BA_ "GenSigSendType" SG_ 2527679739 STK_Berechnungsphase 3;
BA_ "GenSigStartValue" SG_ 2527679739 STK_Berechnungsphase 2;
BA_ "GenSigSwitchedByIgnition" SG_ 2527679739 STK_Berechnungsphase 0;
BA_ "Fehlerwert" SG_ 2527679739 STK_Berechnungsphase 3;
BA_ "GenSigSendType" SG_ 2527679739 STK_Betriebsdauer 0;
BA_ "GenSigSwitchedByIgnition" SG_ 2527679739 STK_Betriebsdauer 0;
BA_ "GenSigSendType" SG_ 2527679739 STK_ErwVK_Anf 3;
BA_ "GenSigSwitchedByIgnition" SG_ 2527679739 STK_ErwVK_Anf 0;
BA_ "GenSigSendType" SG_ 2527679739 STK_ErwVK_Beifahrerzone 3;
BA_ "GenSigSwitchedByIgnition" SG_ 2527679739 STK_ErwVK_Beifahrerzone 0;
BA_ "GenSigSendType" SG_ 2527679739 STK_ErwVK_Fahrerzone 3;
BA_ "GenSigSwitchedByIgnition" SG_ 2527679739 STK_ErwVK_Fahrerzone 0;
BA_ "GenSigSendType" SG_ 2527679739 STK_ErwVK_Heckzone2_links 0;
BA_ "GenSigSwitchedByIgnition" SG_ 2527679739 STK_ErwVK_Heckzone2_links 0;
BA_ "GenSigSendType" SG_ 2527679739 STK_ErwVK_Heckzone2_rechts 0;
BA_ "GenSigSwitchedByIgnition" SG_ 2527679739 STK_ErwVK_Heckzone2_rechts 0;
BA_ "GenSigSendType" SG_ 2527679739 STK_ErwVK_Heckzone_links 3;
BA_ "GenSigSwitchedByIgnition" SG_ 2527679739 STK_ErwVK_Heckzone_links 0;
BA_ "GenSigSendType" SG_ 2527679739 STK_ErwVK_Heckzone_rechts 3;
BA_ "GenSigSwitchedByIgnition" SG_ 2527679739 STK_ErwVK_Heckzone_rechts 0;
BA_ "GenSigSendType" SG_ 2527679739 STK_ErwVK_Modus 3;
BA_ "GenSigSwitchedByIgnition" SG_ 2527679739 STK_ErwVK_Modus 0;
BA_ "GenSigSendType" SG_ 2527679739 STK_ErwVK_Scheibenheizung 3;
BA_ "GenSigSwitchedByIgnition" SG_ 2527679739 STK_ErwVK_Scheibenheizung 0;
BA_ "GenSigSendType" SG_ 2527679739 STK_FSH_Anf 3;
BA_ "GenSigSwitchedByIgnition" SG_ 2527679739 STK_FSH_Anf 0;
BA_ "GenSigSendType" SG_ 2527679739 STK_GesamtEnergiebedarf 0;
BA_ "GenSigStartValue" SG_ 2527679739 STK_GesamtEnergiebedarf 254;
BA_ "GenSigSwitchedByIgnition" SG_ 2527679739 STK_GesamtEnergiebedarf 0;
BA_ "Fehlerwert" SG_ 2527679739 STK_GesamtEnergiebedarf 255;
BA_ "GenSigSendType" SG_ 2527679739 STK_HSH_Anf 3;
BA_ "GenSigSwitchedByIgnition" SG_ 2527679739 STK_HSH_Anf 0;
BA_ "GenSigSendType" SG_ 2527679739 STK_Klima_Temp 0;
BA_ "GenSigStartValue" SG_ 2527679739 STK_Klima_Temp 30;
BA_ "GenSigSwitchedByIgnition" SG_ 2527679739 STK_Klima_Temp 0;
BA_ "Fehlerwert" SG_ 2527679739 STK_Klima_Temp 31;
BA_ "GenSigSendType" SG_ 2527679739 STK_KurzVK_Anf 3;
BA_ "GenSigSwitchedByIgnition" SG_ 2527679739 STK_KurzVK_Anf 0;
BA_ "GenSigSendType" SG_ 2527679739 STK_MaxLeistung 0;
BA_ "GenSigStartValue" SG_ 2527679739 STK_MaxLeistung 254;
BA_ "GenSigSwitchedByIgnition" SG_ 2527679739 STK_MaxLeistung 0;
BA_ "Fehlerwert" SG_ 2527679739 STK_MaxLeistung 255;
BA_ "GenSigSendType" SG_ 2527679739 STK_Standklima_Anf 3;
BA_ "GenSigSwitchedByIgnition" SG_ 2527679739 STK_Standklima_Anf 0;
BA_ "GenSigSendType" SG_ 2527679739 STK_Standklima_Timer_Status 3;
BA_ "GenSigSwitchedByIgnition" SG_ 2527679739 STK_Standklima_Timer_Status 0;
BA_ "GenSigSendType" SG_ 2527679739 STK_Stecker_Status 0;
BA_ "GenSigSwitchedByIgnition" SG_ 2527679739 STK_Stecker_Status 0;
BA_ "GenSigSendType" SG_ 2527679739 STK_VK_Modus 3;
BA_ "GenSigSwitchedByIgnition" SG_ 2527679739 STK_VK_Modus 0;
BA_ "Fehlerwert" SG_ 2527679739 STK_VK_Modus 3;
BA_ "GenSigSendType" SG_ 2527679739 STK_VK_STH_Einsatz 3;
BA_ "GenSigStartValue" SG_ 2527679739 STK_VK_STH_Einsatz 6;
BA_ "GenSigSwitchedByIgnition" SG_ 2527679739 STK_VK_STH_Einsatz 0;
BA_ "Fehlerwert" SG_ 2527679739 STK_VK_STH_Einsatz 7;
BA_ "GenSigSendType" SG_ 2527679739 STK_VK_Timer_Status 3;
BA_ "GenSigSwitchedByIgnition" SG_ 2527679739 STK_VK_Timer_Status 0;
BA_ "GenSigSendType" SG_ 2527679739 STK_Voko_LED 3;
BA_ "GenSigSwitchedByIgnition" SG_ 2527679739 STK_Voko_LED 0;
BA_ "GenSigSendType" SG_ 1313 STH_EKP_Anst 0;
BA_ "GenSigSwitchedByIgnition" SG_ 1313 STH_EKP_Anst 0;
BA_ "GenSigSendType" SG_ 1313 STH_Fehler_ElWaPu 0;
BA_ "GenSigSwitchedByIgnition" SG_ 1313 STH_Fehler_ElWaPu 0;
BA_ "Fehlerwert" SG_ 1313 STH_Fehler_ElWaPu 1;
BA_ "GenSigSendType" SG_ 1313 STH_Fehlerstatus 0;
BA_ "GenSigSwitchedByIgnition" SG_ 1313 STH_Fehlerstatus 0;
BA_ "GenSigSendType" SG_ 1313 STH_Funk_aus 0;
BA_ "GenSigSwitchedByIgnition" SG_ 1313 STH_Funk_aus 0;
BA_ "GenSigSendType" SG_ 1313 STH_Funk_ein 0;
BA_ "GenSigSwitchedByIgnition" SG_ 1313 STH_Funk_ein 0;
BA_ "GenSigSendType" SG_ 1313 STH_Geblaese 0;
BA_ "GenSigSwitchedByIgnition" SG_ 1313 STH_Geblaese 0;
BA_ "GenSigSendType" SG_ 1313 STH_Heizleistung 0;
BA_ "GenSigSwitchedByIgnition" SG_ 1313 STH_Heizleistung 0;
BA_ "GenSigSendType" SG_ 1313 STH_KL_HUP 0;
BA_ "GenSigSwitchedByIgnition" SG_ 1313 STH_KL_HUP 0;
BA_ "GenSigSendType" SG_ 1313 STH_KVS 0;
BA_ "GenSigSwitchedByIgnition" SG_ 1313 STH_KVS 0;
BA_ "GenSigSendType" SG_ 1313 STH_KVS_Ueberlauf 0;
BA_ "GenSigSwitchedByIgnition" SG_ 1313 STH_KVS_Ueberlauf 0;
BA_ "GenSigSendType" SG_ 1313 STH_LED 0;
BA_ "GenSigSwitchedByIgnition" SG_ 1313 STH_LED 0;
BA_ "GenSigSendType" SG_ 1313 STH_Motorvorwaermung 0;
BA_ "GenSigSwitchedByIgnition" SG_ 1313 STH_Motorvorwaermung 0;
BA_ "GenSigSendType" SG_ 1313 STH_Pumpe_ein 0;
BA_ "GenSigSwitchedByIgnition" SG_ 1313 STH_Pumpe_ein 0;
BA_ "GenSigSendType" SG_ 1313 STH_Pumpen_Anf_extern 0;
BA_ "GenSigSwitchedByIgnition" SG_ 1313 STH_Pumpen_Anf_extern 0;
BA_ "GenSigSendType" SG_ 1313 STH_Servicemode 0;
BA_ "GenSigSwitchedByIgnition" SG_ 1313 STH_Servicemode 0;
BA_ "GenSigSendType" SG_ 1313 STH_SH_ZH 0;
BA_ "GenSigSwitchedByIgnition" SG_ 1313 STH_SH_ZH 0;
BA_ "GenSigSendType" SG_ 1313 STH_Start_folgt 0;
BA_ "GenSigSwitchedByIgnition" SG_ 1313 STH_Start_folgt 0;
BA_ "GenSigSendType" SG_ 1313 STH_Texte 0;
BA_ "GenSigSwitchedByIgnition" SG_ 1313 STH_Texte 0;
BA_ "GenSigSendType" SG_ 1313 STH_Ventil_Status 0;
BA_ "GenSigSwitchedByIgnition" SG_ 1313 STH_Ventil_Status 0;
BA_ "GenSigSendType" SG_ 1313 STH_Ventiloeffnungszeit 0;
BA_ "GenSigSwitchedByIgnition" SG_ 1313 STH_Ventiloeffnungszeit 0;
BA_ "GenSigSendType" SG_ 1313 STH_Waermeeintrag 0;
BA_ "GenSigSwitchedByIgnition" SG_ 1313 STH_Waermeeintrag 0;
BA_ "GenSigSendType" SG_ 1313 STH_war_aktiv 0;
BA_ "GenSigSwitchedByIgnition" SG_ 1313 STH_war_aktiv 0;
BA_ "GenSigSendType" SG_ 1313 STH_Wassertemp 0;
BA_ "GenSigStartValue" SG_ 1313 STH_Wassertemp 254;
BA_ "GenSigSwitchedByIgnition" SG_ 1313 STH_Wassertemp 0;
BA_ "Fehlerwert" SG_ 1313 STH_Wassertemp 255;
BA_ "GenSigSendType" SG_ 1313 STH_Zusatzheizung 0;
BA_ "GenSigSwitchedByIgnition" SG_ 1313 STH_Zusatzheizung 0;
BA_ "GenSigSendType" SG_ 1413 GW_KD_Fehler 3;
BA_ "GenSigSendType" SG_ 1413 SI_BUS_01 3;
BA_ "GenSigStartValue" SG_ 1413 SI_BUS_01 1;
BA_ "GenSigSwitchedByIgnition" SG_ 1413 SI_BUS_01 0;
BA_ "GenSigSendType" SG_ 1413 SI_BUS_02 3;
BA_ "GenSigStartValue" SG_ 1413 SI_BUS_02 1;
BA_ "GenSigSwitchedByIgnition" SG_ 1413 SI_BUS_02 0;
BA_ "GenSigSendType" SG_ 1413 SI_BUS_03 3;
BA_ "GenSigStartValue" SG_ 1413 SI_BUS_03 1;
BA_ "GenSigSwitchedByIgnition" SG_ 1413 SI_BUS_03 0;
BA_ "GenSigSendType" SG_ 1413 SI_BUS_04 3;
BA_ "GenSigStartValue" SG_ 1413 SI_BUS_04 1;
BA_ "GenSigSwitchedByIgnition" SG_ 1413 SI_BUS_04 0;
BA_ "GenSigSendType" SG_ 1413 SI_BUS_05 3;
BA_ "GenSigStartValue" SG_ 1413 SI_BUS_05 1;
BA_ "GenSigSwitchedByIgnition" SG_ 1413 SI_BUS_05 0;
BA_ "GenSigSendType" SG_ 1413 SI_BUS_06 3;
BA_ "GenSigStartValue" SG_ 1413 SI_BUS_06 1;
BA_ "GenSigSwitchedByIgnition" SG_ 1413 SI_BUS_06 0;
BA_ "GenSigSendType" SG_ 1413 SI_BUS_07 3;
BA_ "GenSigStartValue" SG_ 1413 SI_BUS_07 1;
BA_ "GenSigSwitchedByIgnition" SG_ 1413 SI_BUS_07 0;
BA_ "GenSigSendType" SG_ 1413 SI_BUS_08 3;
BA_ "GenSigStartValue" SG_ 1413 SI_BUS_08 1;
BA_ "GenSigSwitchedByIgnition" SG_ 1413 SI_BUS_08 0;
BA_ "GenSigSendType" SG_ 1413 SI_BUS_09 3;
BA_ "GenSigStartValue" SG_ 1413 SI_BUS_09 1;
BA_ "GenSigSwitchedByIgnition" SG_ 1413 SI_BUS_09 0;
BA_ "GenSigSendType" SG_ 1413 SI_BUS_10 3;
BA_ "GenSigStartValue" SG_ 1413 SI_BUS_10 1;
BA_ "GenSigSwitchedByIgnition" SG_ 1413 SI_BUS_10 0;
BA_ "GenSigSendType" SG_ 1413 SI_BUS_11 3;
BA_ "GenSigStartValue" SG_ 1413 SI_BUS_11 1;
BA_ "GenSigSwitchedByIgnition" SG_ 1413 SI_BUS_11 0;
BA_ "GenSigSendType" SG_ 1413 SI_BUS_12 3;
BA_ "GenSigStartValue" SG_ 1413 SI_BUS_12 1;
BA_ "GenSigSwitchedByIgnition" SG_ 1413 SI_BUS_12 0;
BA_ "GenSigSendType" SG_ 1413 SI_BUS_13 3;
BA_ "GenSigStartValue" SG_ 1413 SI_BUS_13 1;
BA_ "GenSigSwitchedByIgnition" SG_ 1413 SI_BUS_13 0;
BA_ "GenSigSendType" SG_ 1413 SI_BUS_14 3;
BA_ "GenSigStartValue" SG_ 1413 SI_BUS_14 1;
BA_ "GenSigSwitchedByIgnition" SG_ 1413 SI_BUS_14 0;
BA_ "GenSigSendType" SG_ 1413 SI_BUS_15 3;
BA_ "GenSigStartValue" SG_ 1413 SI_BUS_15 1;
BA_ "GenSigSwitchedByIgnition" SG_ 1413 SI_BUS_15 0;
BA_ "GenSigSendType" SG_ 1413 SI_Bus_Identifikation 0;
BA_ "GenSigSwitchedByIgnition" SG_ 1413 SI_Bus_Identifikation 0;
BA_ "GenSigSendType" SG_ 1413 SI_CAB_V14 3;
BA_ "GenSigSwitchedByIgnition" SG_ 1413 SI_CAB_V14 0;
BA_ "GenSigSendType" SG_ 1413 SI_Diagnose_Aktiv 3;
BA_ "GenSigSwitchedByIgnition" SG_ 1413 SI_Diagnose_Aktiv 0;
BA_ "GenSigSendType" SG_ 1413 SI_NWDF 3;
BA_ "GenSigSwitchedByIgnition" SG_ 1413 SI_NWDF 0;
BA_ "GenSigSendType" SG_ 1413 SI_NWDF_30 3;
BA_ "GenSigSwitchedByIgnition" SG_ 1413 SI_NWDF_30 0;
BA_ "GenSigSendType" SG_ 1413 SI_NWDF_gueltig 3;
BA_ "GenSigFuncType" SG_ 1413 SI_NWDF_gueltig 8;
BA_ "GenSigSwitchedByIgnition" SG_ 1413 SI_NWDF_gueltig 0;
BA_ "GenSigSendType" SG_ 1413 SI_P_Mode 3;
BA_ "GenSigSwitchedByIgnition" SG_ 1413 SI_P_Mode 0;
BA_ "GenSigSendType" SG_ 1413 SI_P_Mode_gueltig 3;
BA_ "GenSigSwitchedByIgnition" SG_ 1413 SI_P_Mode_gueltig 0;
BA_ "GenSigSendType" SG_ 1413 SI_QRS_Mode 3;
BA_ "GenSigSwitchedByIgnition" SG_ 1413 SI_QRS_Mode 0;
BA_ "GenSigSendType" SG_ 1413 SI_Sammel_SG_Fehler 0;
BA_ "GenSigStartValue" SG_ 1413 SI_Sammel_SG_Fehler 63;
BA_ "GenSigSwitchedByIgnition" SG_ 1413 SI_Sammel_SG_Fehler 0;
BA_ "GenSigSendType" SG_ 1413 SI_Sammelfehler 3;
BA_ "GenSigSwitchedByIgnition" SG_ 1413 SI_Sammelfehler 0;
BA_ "GenSigSendType" SG_ 1413 SI_T_Mode 3;
BA_ "GenSigSwitchedByIgnition" SG_ 1413 SI_T_Mode 0;
BA_ "GenSigSendType" SG_ 1413 SI_T_Schutz 3;
BA_ "GenSigSwitchedByIgnition" SG_ 1413 SI_T_Schutz 0;
BA_ "GenSigSendType" SG_ 619 TA_01_BZ 0;
BA_ "GenSigFuncType" SG_ 619 TA_01_BZ 1;
BA_ "GenSigSendType" SG_ 619 TA_01_CRC 0;
BA_ "GenSigFuncType" SG_ 619 TA_01_CRC 2;
BA_ "GenSigSendType" SG_ 619 TA_ACC_Sollstatus 3;
BA_ "GenSigSendType" SG_ 619 TA_aktiv_HMI 0;
BA_ "GenSigSendType" SG_ 619 TA_Fehler 0;
BA_ "GenSigSendType" SG_ 619 TA_FoD_Status 3;
BA_ "GenSigSendType" SG_ 619 TA_FSW_Wartegrund_Umfeld 0;
BA_ "GenSigSendType" SG_ 619 TA_FSW_Warten 0;
BA_ "GenSigSendType" SG_ 619 TA_FSW_Zuruecklenken 0;
BA_ "GenSigSendType" SG_ 619 TA_Handsoff_LED 0;
BA_ "GenSigSendType" SG_ 619 TA_Spurwechsel 0;
BA_ "GenSigSendType" SG_ 619 TA_Spurwechsel_Ready 3;
BA_ "GenSigSendType" SG_ 619 TA_Status 0;
BA_ "GenSigSendType" SG_ 619 TA_Texte 0;
BA_ "GenSigSendType" SG_ 619 TA_Texte_02 0;
BA_ "GenSigSendType" SG_ 619 TA_Ueberholhilfe 0;
BA_ "GenSigSendType" SG_ 1001 Thermo_Pred_Innen_Kunde_Anf 0;
BA_ "GenSigSwitchedByIgnition" SG_ 1001 Thermo_Pred_Innen_Kunde_Anf 0;
BA_ "GenSigSendType" SG_ 1001 Thermo_Pred_Innen_System_Anf 0;
BA_ "GenSigSwitchedByIgnition" SG_ 1001 Thermo_Pred_Innen_System_Anf 0;
BA_ "GenSigSendType" SG_ 1001 Thermo_Pred_P_dyn_Innen 0;
BA_ "GenSigStartValue" SG_ 1001 Thermo_Pred_P_dyn_Innen 2046;
BA_ "GenSigSwitchedByIgnition" SG_ 1001 Thermo_Pred_P_dyn_Innen 0;
BA_ "Fehlerwert" SG_ 1001 Thermo_Pred_P_dyn_Innen 2047;
BA_ "GenSigSendType" SG_ 1001 Thermo_Pred_P_stat_Innen 0;
BA_ "GenSigStartValue" SG_ 1001 Thermo_Pred_P_stat_Innen 2046;
BA_ "GenSigSwitchedByIgnition" SG_ 1001 Thermo_Pred_P_stat_Innen 0;
BA_ "Fehlerwert" SG_ 1001 Thermo_Pred_P_stat_Innen 2047;
BA_ "GenSigSendType" SG_ 1001 Thermo_Pred_T_dyn_Innen 0;
BA_ "GenSigStartValue" SG_ 1001 Thermo_Pred_T_dyn_Innen 254;
BA_ "GenSigSwitchedByIgnition" SG_ 1001 Thermo_Pred_T_dyn_Innen 0;
BA_ "Fehlerwert" SG_ 1001 Thermo_Pred_T_dyn_Innen 255;
BA_ "GenSigSendType" SG_ 1001 Thermo_Verbrauch_BTL 0;
BA_ "GenSigSwitchedByIgnition" SG_ 1001 Thermo_Verbrauch_BTL 0;
BA_ "GenSigSendType" SG_ 1001 Thermo_Verbrauch_BTL_Ueberlauf 0;
BA_ "GenSigSwitchedByIgnition" SG_ 1001 Thermo_Verbrauch_BTL_Ueberlauf 0;
BA_ "GenSigSendType" SG_ 1001 Thermo_Verbrauch_Innen 0;
BA_ "GenSigSwitchedByIgnition" SG_ 1001 Thermo_Verbrauch_Innen 0;
BA_ "GenSigSendType" SG_ 1001 Thermo_Verbrauch_Innen_Ueberlauf 0;
BA_ "GenSigSwitchedByIgnition" SG_ 1001 Thermo_Verbrauch_Innen_Ueberlauf 0;
BA_ "GenSigSendType" SG_ 1447 bCall_active 3;
BA_ "GenSigSwitchedByIgnition" SG_ 1447 bCall_active 0;
BA_ "GenSigSendType" SG_ 1447 eCall_Funktionsstatus 0;
BA_ "GenSigSwitchedByIgnition" SG_ 1447 eCall_Funktionsstatus 0;
BA_ "GenSigSendType" SG_ 1447 eCall_Funktionsstatus_02 0;
BA_ "GenSigStartValue" SG_ 1447 eCall_Funktionsstatus_02 7;
BA_ "GenSigSwitchedByIgnition" SG_ 1447 eCall_Funktionsstatus_02 0;
BA_ "GenSigSendType" SG_ 1447 eCall_MCC 0;
BA_ "GenSigSwitchedByIgnition" SG_ 1447 eCall_MCC 0;
BA_ "GenSigSendType" SG_ 1447 eCall_Mute_Anf 3;
BA_ "GenSigSwitchedByIgnition" SG_ 1447 eCall_Mute_Anf 0;
BA_ "GenSigSendType" SG_ 1447 FaceRec_Enroll_Challenge_Request 3;
BA_ "GenSigSwitchedByIgnition" SG_ 1447 FaceRec_Enroll_Challenge_Request 0;
BA_ "GenSigSendType" SG_ 1447 FoD_Anz_Funktionsabschaltung 3;
BA_ "GenSigSwitchedByIgnition" SG_ 1447 FoD_Anz_Funktionsabschaltung 0;
BA_ "GenSigSendType" SG_ 1447 iCall_active 3;
BA_ "GenSigSwitchedByIgnition" SG_ 1447 iCall_active 0;
BA_ "GenSigSendType" SG_ 1447 MOD_Energie_Anf 0;
BA_ "GenSigSwitchedByIgnition" SG_ 1447 MOD_Energie_Anf 0;
BA_ "Fehlerwert" SG_ 1447 MOD_Energie_Anf 3;
BA_ "GenSigSendType" SG_ 1447 MOD_Request_ServiceKey 3;
BA_ "GenSigSwitchedByIgnition" SG_ 1447 MOD_Request_ServiceKey 0;
BA_ "GenSigSendType" SG_ 1447 ORU_KombiTimer 0;
BA_ "GenSigSwitchedByIgnition" SG_ 1447 ORU_KombiTimer 0;
BA_ "GenSigSendType" SG_ 1447 TM_Door_Lock 5;
BA_ "GenSigSwitchedByIgnition" SG_ 1447 TM_Door_Lock 0;
BA_ "GenSigSendType" SG_ 1447 TM_Door_Unlock 5;
BA_ "GenSigSwitchedByIgnition" SG_ 1447 TM_Door_Unlock 0;
BA_ "GenSigSendType" SG_ 1447 TM_Nur_Hupen 5;
BA_ "GenSigSwitchedByIgnition" SG_ 1447 TM_Nur_Hupen 0;
BA_ "GenSigSendType" SG_ 1447 TM_Panik_Alarm 5;
BA_ "GenSigSwitchedByIgnition" SG_ 1447 TM_Panik_Alarm 0;
BA_ "GenSigSendType" SG_ 1447 TM_Spiegel_Anklappen 5;
BA_ "GenSigSwitchedByIgnition" SG_ 1447 TM_Spiegel_Anklappen 0;
BA_ "GenSigSendType" SG_ 1447 TM_Warnblinken 5;
BA_ "GenSigSwitchedByIgnition" SG_ 1447 TM_Warnblinken 0;
BA_ "GenSigSendType" SG_ 1447 TM_ZV_Signatur 0;
BA_ "GenSigSwitchedByIgnition" SG_ 1447 TM_ZV_Signatur 0;
BA_ "GenSigSendType" SG_ 977 ASW_Warnung_aktiv_BFS 3;
BA_ "GenSigSwitchedByIgnition" SG_ 977 ASW_Warnung_aktiv_BFS 0;
BA_ "GenSigSendType" SG_ 977 BFS_Status_eTAG 0;
BA_ "GenSigSwitchedByIgnition" SG_ 977 BFS_Status_eTAG 0;
BA_ "Fehlerwert" SG_ 977 BFS_Status_eTAG 3;
BA_ "GenSigSendType" SG_ 977 BT_ASW_HMI_defekt 0;
BA_ "GenSigSwitchedByIgnition" SG_ 977 BT_ASW_HMI_defekt 0;
BA_ "GenSigSendType" SG_ 977 BT_EC_Spiegel_Helligkeit 3;
BA_ "GenSigSwitchedByIgnition" SG_ 977 BT_EC_Spiegel_Helligkeit 0;
BA_ "GenSigSendType" SG_ 977 BT_FH_Bew_hoch 3;
BA_ "GenSigSwitchedByIgnition" SG_ 977 BT_FH_Bew_hoch 0;
BA_ "GenSigSendType" SG_ 977 BT_FH_Bew_tief 3;
BA_ "GenSigSwitchedByIgnition" SG_ 977 BT_FH_Bew_tief 0;
BA_ "GenSigSendType" SG_ 977 BT_FH_Block 3;
BA_ "GenSigSwitchedByIgnition" SG_ 977 BT_FH_Block 0;
BA_ "GenSigSendType" SG_ 977 BT_FH_Fang 3;
BA_ "GenSigSwitchedByIgnition" SG_ 977 BT_FH_Fang 0;
BA_ "GenSigSendType" SG_ 977 BT_FH_normiert 3;
BA_ "GenSigSwitchedByIgnition" SG_ 977 BT_FH_normiert 0;
BA_ "GenSigSendType" SG_ 977 BT_FH_Oeffnung 3;
BA_ "GenSigSwitchedByIgnition" SG_ 977 BT_FH_Oeffnung 0;
BA_ "GenSigSendType" SG_ 977 BT_FH_Pos_oben 3;
BA_ "GenSigSwitchedByIgnition" SG_ 977 BT_FH_Pos_oben 0;
BA_ "GenSigSendType" SG_ 977 BT_FH_S_AutoHoch 3;
BA_ "GenSigSwitchedByIgnition" SG_ 977 BT_FH_S_AutoHoch 0;
BA_ "GenSigSendType" SG_ 977 BT_FH_S_AutoTief 3;
BA_ "GenSigSwitchedByIgnition" SG_ 977 BT_FH_S_AutoTief 0;
BA_ "GenSigSendType" SG_ 977 BT_FH_S_ManHoch 3;
BA_ "GenSigSwitchedByIgnition" SG_ 977 BT_FH_S_ManHoch 0;
BA_ "GenSigSendType" SG_ 977 BT_FH_S_ManTief 3;
BA_ "GenSigSwitchedByIgnition" SG_ 977 BT_FH_S_ManTief 0;
BA_ "GenSigSendType" SG_ 977 BT_FH_Thermo 3;
BA_ "GenSigSwitchedByIgnition" SG_ 977 BT_FH_Thermo 0;
BA_ "GenSigSendType" SG_ 977 BT_gesafet 3;
BA_ "GenSigSwitchedByIgnition" SG_ 977 BT_gesafet 0;
BA_ "GenSigSendType" SG_ 977 BT_Kisi_Fehler 3;
BA_ "GenSigSwitchedByIgnition" SG_ 977 BT_Kisi_Fehler 0;
BA_ "Fehlerwert" SG_ 977 BT_Kisi_Fehler 1;
BA_ "GenSigSendType" SG_ 977 BT_Lock_Taster 3;
BA_ "GenSigSwitchedByIgnition" SG_ 977 BT_Lock_Taster 0;
BA_ "GenSigSendType" SG_ 977 BT_Lock_Taster_inv 3;
BA_ "GenSigSwitchedByIgnition" SG_ 977 BT_Lock_Taster_inv 0;
BA_ "GenSigSendType" SG_ 977 BT_Lock_Unlock_Taster 3;
BA_ "GenSigSwitchedByIgnition" SG_ 977 BT_Lock_Unlock_Taster 0;
BA_ "GenSigSendType" SG_ 977 BT_Oben_Block_erw 3;
BA_ "GenSigSwitchedByIgnition" SG_ 977 BT_Oben_Block_erw 0;
BA_ "GenSigSendType" SG_ 977 BT_Schliesstaster 3;
BA_ "GenSigSwitchedByIgnition" SG_ 977 BT_Schliesstaster 0;
BA_ "GenSigSendType" SG_ 977 BT_Schluesselschalter_auf 3;
BA_ "GenSigSwitchedByIgnition" SG_ 977 BT_Schluesselschalter_auf 0;
BA_ "GenSigSendType" SG_ 977 BT_Schluesselschalter_zu 3;
BA_ "GenSigSwitchedByIgnition" SG_ 977 BT_Schluesselschalter_zu 0;
BA_ "GenSigSendType" SG_ 977 BT_Schluesselschalter_zu_inv 3;
BA_ "GenSigSwitchedByIgnition" SG_ 977 BT_Schluesselschalter_zu_inv 0;
BA_ "GenSigSendType" SG_ 977 BT_SP_ausgerastet 3;
BA_ "GenSigSwitchedByIgnition" SG_ 977 BT_SP_ausgerastet 0;
BA_ "GenSigSendType" SG_ 977 BT_Sp_Blk_def 3;
BA_ "GenSigSwitchedByIgnition" SG_ 977 BT_Sp_Blk_def 0;
BA_ "GenSigSendType" SG_ 977 BT_SP_Heizung_aktiv 3;
BA_ "GenSigSwitchedByIgnition" SG_ 977 BT_SP_Heizung_aktiv 0;
BA_ "GenSigSendType" SG_ 977 BT_Sp_Heizung_Anf 0;
BA_ "GenSigSwitchedByIgnition" SG_ 977 BT_Sp_Heizung_Anf 0;
BA_ "GenSigSendType" SG_ 977 BT_SP_Heizung_Status 3;
BA_ "GenSigSwitchedByIgnition" SG_ 977 BT_SP_Heizung_Status 0;
BA_ "GenSigSendType" SG_ 977 BT_SP_ht_aktiv 3;
BA_ "GenSigSwitchedByIgnition" SG_ 977 BT_SP_ht_aktiv 0;
BA_ "GenSigSendType" SG_ 977 BT_SP_lr_aktiv 3;
BA_ "GenSigSwitchedByIgnition" SG_ 977 BT_SP_lr_aktiv 0;
BA_ "GenSigSendType" SG_ 977 BT_Sperrklinke 3;
BA_ "GenSigSwitchedByIgnition" SG_ 977 BT_Sperrklinke 0;
BA_ "GenSigSendType" SG_ 977 BT_SWA_HMI_defekt 0;
BA_ "GenSigSwitchedByIgnition" SG_ 977 BT_SWA_HMI_defekt 0;
BA_ "GenSigSendType" SG_ 977 BT_TAG_betaetigt 3;
BA_ "GenSigSwitchedByIgnition" SG_ 977 BT_TAG_betaetigt 0;
BA_ "GenSigSendType" SG_ 977 BT_TCR_Mode_aktiv 3;
BA_ "GenSigSwitchedByIgnition" SG_ 977 BT_TCR_Mode_aktiv 0;
BA_ "GenSigSendType" SG_ 977 BT_TIG_betaetigt 3;
BA_ "GenSigSwitchedByIgnition" SG_ 977 BT_TIG_betaetigt 0;
BA_ "GenSigSendType" SG_ 977 BT_TSG_hinten_verbaut 3;
BA_ "GenSigSwitchedByIgnition" SG_ 977 BT_TSG_hinten_verbaut 0;
BA_ "GenSigSendType" SG_ 977 BT_Tuer_geoeffnet 3;
BA_ "GenSigSwitchedByIgnition" SG_ 977 BT_Tuer_geoeffnet 0;
BA_ "GenSigSendType" SG_ 977 BT_Tuer_Status 3;
BA_ "GenSigSwitchedByIgnition" SG_ 977 BT_Tuer_Status 0;
BA_ "Fehlerwert" SG_ 977 BT_Tuer_Status 3;
BA_ "GenSigSendType" SG_ 977 BT_Tuer_Status_QBit 0;
BA_ "GenSigSwitchedByIgnition" SG_ 977 BT_Tuer_Status_QBit 0;
BA_ "GenSigSendType" SG_ 977 BT_Tueroeffnen_Warnung 3;
BA_ "GenSigSwitchedByIgnition" SG_ 977 BT_Tueroeffnen_Warnung 0;
BA_ "GenSigSendType" SG_ 977 BT_Tuerschloss_defekt 0;
BA_ "GenSigSwitchedByIgnition" SG_ 977 BT_Tuerschloss_defekt 0;
BA_ "GenSigSendType" SG_ 977 BT_UEKB_aktiviert 3;
BA_ "GenSigSwitchedByIgnition" SG_ 977 BT_UEKB_aktiviert 0;
BA_ "GenSigSendType" SG_ 977 BT_Unlock_Taster 3;
BA_ "GenSigSwitchedByIgnition" SG_ 977 BT_Unlock_Taster 0;
BA_ "GenSigSendType" SG_ 977 BT_Unten_Block_erw 3;
BA_ "GenSigSwitchedByIgnition" SG_ 977 BT_Unten_Block_erw 0;
BA_ "GenSigSendType" SG_ 977 BT_verriegelt 3;
BA_ "GenSigSwitchedByIgnition" SG_ 977 BT_verriegelt 0;
BA_ "GenSigSendType" SG_ 977 BT_Zuziehhilfe_aktiv 3;
BA_ "GenSigSwitchedByIgnition" SG_ 977 BT_Zuziehhilfe_aktiv 0;
BA_ "GenSigSendType" SG_ 976 ASW_HMI_defekt 0;
BA_ "GenSigSwitchedByIgnition" SG_ 976 ASW_HMI_defekt 0;
BA_ "GenSigSendType" SG_ 976 ASW_wakeup 3;
BA_ "GenSigSwitchedByIgnition" SG_ 976 ASW_wakeup 0;
BA_ "GenSigSendType" SG_ 976 ASW_Warnung_aktiv_FS 3;
BA_ "GenSigSwitchedByIgnition" SG_ 976 ASW_Warnung_aktiv_FS 0;
BA_ "GenSigSendType" SG_ 976 FS_Status_eTAG 3;
BA_ "GenSigSwitchedByIgnition" SG_ 976 FS_Status_eTAG 0;
BA_ "Fehlerwert" SG_ 976 FS_Status_eTAG 3;
BA_ "GenSigSendType" SG_ 976 FT_BFS_Fond_Freigabe 3;
BA_ "GenSigSwitchedByIgnition" SG_ 976 FT_BFS_Fond_Freigabe 0;
BA_ "GenSigSendType" SG_ 976 FT_Daemmglas 3;
BA_ "GenSigSwitchedByIgnition" SG_ 976 FT_Daemmglas 0;
BA_ "GenSigSendType" SG_ 976 FT_FH_Bew_hoch 3;
BA_ "GenSigSwitchedByIgnition" SG_ 976 FT_FH_Bew_hoch 0;
BA_ "GenSigSendType" SG_ 976 FT_FH_Bew_tief 3;
BA_ "GenSigSwitchedByIgnition" SG_ 976 FT_FH_Bew_tief 0;
BA_ "GenSigSendType" SG_ 976 FT_FH_Block 3;
BA_ "GenSigSwitchedByIgnition" SG_ 976 FT_FH_Block 0;
BA_ "GenSigSendType" SG_ 976 FT_FH_Fang 3;
BA_ "GenSigSwitchedByIgnition" SG_ 976 FT_FH_Fang 0;
BA_ "GenSigSendType" SG_ 976 FT_FH_normiert 3;
BA_ "GenSigSwitchedByIgnition" SG_ 976 FT_FH_normiert 0;
BA_ "GenSigSendType" SG_ 976 FT_FH_Oeffnung 3;
BA_ "GenSigSwitchedByIgnition" SG_ 976 FT_FH_Oeffnung 0;
BA_ "GenSigSendType" SG_ 976 FT_FH_Pos_oben 3;
BA_ "GenSigSwitchedByIgnition" SG_ 976 FT_FH_Pos_oben 0;
BA_ "GenSigSendType" SG_ 976 FT_FH_S_AutoHoch 3;
BA_ "GenSigSwitchedByIgnition" SG_ 976 FT_FH_S_AutoHoch 0;
BA_ "GenSigSendType" SG_ 976 FT_FH_S_AutoTief 3;
BA_ "GenSigSwitchedByIgnition" SG_ 976 FT_FH_S_AutoTief 0;
BA_ "GenSigSendType" SG_ 976 FT_FH_S_ManHoch 3;
BA_ "GenSigSwitchedByIgnition" SG_ 976 FT_FH_S_ManHoch 0;
BA_ "GenSigSendType" SG_ 976 FT_FH_S_ManTief 3;
BA_ "GenSigSwitchedByIgnition" SG_ 976 FT_FH_S_ManTief 0;
BA_ "GenSigSendType" SG_ 976 FT_FH_Thermo 3;
BA_ "GenSigSwitchedByIgnition" SG_ 976 FT_FH_Thermo 0;
BA_ "GenSigSendType" SG_ 976 FT_gesafet 3;
BA_ "GenSigSwitchedByIgnition" SG_ 976 FT_gesafet 0;
BA_ "GenSigSendType" SG_ 976 FT_HD_Taste 3;
BA_ "GenSigSwitchedByIgnition" SG_ 976 FT_HD_Taste 0;
BA_ "GenSigSendType" SG_ 976 FT_HD_Taste_2 3;
BA_ "GenSigSwitchedByIgnition" SG_ 976 FT_HD_Taste_2 0;
BA_ "GenSigSendType" SG_ 976 FT_IRUE_Taste 3;
BA_ "GenSigSwitchedByIgnition" SG_ 976 FT_IRUE_Taste 0;
BA_ "GenSigSendType" SG_ 976 FT_Kisi_Fehler 3;
BA_ "GenSigSwitchedByIgnition" SG_ 976 FT_Kisi_Fehler 0;
BA_ "Fehlerwert" SG_ 976 FT_Kisi_Fehler 1;
BA_ "GenSigSendType" SG_ 976 FT_Kisi_li_aktiv 3;
BA_ "GenSigSwitchedByIgnition" SG_ 976 FT_Kisi_li_aktiv 0;
BA_ "GenSigSendType" SG_ 976 FT_Kisi_re_aktiv 3;
BA_ "GenSigSwitchedByIgnition" SG_ 976 FT_Kisi_re_aktiv 0;
BA_ "GenSigSendType" SG_ 976 FT_Kisi_Taster_li 3;
BA_ "GenSigSwitchedByIgnition" SG_ 976 FT_Kisi_Taster_li 0;
BA_ "GenSigSendType" SG_ 976 FT_Kisi_Taster_re 3;
BA_ "GenSigSwitchedByIgnition" SG_ 976 FT_Kisi_Taster_re 0;
BA_ "GenSigSendType" SG_ 976 FT_Lock_Taster 3;
BA_ "GenSigSwitchedByIgnition" SG_ 976 FT_Lock_Taster 0;
BA_ "GenSigSendType" SG_ 976 FT_Lock_Unlock_Taster 3;
BA_ "GenSigSwitchedByIgnition" SG_ 976 FT_Lock_Unlock_Taster 0;
BA_ "GenSigSendType" SG_ 976 FT_Oben_Block_erw 3;
BA_ "GenSigSwitchedByIgnition" SG_ 976 FT_Oben_Block_erw 0;
BA_ "GenSigSendType" SG_ 976 FT_Schliesstaster 3;
BA_ "GenSigSwitchedByIgnition" SG_ 976 FT_Schliesstaster 0;
BA_ "GenSigSendType" SG_ 976 FT_Schluesselschalter_auf 3;
BA_ "GenSigSwitchedByIgnition" SG_ 976 FT_Schluesselschalter_auf 0;
BA_ "GenSigSendType" SG_ 976 FT_Schluesselschalter_zu 3;
BA_ "GenSigSwitchedByIgnition" SG_ 976 FT_Schluesselschalter_zu 0;
BA_ "GenSigSendType" SG_ 976 FT_SP_ausgerastet 3;
BA_ "GenSigSwitchedByIgnition" SG_ 976 FT_SP_ausgerastet 0;
BA_ "GenSigSendType" SG_ 976 FT_Sp_Blk_def 3;
BA_ "GenSigSwitchedByIgnition" SG_ 976 FT_Sp_Blk_def 0;
BA_ "GenSigSendType" SG_ 976 FT_Sp_Heizung_Anf 0;
BA_ "GenSigSwitchedByIgnition" SG_ 976 FT_Sp_Heizung_Anf 0;
BA_ "GenSigSendType" SG_ 976 FT_SP_Heizung_Status 3;
BA_ "GenSigSwitchedByIgnition" SG_ 976 FT_SP_Heizung_Status 0;
BA_ "GenSigSendType" SG_ 976 FT_SP_ht_aktiv 3;
BA_ "GenSigSwitchedByIgnition" SG_ 976 FT_SP_ht_aktiv 0;
BA_ "GenSigSendType" SG_ 976 FT_SP_lr_aktiv 3;
BA_ "GenSigSwitchedByIgnition" SG_ 976 FT_SP_lr_aktiv 0;
BA_ "GenSigSendType" SG_ 976 FT_Sperrklinke 3;
BA_ "GenSigSwitchedByIgnition" SG_ 976 FT_Sperrklinke 0;
BA_ "GenSigSendType" SG_ 976 FT_SWA_Taster 3;
BA_ "GenSigSwitchedByIgnition" SG_ 976 FT_SWA_Taster 0;
BA_ "GenSigSendType" SG_ 976 FT_TAG_betaetigt 3;
BA_ "GenSigSwitchedByIgnition" SG_ 976 FT_TAG_betaetigt 0;
BA_ "GenSigSendType" SG_ 976 FT_TD_Taste 3;
BA_ "GenSigSwitchedByIgnition" SG_ 976 FT_TD_Taste 0;
BA_ "GenSigSendType" SG_ 976 FT_TD_Taste_Fehler 0;
BA_ "GenSigSwitchedByIgnition" SG_ 976 FT_TD_Taste_Fehler 0;
BA_ "GenSigSendType" SG_ 976 FT_TIG_betaetigt 3;
BA_ "GenSigSwitchedByIgnition" SG_ 976 FT_TIG_betaetigt 0;
BA_ "GenSigSendType" SG_ 976 FT_TSG_hinten_verbaut 3;
BA_ "GenSigSwitchedByIgnition" SG_ 976 FT_TSG_hinten_verbaut 0;
BA_ "GenSigSendType" SG_ 976 FT_Tuer_geoeffnet 3;
BA_ "GenSigSwitchedByIgnition" SG_ 976 FT_Tuer_geoeffnet 0;
BA_ "GenSigSendType" SG_ 976 FT_Tuerschloss_defekt 0;
BA_ "GenSigSwitchedByIgnition" SG_ 976 FT_Tuerschloss_defekt 0;
BA_ "GenSigSendType" SG_ 976 FT_UEKB_aktiviert 3;
BA_ "GenSigSwitchedByIgnition" SG_ 976 FT_UEKB_aktiviert 0;
BA_ "GenSigSendType" SG_ 976 FT_Unlock_Taster 3;
BA_ "GenSigSwitchedByIgnition" SG_ 976 FT_Unlock_Taster 0;
BA_ "GenSigSendType" SG_ 976 FT_Unten_Block_erw 3;
BA_ "GenSigSwitchedByIgnition" SG_ 976 FT_Unten_Block_erw 0;
BA_ "GenSigSendType" SG_ 976 FT_verriegelt 3;
BA_ "GenSigSwitchedByIgnition" SG_ 976 FT_verriegelt 0;
BA_ "GenSigSendType" SG_ 976 FT_Zuziehhilfe_aktiv 3;
BA_ "GenSigSwitchedByIgnition" SG_ 976 FT_Zuziehhilfe_aktiv 0;
BA_ "GenSigSendType" SG_ 976 SSR_Temp_Freigabe 0;
BA_ "GenSigSwitchedByIgnition" SG_ 976 SSR_Temp_Freigabe 0;
BA_ "GenSigSendType" SG_ 976 SWA_HMI_Diagnose 0;
BA_ "GenSigSwitchedByIgnition" SG_ 976 SWA_HMI_Diagnose 0;
BA_REL_ "GenSigTimeoutTime" BU_SG_REL_ ELV SG_ 1413 SI_NWDF 5000;
BA_REL_ "GenSigTimeoutTime" BU_SG_REL_ ELV SG_ 1413 SI_NWDF_gueltig 5000;
BA_REL_ "GenSigTimeoutTime" BU_SG_REL_ ELV SG_ 976 FT_Tuer_geoeffnet 1000;
BA_REL_ "GenSigTimeoutTime" BU_SG_REL_ HUD SG_ 1440 LS_Helligkeit_FW 2000;
BA_REL_ "GenSigTimeoutTime" BU_SG_REL_ HUD SG_ 1440 RLS_Vorfeldhelligkeit_Boost 2000;
BA_REL_ "GenSigTimeoutTime" BU_SG_REL_ HUD SG_ 1522 KBI_Phototransistor 2000;
BA_REL_ "GenSigTimeoutTime" BU_SG_REL_ HUD SG_ 1413 SI_QRS_Mode 5000;
BA_REL_ "GenSigTimeoutTime" BU_SG_REL_ HUD SG_ 1413 SI_T_Mode 5000;
BA_REL_ "GenSigTimeoutTime" BU_SG_REL_ HUD SG_ 1413 SI_NWDF 5000;
BA_REL_ "GenSigTimeoutTime" BU_SG_REL_ HUD SG_ 1413 SI_NWDF_gueltig 5000;
BA_REL_ "GenSigTimeoutTime" BU_SG_REL_ HUD SG_ 619 TA_Status 1000;
BA_REL_ "GenSigTimeoutTime" BU_SG_REL_ HUD SG_ 619 TA_Spurwechsel 1000;
BA_REL_ "GenSigTimeoutTime" BU_SG_REL_ HUD SG_ 619 TA_Texte 1000;
BA_REL_ "GenSigTimeoutTime" BU_SG_REL_ HUD SG_ 619 TA_Texte_02 1000;
BA_REL_ "GenSigTimeoutTime" BU_SG_REL_ HUD SG_ 619 TA_aktiv_HMI 1000;
BA_REL_ "GenSigTimeoutTime" BU_SG_REL_ HUD SG_ 619 TA_Fehler 1000;
BA_REL_ "GenSigTimeoutTime" BU_SG_REL_ HUD SG_ 619 TA_FSW_Wartegrund_Umfeld 1000;
BA_REL_ "GenSigTimeoutTime" BU_SG_REL_ HUD SG_ 619 TA_FSW_Warten 1000;
BA_REL_ "GenSigTimeoutTime" BU_SG_REL_ HUD SG_ 977 BT_Tuer_geoeffnet 1000;
BA_REL_ "GenSigTimeoutTime" BU_SG_REL_ Kombi SG_ 2527679748 TPMS_Warn1 2000;
BA_REL_ "GenSigTimeoutTime" BU_SG_REL_ Kombi SG_ 2527679748 TPMS_Warn2 2000;
BA_REL_ "GenSigTimeoutTime" BU_SG_REL_ Kombi SG_ 2527679748 TPMS_Warn3 2000;
BA_REL_ "GenSigTimeoutTime" BU_SG_REL_ Kombi SG_ 2527679748 TPMS_WarnLmpStMil 2000;
BA_REL_ "GenSigTimeoutTime" BU_SG_REL_ Kombi SG_ 2527679748 TPMS_WarnTmpFlt 2000;
BA_REL_ "GenSigTimeoutTime" BU_SG_REL_ Kombi SG_ 2527679748 TPMS_WarnFltIdc 2000;
BA_REL_ "GenSigTimeoutTime" BU_SG_REL_ Kombi SG_ 2527679748 TPMS_WarnLmpStP 2000;
BA_REL_ "GenSigTimeoutTime" BU_SG_REL_ Kombi SG_ 1525 RW_Gesamt_Reichweite_Max_Anzeige 5000;
BA_REL_ "GenSigTimeoutTime" BU_SG_REL_ Kombi SG_ 1525 RW_Gesamt_Reichweite 5000;
BA_REL_ "GenSigTimeoutTime" BU_SG_REL_ Kombi SG_ 1525 RW_Prim_Reichweitenverbrauch 5000;
BA_REL_ "GenSigTimeoutTime" BU_SG_REL_ Kombi SG_ 1525 RW_Prim_Reichweitenv_Einheit 5000;
BA_REL_ "GenSigTimeoutTime" BU_SG_REL_ Kombi SG_ 1525 RW_Primaer_Reichweite 5000;
BA_REL_ "GenSigTimeoutTime" BU_SG_REL_ Kombi SG_ 1527 RW_Texte 5000;
BA_REL_ "GenSigTimeoutTime" BU_SG_REL_ Kombi SG_ 1527 RW_Reservewarnung_aktiv 5000;
BA_REL_ "GenSigTimeoutTime" BU_SG_REL_ Kombi SG_ 1527 RW_Reichweite_Einheit_Anzeige 5000;
BA_REL_ "GenSigTimeoutTime" BU_SG_REL_ Kombi SG_ 1527 RW_Gesamt_Reichweite_Anzeige 5000;
BA_REL_ "GenSigTimeoutTime" BU_SG_REL_ Kombi SG_ 1527 RW_Primaer_Reichweite_Anzeige 5000;
BA_REL_ "GenSigTimeoutTime" BU_SG_REL_ Kombi SG_ 1527 RW_Sekundaer_Reichweite_Anzeige 5000;
BA_REL_ "GenSigTimeoutTime" BU_SG_REL_ Kombi SG_ 1527 RW_Sekundaer_Reichweite 5000;
BA_REL_ "GenSigTimeoutTime" BU_SG_REL_ Kombi SG_ 1527 RW_Sek_Reichweitenv_Einheit 5000;
BA_REL_ "GenSigTimeoutTime" BU_SG_REL_ Kombi SG_ 1527 RW_Sek_Reichweitenverbrauch 5000;
BA_REL_ "GenSigTimeoutTime" BU_SG_REL_ Kombi SG_ 2331596042 RHP_02_CRC 500;
BA_REL_ "GenSigTimeoutTime" BU_SG_REL_ Kombi SG_ 2331596042 RHP_02_BZ 500;
BA_REL_ "GenSigTimeoutTime" BU_SG_REL_ Kombi SG_ 2331596042 RHP_Wunschgeschw 500;
BA_REL_ "GenSigTimeoutTime" BU_SG_REL_ Kombi SG_ 2331596042 RHP_Wunschgeschw_Farbe 500;
BA_REL_ "GenSigTimeoutTime" BU_SG_REL_ Kombi SG_ 2331596042 RHP_Text_02 500;
BA_REL_ "GenSigTimeoutTime" BU_SG_REL_ Kombi SG_ 2331596042 RHP_Gong 500;
BA_REL_ "GenSigTimeoutTime" BU_SG_REL_ Kombi SG_ 2331596042 RHP_Tempolimit 500;
BA_REL_ "GenSigTimeoutTime" BU_SG_REL_ Kombi SG_ 2331596042 RHP_Tempolimit_Farbe 500;
BA_REL_ "GenSigTimeoutTime" BU_SG_REL_ Kombi SG_ 2331596042 RHP_Texte_Sekundaeranz 500;
BA_REL_ "GenSigTimeoutTime" BU_SG_REL_ Kombi SG_ 2331596042 RHP_aktiv_HMI 500;
BA_REL_ "GenSigTimeoutTime" BU_SG_REL_ Kombi SG_ 2331596042 RHP_Anzeige_Objektregelung 500;
BA_REL_ "GenSigTimeoutTime" BU_SG_REL_ Kombi SG_ 2331596042 RHP_HMI_DetectedLane 500;
BA_REL_ "GenSigTimeoutTime" BU_SG_REL_ Kombi SG_ 2331596042 RHP_HMI_Ego_li_Anzeige 500;
BA_REL_ "GenSigTimeoutTime" BU_SG_REL_ Kombi SG_ 2331596042 RHP_HMI_Ego_li_Seg1_QuerAbst 500;
BA_REL_ "GenSigTimeoutTime" BU_SG_REL_ Kombi SG_ 2331596042 RHP_HMI_Ego_li_Typ 500;
BA_REL_ "GenSigTimeoutTime" BU_SG_REL_ Kombi SG_ 2331596042 RHP_HMI_Ego_re_Anzeige 500;
BA_REL_ "GenSigTimeoutTime" BU_SG_REL_ Kombi SG_ 2331596042 RHP_HMI_Ego_re_Seg1_QuerAbst 500;
BA_REL_ "GenSigTimeoutTime" BU_SG_REL_ Kombi SG_ 2331596042 RHP_HMI_Ego_re_Typ 500;
BA_REL_ "GenSigTimeoutTime" BU_SG_REL_ Kombi SG_ 2331596042 RHP_HMI_EgoObj_dy 500;
BA_REL_ "GenSigTimeoutTime" BU_SG_REL_ Kombi SG_ 2331596042 RHP_HMI_Kurvenwarnung 500;
BA_REL_ "GenSigTimeoutTime" BU_SG_REL_ Kombi SG_ 2331596042 RHP_HMI_LaneChangeIndicator 500;
BA_REL_ "GenSigTimeoutTime" BU_SG_REL_ Kombi SG_ 2331596042 RHP_HMI_LaneChangeTrajectory 500;
BA_REL_ "GenSigTimeoutTime" BU_SG_REL_ Kombi SG_ 2331596042 RHP_HMI_Nachb_li_Anzeige 500;
BA_REL_ "GenSigTimeoutTime" BU_SG_REL_ Kombi SG_ 2331596042 RHP_HMI_Nachb_li_Seg1_QuerAbst 500;
BA_REL_ "GenSigTimeoutTime" BU_SG_REL_ Kombi SG_ 2331596042 RHP_HMI_Nachb_li_Typ 500;
BA_REL_ "GenSigTimeoutTime" BU_SG_REL_ Kombi SG_ 2331596042 RHP_HMI_Nachb_re_Anzeige 500;
BA_REL_ "GenSigTimeoutTime" BU_SG_REL_ Kombi SG_ 2331596042 RHP_HMI_Nachb_re_Seg1_QuerAbst 500;
BA_REL_ "GenSigTimeoutTime" BU_SG_REL_ Kombi SG_ 2331596042 RHP_HMI_Nachb_re_Typ 500;
BA_REL_ "GenSigTimeoutTime" BU_SG_REL_ Kombi SG_ 2331596042 RHP_Abstand_WZO 500;
BA_REL_ "GenSigTimeoutTime" BU_SG_REL_ Kombi SG_ 2331596042 RHP_Sollabstand_1 500;
BA_REL_ "GenSigTimeoutTime" BU_SG_REL_ Kombi SG_ 2331596042 RHP_Sollabstand_2 500;
BA_REL_ "GenSigTimeoutTime" BU_SG_REL_ Kombi SG_ 2331596042 RHP_Sollabstand_3 500;
BA_REL_ "GenSigTimeoutTime" BU_SG_REL_ Kombi SG_ 2331596042 RHP_Sollabstand_4 500;
BA_REL_ "GenSigTimeoutTime" BU_SG_REL_ Kombi SG_ 2331596042 RHP_Sollabstand_5 500;
BA_REL_ "GenSigTimeoutTime" BU_SG_REL_ Kombi SG_ 2331596042 RHP_Anzeige_Zeitluecke 500;
BA_REL_ "GenSigTimeoutTime" BU_SG_REL_ Kombi SG_ 2331596042 RHP_Abstandsindex 500;
BA_REL_ "GenSigTimeoutTime" BU_SG_REL_ Kombi SG_ 2331596042 RHP_Abstand_LNS 500;
BA_REL_ "GenSigTimeoutTime" BU_SG_REL_ Kombi SG_ 2331596042 RHP_Abstand_RNS 500;
BA_REL_ "GenSigTimeoutTime" BU_SG_REL_ Kombi SG_ 2331596042 RHP_Typ_LNS 500;
BA_REL_ "GenSigTimeoutTime" BU_SG_REL_ Kombi SG_ 2331596042 RHP_Typ_RNS 500;
BA_REL_ "GenSigTimeoutTime" BU_SG_REL_ Kombi SG_ 2331596042 RHP_Typ_WZO 500;
BA_REL_ "GenSigTimeoutTime" BU_SG_REL_ Kombi SG_ 2331596042 RHP_Anzeige_Maximalabstand 500;
BA_REL_ "GenSigTimeoutTime" BU_SG_REL_ Kombi SG_ 2331596042 RHP_Regelgeschw 500;
BA_REL_ "GenSigTimeoutTime" BU_SG_REL_ Kombi SG_ 2331596042 RHP_EGO_Fahrzeug 500;
BA_REL_ "GenSigTimeoutTime" BU_SG_REL_ Kombi SG_ 2331596042 RHP_Relevantes_Objekt 500;
BA_REL_ "GenSigTimeoutTime" BU_SG_REL_ Kombi SG_ 2331596042 RHP_Tempolimit_Einheit 500;
BA_REL_ "GenSigTimeoutTime" BU_SG_REL_ Kombi SG_ 2331596042 RHP_maxSetzgeschw 500;
BA_REL_ "GenSigTimeoutTime" BU_SG_REL_ Kombi SG_ 2331596042 RHP_Einheit_maxSetzgeschw 500;
BA_REL_ "GenSigTimeoutTime" BU_SG_REL_ Kombi SG_ 2331596042 RHP_TOR_Lamp 500;
BA_REL_ "GenSigTimeoutTime" BU_SG_REL_ Kombi SG_ 2331596042 RHP_Gesetzte_Zeitluecke 500;
BA_REL_ "GenSigTimeoutTime" BU_SG_REL_ Kombi SG_ 2331596042 RHP_StatusLamp 500;
BA_REL_ "GenSigTimeoutTime" BU_SG_REL_ Kombi SG_ 2331596042 RHP_LateralLamp 500;
BA_REL_ "GenSigTimeoutTime" BU_SG_REL_ Kombi SG_ 2331596042 RHP_Text_01 500;
BA_REL_ "GenSigTimeoutTime" BU_SG_REL_ Kombi SG_ 2331596042 RHP_ErrorStatus 500;
BA_REL_ "GenSigTimeoutTime" BU_SG_REL_ Kombi SG_ 2331596042 RHP_Typ_CIO 500;
BA_REL_ "GenSigTimeoutTime" BU_SG_REL_ Kombi SG_ 2331596042 RHP_CIO 500;
BA_REL_ "GenSigTimeoutTime" BU_SG_REL_ Kombi SG_ 2331596042 RHP_Abstand_CIO 500;
BA_REL_ "GenSigTimeoutTime" BU_SG_REL_ Kombi SG_ 1610 RKA_FMVSS138_Lampe 5000;
BA_REL_ "GenSigTimeoutTime" BU_SG_REL_ Kombi SG_ 1610 RKA_FMVSS138_MIL 5000;
BA_REL_ "GenSigTimeoutTime" BU_SG_REL_ Kombi SG_ 1610 RKA_Warnungen_02 5000;
BA_REL_ "GenSigTimeoutTime" BU_SG_REL_ Kombi SG_ 1440 RS_defekt 2000;
BA_REL_ "GenSigTimeoutTime" BU_SG_REL_ Kombi SG_ 980 FAS_Taster 5000;
BA_REL_ "GenSigTimeoutTime" BU_SG_REL_ Kombi SG_ 980 FAS_Taster_Fehler 5000;
BA_REL_ "GenSigTimeoutTime" BU_SG_REL_ Kombi SG_ 980 LRH_On_Off 5000;
BA_REL_ "GenSigTimeoutTime" BU_SG_REL_ Kombi SG_ 980 LSS_Tastencode 5000;
BA_REL_ "GenSigTimeoutTime" BU_SG_REL_ Kombi SG_ 2527679739 STK_Voko_LED 5000;
BA_REL_ "GenSigTimeoutTime" BU_SG_REL_ Kombi SG_ 1313 STH_KVS 2000;
BA_REL_ "GenSigTimeoutTime" BU_SG_REL_ Kombi SG_ 1313 STH_Heizleistung 2000;
BA_REL_ "GenSigTimeoutTime" BU_SG_REL_ Kombi SG_ 1313 STH_Texte 2000;
BA_REL_ "GenSigTimeoutTime" BU_SG_REL_ Kombi SG_ 1313 STH_KVS_Ueberlauf 2000;
BA_REL_ "GenSigTimeoutTime" BU_SG_REL_ Kombi SG_ 1413 SI_Sammel_SG_Fehler 5000;
BA_REL_ "GenSigTimeoutTime" BU_SG_REL_ Kombi SG_ 1413 SI_P_Mode_gueltig 5000;
BA_REL_ "GenSigTimeoutTime" BU_SG_REL_ Kombi SG_ 1413 SI_QRS_Mode 5000;
BA_REL_ "GenSigTimeoutTime" BU_SG_REL_ Kombi SG_ 1413 SI_T_Mode 5000;
BA_REL_ "GenSigTimeoutTime" BU_SG_REL_ Kombi SG_ 1413 SI_NWDF 5000;
BA_REL_ "GenSigTimeoutTime" BU_SG_REL_ Kombi SG_ 1413 SI_NWDF_gueltig 5000;
BA_REL_ "GenSigTimeoutTime" BU_SG_REL_ Kombi SG_ 1413 SI_T_Schutz 5000;
BA_REL_ "GenSigTimeoutTime" BU_SG_REL_ Kombi SG_ 1413 SI_P_Mode 5000;
BA_REL_ "GenSigTimeoutTime" BU_SG_REL_ Kombi SG_ 1413 SI_BUS_01 5000;
BA_REL_ "GenSigTimeoutTime" BU_SG_REL_ Kombi SG_ 1413 SI_BUS_02 5000;
BA_REL_ "GenSigTimeoutTime" BU_SG_REL_ Kombi SG_ 1413 SI_BUS_03 5000;
BA_REL_ "GenSigTimeoutTime" BU_SG_REL_ Kombi SG_ 1413 SI_BUS_04 5000;
BA_REL_ "GenSigTimeoutTime" BU_SG_REL_ Kombi SG_ 1413 SI_BUS_05 5000;
BA_REL_ "GenSigTimeoutTime" BU_SG_REL_ Kombi SG_ 1413 SI_BUS_06 5000;
BA_REL_ "GenSigTimeoutTime" BU_SG_REL_ Kombi SG_ 1413 SI_BUS_10 5000;
BA_REL_ "GenSigTimeoutTime" BU_SG_REL_ Kombi SG_ 1413 SI_BUS_12 5000;
BA_REL_ "GenSigTimeoutTime" BU_SG_REL_ Kombi SG_ 1413 SI_BUS_13 5000;
BA_REL_ "GenSigTimeoutTime" BU_SG_REL_ Kombi SG_ 1413 SI_BUS_14 5000;
BA_REL_ "GenSigTimeoutTime" BU_SG_REL_ Kombi SG_ 1413 SI_Bus_Identifikation 5000;
BA_REL_ "GenSigTimeoutTime" BU_SG_REL_ Kombi SG_ 1413 SI_CAB_V14 5000;
BA_REL_ "GenSigTimeoutTime" BU_SG_REL_ Kombi SG_ 619 TA_Status 1000;
BA_REL_ "GenSigTimeoutTime" BU_SG_REL_ Kombi SG_ 619 TA_Spurwechsel 1000;
BA_REL_ "GenSigTimeoutTime" BU_SG_REL_ Kombi SG_ 619 TA_Texte 1000;
BA_REL_ "GenSigTimeoutTime" BU_SG_REL_ Kombi SG_ 619 TA_FoD_Status 1000;
BA_REL_ "GenSigTimeoutTime" BU_SG_REL_ Kombi SG_ 619 TA_Texte_02 1000;
BA_REL_ "GenSigTimeoutTime" BU_SG_REL_ Kombi SG_ 619 TA_Handsoff_LED 1000;
BA_REL_ "GenSigTimeoutTime" BU_SG_REL_ Kombi SG_ 619 TA_aktiv_HMI 1000;
BA_REL_ "GenSigTimeoutTime" BU_SG_REL_ Kombi SG_ 619 TA_Fehler 1000;
BA_REL_ "GenSigTimeoutTime" BU_SG_REL_ Kombi SG_ 619 TA_FSW_Wartegrund_Umfeld 1000;
BA_REL_ "GenSigTimeoutTime" BU_SG_REL_ Kombi SG_ 619 TA_FSW_Warten 1000;
BA_REL_ "GenSigTimeoutTime" BU_SG_REL_ Kombi SG_ 1001 Thermo_Verbrauch_BTL 1000;
BA_REL_ "GenSigTimeoutTime" BU_SG_REL_ Kombi SG_ 1001 Thermo_Verbrauch_BTL_Ueberlauf 1000;
BA_REL_ "GenSigTimeoutTime" BU_SG_REL_ Kombi SG_ 1001 Thermo_Verbrauch_Innen 1000;
BA_REL_ "GenSigTimeoutTime" BU_SG_REL_ Kombi SG_ 1001 Thermo_Verbrauch_Innen_Ueberlauf 1000;
BA_REL_ "GenSigTimeoutTime" BU_SG_REL_ Kombi SG_ 1447 ORU_KombiTimer 5000;
BA_REL_ "GenSigTimeoutTime" BU_SG_REL_ Kombi SG_ 1447 eCall_Mute_Anf 5000;
BA_REL_ "GenSigTimeoutTime" BU_SG_REL_ Kombi SG_ 1447 FoD_Anz_Funktionsabschaltung 5000;
BA_REL_ "GenSigTimeoutTime" BU_SG_REL_ Kombi SG_ 1447 MOD_Request_ServiceKey 5000;
BA_REL_ "GenSigTimeoutTime" BU_SG_REL_ Kombi SG_ 1447 eCall_Funktionsstatus 5000;
BA_REL_ "GenSigTimeoutTime" BU_SG_REL_ Kombi SG_ 976 FT_Kisi_Fehler 1000;
VAL_ 2527679748 TPMS_CalTyp 0 "TPMS_Table_Calibration" 1 "TPMS_Switch_Calibration" 2 "TPMS_Semiautomatic_Calibration" 3 "Reserved" ;
VAL_ 2527679748 TPMS_WhlChgDetFrLe 0 "No_wheel_change_detected" 1 "Wheel_change_detected" ;
VAL_ 2527679748 TPMS_WhlChgDetFrRi 0 "No_wheel_change_detected" 1 "Wheel_change_detected" ;
VAL_ 2527679748 TPMS_WhlChgDetReLe 0 "No_wheel_change_detected" 1 "Wheel_change_detected" ;
VAL_ 2527679748 TPMS_WhlChgDetReRi 0 "No_wheel_change_detected" 1 "Wheel_change_detected" ;
VAL_ 2527679748 TPMS_Warn1 0 "Warning_inactive" 1 "Warning_active" ;
VAL_ 2527679748 TPMS_Warn1TireFrLe 0 "Warning_inactive" 1 "Warning_active" ;
VAL_ 2527679748 TPMS_Warn1TireFrRi 0 "Warning_inactive" 1 "Warning_active" ;
VAL_ 2527679748 TPMS_Warn1TireReLe 0 "Warning_inactive" 1 "Warning_active" ;
VAL_ 2527679748 TPMS_Warn1TireReRi 0 "Warning_inactive" 1 "Warning_active" ;
VAL_ 2527679748 TPMS_Warn2 0 "Warning_inactive" 1 "Warning_active" ;
VAL_ 2527679748 TPMS_Warn2TireFrLe 0 "Warning_inactive" 1 "Warning_active" ;
VAL_ 2527679748 TPMS_Warn2TireFrRi 0 "Warning_inactive" 1 "Warning_active" ;
VAL_ 2527679748 TPMS_Warn2TireReLe 0 "Warning_inactive" 1 "Warning_active" ;
VAL_ 2527679748 TPMS_Warn2TireReRi 0 "Warning_inactive" 1 "Warning_active" ;
VAL_ 2527679748 TPMS_Warn3 0 "Warning_inactive" 1 "Warning_active" ;
VAL_ 2527679748 TPMS_Warn3TireFrLe 0 "Warning_inactive" 1 "Warning_active" ;
VAL_ 2527679748 TPMS_Warn3TireFrRi 0 "Warning_inactive" 1 "Warning_active" ;
VAL_ 2527679748 TPMS_Warn3TireReLe 0 "Warning_inactive" 1 "Warning_active" ;
VAL_ 2527679748 TPMS_Warn3TireReRi 0 "Warning_inactive" 1 "Warning_active" ;
VAL_ 2527679748 TPMS_Warn4 0 "Warning_inactive" 1 "Warning_active" ;
VAL_ 2527679748 TPMS_Warn4TireFrLe 0 "Warning_inactive" 1 "Warning_active" ;
VAL_ 2527679748 TPMS_Warn4TireFrRi 0 "Warning_inactive" 1 "Warning_active" ;
VAL_ 2527679748 TPMS_Warn4TireReLe 0 "Warning_inactive" 1 "Warning_active" ;
VAL_ 2527679748 TPMS_Warn4TireReRi 0 "Warning_inactive" 1 "Warning_active" ;
VAL_ 2527679748 TPMS_WarnCalOk 0 "Calibration_warning_inactive" 1 "Calibration_warning_active" ;
VAL_ 2527679748 TPMS_WarnLmpStMil 0 "TPMS_fault_indicator_inactive" 1 "TPMS_fault_indicator_active" ;
VAL_ 2527679748 TPMS_WarnSysLrn 0 "Warning_System_learns_inactive" 1 "Warning_System_learns_active" ;
VAL_ 2527679748 TPMS_WarnTmpFlt 0 "Warning_Temporary_fault_inactive" 1 "Warning_Temporary_fault_active" ;
VAL_ 2527679748 TPMS_WarnWhlChgDet 0 "Warning_wheel_change_detected_in" 1 "Warning_wheel_change_detected_ac" ;
VAL_ 2527679748 TPMS_RaceTrckMdSts 0 "Race_track_mode_inactive" 1 "Race_track_mode_active" ;
VAL_ 2527679748 TPMS_WarnAcoCalOk 0 "Acoustic_Calib_warning_inactive" 1 "Acoustic_Calib_warning_active" ;
VAL_ 2527679748 TPMS_WarnCmftP 0 "Warning_comfort_pressure_inactiv" 1 "Warning_comfort_pressure_active" ;
VAL_ 2527679748 TPMS_WarnFltIdc 0 "Warning_Fault_indication_inactiv" 1 "Warning_Fault_indication_active" ;
VAL_ 2527679748 TPMS_WarnFr 0 "Warning_inactive" 1 "Warning_active" ;
VAL_ 2527679748 TPMS_WarnLmpStP 0 "TPMS_Warning_lamp_P_inactive" 1 "TPMS_Warning_lamp_P_active" ;
VAL_ 2527679748 TPMS_WarnMaxV 0 "Warning_maxium_speed_inactive" 1 "Warning_maxium_speed_active" ;
VAL_ 2527679748 TPMS_WarnRaceTrckMdMinP 0 "RaceTrckMd_warn_min_p_inactive" 1 "RaceTrckMd_warn_min_p_active" ;
VAL_ 2527679748 TPMS_WarnRe 0 "Warning_inactive" 1 "Warning_active" ;
VAL_ 2527679748 TPMS_SensTFrLe 254 "Init" 255 "Fehler" ;
VAL_ 2527679748 TPMS_SensTFrRi 254 "Init" 255 "Fehler" ;
VAL_ 2527679748 TPMS_SensTReLe 254 "Init" 255 "Fehler" ;
VAL_ 2527679748 TPMS_SensTReRi 254 "Init" 255 "Fehler" ;
VAL_ 2527679748 TPMS_SensPFrLe 63 "Init" ;
VAL_ 2527679748 TPMS_SensPFrRi 63 "Init" ;
VAL_ 2527679748 TPMS_SensPReLe 63 "Init" ;
VAL_ 2527679748 TPMS_SensPReRi 63 "Init" ;
VAL_ 2527679748 TPMS_PDeFrLe 127 "Init" ;
VAL_ 2527679748 TPMS_PDeFrRi 127 "Init" ;
VAL_ 2527679748 TPMS_PDeReLe 127 "Init" ;
VAL_ 2527679748 TPMS_PDeReRi 127 "Init" ;
VAL_ 2527679748 TPMS_SensBattStsFrLe 126 "Init" 127 "Fehler" ;
VAL_ 2527679748 TPMS_SensBattStsFrRi 126 "Init" 127 "Fehler" ;
VAL_ 2527679748 TPMS_SensBattStsReLe 126 "Init" 127 "Fehler" ;
VAL_ 2527679748 TPMS_SensBattStsReRi 126 "Init" 127 "Fehler" ;
VAL_ 2527679748 TPMS_SensSigAgeFrLe 11 "Larger_than_10_minutes" 12 "Reserved" 13 "Reserved" 14 "Init" 15 "Fehler" ;
VAL_ 2527679748 TPMS_SensSigAgeFrRi 11 "Larger_than_10_minutes" 12 "Reserved" 13 "Reserved" 14 "Init" 15 "Fehler" ;
VAL_ 2527679748 TPMS_SensSigAgeReLe 11 "Larger_than_10_minutes" 12 "Reserved" 13 "Reserved" 14 "Init" 15 "Fehler" ;
VAL_ 2527679748 TPMS_SensSigAgeReRi 11 "Larger_than_10_minutes" 12 "Reserved" 13 "Reserved" 14 "Init" 15 "Fehler" ;
VAL_ 2527679748 TPMS_SensStsFrLe 0 "Sensor_is_working" 1 "Sensor_is_faulty" ;
VAL_ 2527679748 TPMS_SensStsFrRi 0 "Sensor_is_working" 1 "Sensor_is_faulty" ;
VAL_ 2527679748 TPMS_SensStsReLe 0 "Sensor_is_working" 1 "Sensor_is_faulty" ;
VAL_ 2527679748 TPMS_SensStsReRi 0 "Sensor_is_working" 1 "Sensor_is_faulty" ;
VAL_ 2527679748 TPMS_SensTypFrLe 0 "Wheel_electronics" 1 "Tire_sensor" ;
VAL_ 2527679748 TPMS_SensTypFrRi 0 "Wheel_electronics" 1 "Tire_sensors" ;
VAL_ 2527679748 TPMS_SensTypReLe 0 "Wheel_electronics" 1 "Tire_sensor" ;
VAL_ 2527679748 TPMS_SensTypReRi 0 "Wheel_electronics" 1 "Tire_sensor" ;
VAL_ 2527679748 TPMS_enable 0 "unchanged" 1 "enable" ;
VAL_ 2527679748 TPMS_disable 0 "unchanged" 1 "disable" ;
VAL_ 2527679748 TPMS_TarPTmpDepFrLe 63 "Init" ;
VAL_ 2527679748 TPMS_TarPTmpDepFrRi 63 "Init" ;
VAL_ 2527679748 TPMS_TarPTmpDepReLe 63 "Init" ;
VAL_ 2527679748 TPMS_TarPTmpDepReRi 63 "Init" ;
VAL_ 2527679748 TPMS_LearningState 0 "learning_possible" 1 "learning_starts_above_speedlevel" 2 "learning_run" 3 "learning_successfull_allocated" 4 "learning_not_possible" 5 "learning_unsuccessful" 6 "learning_successf_not_allocated" 7 "init" 8 "Fehler" ;
VAL_ 2527679742 Kam_Anf_Meldung 0 "Init" 1 "RBF_eingeschraenkt_Sensorsicht" 2 "RBF_eingeschraenkt_Reinigung" 3 "RBF_nicht_verfuegbar" 4 "RBF_Notbremsung" 5 "RBF_zurzeit_eingeschraenkt" 6 "RBF_eingeschraenkt_reinigen" ;
VAL_ 2527679742 Kam_PaCo_MainState 0 "Init" 1 "InOperation_NoError" 2 "Eingeschraenkt" 7 "Fehler" ;
VAL_ 1525 RW_Gesamt_Reichweite_Max_Anzeige 2045 "nicht_verbaut" 2046 "Init" 2047 "Fehler" ;
VAL_ 1525 RW_Reservewarnung_2_aktiv 0 "Init" 1 "inaktiv" 2 "aktiv" 3 "reserviert" ;
VAL_ 1525 RW_RWDS_Lastprofil 2046 "Init" 2047 "Fehler" ;
VAL_ 1525 RW_Gesamt_Reichweite 2045 "nicht_verbaut" 2046 "Init" 2047 "Fehler" ;
VAL_ 1525 RW_Prim_Reichweitenverbrauch 2047 "Init" ;
VAL_ 1525 RW_Prim_Reichweitenv_Einheit 0 "Liter_pro_100km" 1 "kWh_pro_100km" 2 "Kg_pro_100km" 3 "nicht_verbaut" ;
VAL_ 1525 RW_Primaer_Reichweite 2045 "nicht_verbaut" 2046 "Init" 2047 "Fehler" ;
VAL_ 1527 RW_Tendenz 0 "keine_Tendenz" 1 "konstant" 2 "steigend" 3 "sinkend" ;
VAL_ 1527 RW_Texte 0 "kein_Text" 1 "Text_1" 2 "Text_2" 3 "Text_3" ;
VAL_ 1527 RW_Reservewarnung_aktiv 0 "inaktiv" 1 "aktiv" ;
VAL_ 1527 RW_Reichweite_Einheit_Anzeige 0 "km" 1 "miles" ;
VAL_ 1527 RW_Gesamt_Reichweite_Anzeige 2045 "nicht_verbaut" 2046 "Init" 2047 "Fehler" ;
VAL_ 1527 RW_Primaer_Reichweite_Anzeige 2045 "nicht_verbaut" 2046 "Init" 2047 "Fehler" ;
VAL_ 1527 RW_Sekundaer_Reichweite_Anzeige 2045 "nicht_verbaut" 2046 "Init" 2047 "Fehler" ;
VAL_ 1527 RW_Sekundaer_Reichweite 2045 "nicht_verbaut" 2046 "Init" 2047 "Fehler" ;
VAL_ 1527 RW_Sek_Reichweitenv_Einheit 0 "Liter_pro_100km" 1 "kWh_pro_100km" 2 "Kg_pro_100km" 3 "nicht_verbaut" ;
VAL_ 1527 RW_Sek_Reichweitenverbrauch 2047 "Init" ;
VAL_ 1322 RES_TripReset 0 "NoAction" 1 "Reset" ;
VAL_ 1322 RES_AlQuitRem 0 "NoAction" 1 "QuitWarning" 2 "Error" 3 "NA" ;
VAL_ 2331596042 RHP_Wunschgeschw 1023 "keine_Anzeige" ;
VAL_ 2331596042 RHP_Wunschgeschw_Farbe 0 "Grundfarbe" 1 "Farbe_1" 2 "Farbe_2" 3 "Farbe_3" ;
VAL_ 2331596042 RHP_Text_02 0 "No_Dispaly" 1 "RHP_Selected" 2 "Not_in_ODD" 3 "No_Sensor_View" 4 "Too_Big_Slope" 5 "Parking_Brake_Active" 6 "ESP_intervention" 7 "HDC_is_active" 8 "Speed_Too_High" 9 "ESC_off" 10 "Gear_position_is_not_drive" 11 "Speed_Too_Low" 12 "Parking_Assistance_Active" 13 "Door_is_Open" 14 "Safety_Belt_not_Fasten" 15 "RHP_Available" 16 "RHP_Activated" 17 "RHP_Low_Activated" 18 "Lane_Change_not_Available_Traffi" 19 "Lane_Change_not_Available" 20 "Lane_Change_Left_Suggested" 21 "Lane_Change" 22 "Lane_Change_Cancelled" 23 "Lane_Change_Right_Suggested" 24 "Bus_lane" 25 "Deactivation" 26 "Close_Distance" 27 "Resume_RHP" 28 "Hard_Brake_Following" 29 "Hard_Brake_Cut_In" 30 "Tidal_Lane" 31 "WBA_Not_Active" ;
VAL_ 2331596042 RHP_Gong 0 "kein_akustisches_Signal" 1 "Gong_1" 2 "Gong_2" 3 "Gong_3" ;
VAL_ 2331596042 RHP_Tempolimit 0 "keine_Anzeige" 1 "5_zulHoechstgeschw" 2 "7_zulHoechstgeschw" 3 "10_zulHoechstgeschw" 4 "15_zulHoechstgeschw" 5 "20_zulHoechstgeschw" 6 "25_zulHoechstgeschw" 7 "30_zulHoechstgeschw" 8 "35_zulHoechstgeschw" 9 "40_zulHoechstgeschw" 10 "45_zulHoechstgeschw" 11 "50_zulHoechstgeschw" 12 "55_zulHoechstgeschw" 13 "60_zulHoechstgeschw" 14 "65_zulHoechstgeschw" 15 "70_zulHoechstgeschw" 16 "75_zulHoechstgeschw" 17 "80_zulHoechstgeschw" 18 "85_zulHoechstgeschw" 19 "90_zulHoechstgeschw" 20 "95_zulHoechstgeschw" 21 "100_zulHoechstgeschw" 22 "110_zulHoechstgeschw" 23 "120_zulHoechstgeschw" 24 "130_zulHoechstgeschw" 25 "140_zulHoechstgeschw" 26 "150_zulHoechstgeschw" 27 "160_zulHoechstgeschw" 28 "200_zulHoechstgeschw" 30 "250_zulHoechstgeschw" 31 "Ende_zulHoechstgeschw" ;
VAL_ 2331596042 RHP_Tempolimit_Farbe 0 "Grundfarbe" 1 "Farbe_1" 2 "Farbe_2" 3 "Farbe_3" ;
VAL_ 2331596042 RHP_Texte_Sekundaeranz 0 "Keine_Anzeige" 1 "Kurve_voraus" 2 "Tempolimit_erkannt" 3 "Tempolimit_voraus" 4 "Kreuzung_voraus" 5 "Kreisverkehr_voraus" 6 "Stauende_voraus" 7 "Anfahrbereit" 8 "Ampel_horizontal_voraus" 9 "Ampel_vertikal_voraus" 10 "Stoppschild_voraus" 11 "Ampel_horizontal_erkannt" 12 "Ampel_vertikal_erkannt" 13 "Vorfahrt_beachten_voraus" 14 "Bumper_voraus" 15 "Kuppe_voraus" 16 "Hindernis_erkannt" 17 "TA_Anfahrbereit" 18 "TA_Hindernis_erkannt" 19 "Rechtskurve_voraus" 20 "Linkskurve_voraus" ;
VAL_ 2331596042 RHP_aktiv_HMI 0 "nicht_aktiv" 1 "RHP_without_lane_change_aktiv" 2 "RHP_with_lane_change_aktiv" ;
VAL_ 2331596042 RHP_FoD_Status 0 "Init" 1 "kein_RHP_verbaut" 2 "RHP_without_lane_change_verbaut" 3 "RHP_with_lane_change_verbaut" ;
VAL_ 2331596042 RHP_Anzeige_Objektregelung 0 "Keine_Anzeige" 1 "Linkes_Nebenspurobjekt" 2 "Rechtes_Nebenspurobjekt" 3 "Direktes_Zielobjekt" 4 "Tempolimit" 5 "Kurve" 6 "links_Kurve" 7 "rechts_Kurve" 8 "Kreuzung" 9 "Kreisverkehr" 10 "Autobahnabfahrt_auffahrt" 11 "Stauende" 12 "Engstelle" 13 "Gefaelle" 14 "Steigung" 15 "Kuppe_Bumper" 16 "Ampel_horizontal" 17 "Ampel_vertikal" 18 "Bahnuebergang" ;
VAL_ 2331596042 RHP_HMI_DetectedLane 0 "Initial" 1 "Left_Highlight" 2 "Right_Highlight" 3 "Both_Highlight" ;
VAL_ 2331596042 RHP_HMI_Ego_li_Anzeige 0 "off" 1 "Deactivated" 2 "Control" 3 "Recognized" 4 "Warning" ;
VAL_ 2331596042 RHP_HMI_Ego_li_Typ 0 "invalid" 1 "Gruenstreifen" 2 "Durchgezogen" 3 "Gestrichelt" 4 "Randbebauung" 5 "virtuelle_Spurbegrenzung" ;
VAL_ 2331596042 RHP_HMI_Ego_re_Anzeige 0 "off" 1 "Deactivated" 2 "Control" 3 "Recognized" 4 "Warning" ;
VAL_ 2331596042 RHP_HMI_Ego_re_Typ 0 "invalid" 1 "Gruenstreifen" 2 "Durchgezogen" 3 "Gestrichelt" 4 "Randbebauung" 5 "virtuelle_Spurbegrenzung" ;
VAL_ 2331596042 RHP_HMI_Kurvenwarnung 0 "keine_Warnung" 1 "Warnung" ;
VAL_ 2331596042 RHP_HMI_LaneChangeIndicator 0 "No" 1 "Display" ;
VAL_ 2331596042 RHP_HMI_LaneChangeTrajectory 0 "Initial" 1 "Left_Active" 2 "Right_Active" 3 "Cancel_Left" 4 "Cancel_Right" ;
VAL_ 2331596042 RHP_HMI_Nachb_li_Anzeige 0 "off" 1 "Deactivated" 2 "Control" 3 "Recognized" 4 "Warning" ;
VAL_ 2331596042 RHP_HMI_Nachb_li_Typ 0 "invalid" 1 "Gruenstreifen" 2 "Durchgezogen" 3 "Gestrichelt" 4 "Randbebauung" 5 "virtuelle_Spurbegrenzung" ;
VAL_ 2331596042 RHP_HMI_Nachb_re_Anzeige 0 "off" 1 "Deactivated" 2 "Control" 3 "Recognized" 4 "Warning" ;
VAL_ 2331596042 RHP_HMI_Nachb_re_Typ 0 "invalid" 1 "Gruenstreifen" 2 "Durchgezogen" 3 "Gestrichelt" 4 "Randbebauung" 5 "virtuelle_Spurbegrenzung" ;
VAL_ 2331596042 RHP_Abstand_WZO 0 "keine_Anzeige" ;
VAL_ 2331596042 RHP_Sollabstand_1 0 "keine_Anzeige" ;
VAL_ 2331596042 RHP_Sollabstand_2 0 "keine_Anzeige" ;
VAL_ 2331596042 RHP_Sollabstand_3 0 "keine_Anzeige" ;
VAL_ 2331596042 RHP_Sollabstand_4 0 "keine_Anzeige" ;
VAL_ 2331596042 RHP_Sollabstand_5 0 "keine_Anzeige" ;
VAL_ 2331596042 RHP_Anzeige_Zeitluecke 0 "Anzeige_Zeitluecke_nicht_angefordert" 1 "Anzeige_Zeitluecke_angefordert" ;
VAL_ 2331596042 RHP_Abstandsindex 0 "Init" 1022 "aus_passiv" 1023 "aktiv_Freifahrt" ;
VAL_ 2331596042 RHP_Abstand_LNS 0 "keine_Anzeige" ;
VAL_ 2331596042 RHP_Abstand_RNS 0 "keine_Anzeige" ;
VAL_ 2331596042 RHP_Typ_LNS 0 "invalid" 1 "Fussgaenger" 2 "LKW" 3 "PKW" 4 "Motorrad" 5 "Radfahrer" 6 "Tricycle" 7 "Obstacle" ;
VAL_ 2331596042 RHP_Typ_RNS 0 "invalid" 1 "Fussgaenger" 2 "LKW" 3 "PKW" 4 "Motorrad" 5 "Radfahrer" 6 "Tricycle" 7 "Obstacle" ;
VAL_ 2331596042 RHP_Typ_WZO 0 "invalid" 1 "Fussgaenger" 2 "LKW" 3 "PKW" 4 "Motorrad" 5 "Radfahrer" 6 "Tricycle" 7 "Obstacle" ;
VAL_ 2331596042 RHP_Regelgeschw 1023 "keine_Anzeige" ;
VAL_ 2331596042 RHP_EGO_Fahrzeug 0 "keine_Anzeige" 1 "aktiv" 2 "Warnung" 3 "aktiv_stop" 4 "passiv" ;
VAL_ 2331596042 RHP_Relevantes_Objekt 0 "keine_Anzeige" 1 "Relevantes_Objekt_erkannt" 2 "Relevantes_Objekt_Warnung" 3 "passiv" ;
VAL_ 2331596042 RHP_Tempolimit_Einheit 0 "kmh_init" 1 "mph" ;
VAL_ 2331596042 RHP_maxSetzgeschw 511 "Init_Neutralwert" ;
VAL_ 2331596042 RHP_Einheit_maxSetzgeschw 0 "kmh" 1 "mph" ;
VAL_ 2331596042 RHP_TOR_Lamp 0 "keine_Anzeige" 1 "Passiv" 2 "Aktiv" 3 "reserviert" ;
VAL_ 2331596042 RHP_Gesetzte_Zeitluecke 0 "keine_Anzeige" 1 "Zeitluecke_1" 2 "Zeitluecke_2" 3 "Zeitluecke_3" 4 "Zeitluecke_4" 5 "Zeitluecke_5" 6 "nicht_definiert" 7 "nicht_definiert" ;
VAL_ 2331596042 RHP_StatusLamp 0 "Off" 1 "Standby_Deactivation" 2 "Ready" 3 "Function_Active" 4 "Error" 5 "Override_Longitudinal" 6 "Override_Lateral" 7 "Reserve" ;
VAL_ 2331596042 RHP_LateralLamp 0 "No_Display" 1 "Hands_on_control" 2 "Hands_off_control" 3 "reserve" ;
VAL_ 2331596042 RHP_Text_01 0 "No_Dispaly" 1 "Rush_Hour_Pilot_not_Available" 2 "Please_Take_Over_Error_Warning" 3 "Please_Take_Over_Leave_Geofence" 4 "Please_Take_Over_1" 5 "Please_Take_Over_2" 6 "Please_Take_Over_3" 7 "Take_Over_About_to_Deactivate" 8 "Please_Take_Over_4" 9 "Please_Take_Over_5" 10 "Hands_On_Mode" 11 "Lane_Change_Waiting" 12 "Press_Brake_1" 13 "Press_Brake_2" 14 "Lane_Change_Take_Steering" 15 "RHP_Degrade_Speed" ;
VAL_ 2331596042 RHP_ErrorStatus 0 "kein_Fehler" 1 "Fehler_RHP_without_lane_change" 2 "Fehler_RHP_Low_keine_Sensorsicht" 3 "Fehler_RHP_with_lane_change" 4 "Fehler_RHP_High_kein_Sensorsicht" ;
VAL_ 2331596042 RHP_Typ_CIO 0 "invalid" 1 "Fussgaenger" 2 "LKW" 3 "PKW" 4 "Motorrad" 5 "Radfahrer" 6 "Tricycle" 7 "Obstacle" ;
VAL_ 2331596042 RHP_CIO 0 "kein_Einschererobjekt" 1 "Einschererobjekt_von_links" 2 "Einschererobjekt_von_rechts" 3 "reserved" ;
VAL_ 2331596042 RHP_Abstand_CIO 0 "keine_Anzeige" ;
VAL_ 1610 RKA_FMVSS138_Lampe 0 "keine Warnung" 1 "Warnlampe FMVSS 138, gelbe Lampe statisch an" ;
VAL_ 1610 RKA_Warnungen_02 0 "keine_Anzeige" 1 "Kontrollleuchte" 2 "Systemfehler" 3 "Reifen_allgemein_Warnstufe_1" 4 "Reifen_vorne_links_Warnstufe_1" 5 "Reifen_vorne_rechts_Warnstufe_1" 6 "Reifen_hinten_links_Warnstufe_1" 7 "Reifen_hinten_rechts_Warnstufe_1" 8 "Reifen_allgemein_Warnstufe_2" 9 "Reifen_vorne_links_Warnstufe_2" 10 "Reifen_vorne_rechts_Warnstufe_2" 11 "Reifen_hinten_links_Warnstufe_2" 12 "Reifen_hinten_rechts_Warnstufe_2" 13 "Reifen_allgemein_Warnstufe_3" 14 "Reifen_vorne_links_Warnstufe_3" 15 "Reifen_vorne_rechts_Warnstufe_3" 16 "Reifen_hinten_links_Warnstufe_3" 17 "Reifen_hinten_rechts_Warnstufe_3" 18 "Reifendruecke_kalibrieren" 19 "Akustik" 20 "Systemfehler_Lampe_Text" 21 "Reifen_allgemein_Lampe_Text" 22 "Reifen_vorne_links_Lampe_Text" 23 "Reifen_vorne_rechts_Lampe_Text" 24 "Reifen_hinten_links_Lampe_Text" 25 "Reifen_hinten_rechts_Lampe_Text" 26 "Reifendruecke_kalibrieren_Text_Gong" 27 "Reifendruecke_kalibrieren_Text_Gong_Lampe" 28 "Reifenwechsel_erkannt" ;
VAL_ 1610 RKA_Reifentyp 0 "Init" 1 "Winter" 2 "Sommer" 3 "Ganzjahresreifen" 4 "Kundenspezifisch" ;
VAL_ 1440 LS_Helligkeit_IR 254 "Init" 255 "Fehler" ;
VAL_ 1440 LS_Helligkeit_FW 1022 "Init" 1023 "Fehler" ;
VAL_ 1440 LS_defekt 0 "OK" 1 "defekt" ;
VAL_ 1440 LS_Verbau 0 "Init" 1 "Lichtsensor_verbaut" ;
VAL_ 1440 RS_Regenmenge 0 "0" 1 "0,0_bis_0,3" 2 "0,31_bis_1,4" 3 "1,41_bis_2,0" 4 "2,01_bis_2,8" 5 "2,81_bis_3,3" 6 "3,31_bis_4,0" 7 "4,01_bis_5,0" 8 "5,01_bis_7,0" 9 "7,01_bis_9,0" 10 "9,01_bis_11,0" 11 "11,01_bis_15,0" 12 "15,01_bis_22,0" 13 ">22,01" 14 "Init" 15 "Fehler" ;
VAL_ 1440 RS_Schwall 0 "Aus" 1 "Ein" ;
VAL_ 1440 RS_Verbau 0 "Init" 1 "Regensensor verbaut" ;
VAL_ 1440 RS_Verglasung_schliessen 0 "Verglasung nicht schliessen" 1 "Verglasung schliessen" ;
VAL_ 1440 RS_defekt 0 "OK" 1 "defekt" ;
VAL_ 1440 RS_Wischergeschwindigkeit 0 "kein Wischen" 1 "42 Huebe/min" 2 "45 Huebe/min" 3 "48 Huebe/min" 4 "51 Huebe/min" 5 "54 Huebe/min" 6 "57 Huebe/min" 7 "60 Huebe/min" ;
VAL_ 1440 RLS_Vorfeldhelligkeit_Boost 0 "groesser_24413_Lux" 1 "bis_24413_Lux" 2 "bis_22193_Lux" 3 "bis_20176_Lux" 4 "bis_18342_Lux" 5 "bis_16647_Lux" 6 "bis_15158_Lux" 7 "bis_13780_Lux" 8 "bis_12527_Lux" 9 "bis_11388_Lux" 10 "bis_10353_Lux" 11 "bis_9412_Lux" 12 "bis_8556_Lux" 13 "bis_7778_Lux" 14 "bis_7071_Lux" 15 "bis_6428_Lux" ;
VAL_ 1440 SLS_Helligkeit_IR 254 "Init" 255 "Fehler" ;
VAL_ 1504 MD1_Position 126 "Init" 127 "nicht_normiert" ;
VAL_ 1504 MD1_Lage 0 "Ausstelllage" 1 "Schiebelage" ;
VAL_ 1504 MD3_Lage 0 "Ausstelllage" 1 "Schiebelage" ;
VAL_ 1504 MRollo_Position 126 "Init" 127 "nicht_normiert" ;
VAL_ 1504 MRollo_Lage 0 "Ausstelllage" 1 "Schiebelage" ;
VAL_ 1504 SAD_normiert 0 "inaktiv" 1 "aktiv" ;
VAL_ 1504 SAD_Thermoschutz 0 "inaktiv" 1 "aktiv" ;
VAL_ 1504 SAD_UEKB_aktiv 0 "inaktiv" 1 "aktiv" ;
VAL_ 1504 Rollo_normiert 0 "inaktiv" 1 "aktiv" ;
VAL_ 1504 Rollo_Thermoschutz 0 "inaktiv" 1 "aktiv" ;
VAL_ 1504 Rollo_UEKB_aktiv 0 "inaktiv" 1 "aktiv" ;
VAL_ 1504 SAD_Taster_Deckel_hi 0 "nicht_betaetigt" 1 "man_sl_zu" 2 "auto_sl_zu" 3 "man_sl_auf" 4 "auto_sl_auf" 5 "man_al_auf" 6 "auto_al_auf" 7 "man_al_zu" 8 "auto_al_zu" 14 "fehler_schalter_haengt" 15 "fehler_schalter_unplausibel" ;
VAL_ 1504 SAD_Taster_Deckel_vo 0 "nicht_betaetigt" 1 "man_sl_zu" 2 "auto_sl_zu" 3 "man_sl_auf" 4 "auto_sl_auf" 5 "man_al_auf" 6 "auto_al_auf" 7 "man_al_zu" 8 "auto_al_zu" 14 "fehler_schalter_haengt" 15 "fehler_schalter_unplausibel" ;
VAL_ 1504 SAD_Taster_Rollo_hi 0 "nicht_betaetigt" 1 "man_zu" 2 "auto_zu" 3 "man_auf" 4 "auto_auf" 6 "fehler_schalter_haengt" 7 "fehler_schalter_unplausibel" ;
VAL_ 1504 SAD_Taster_Rollo_vo 0 "nicht_betaetigt" 1 "man_zu" 2 "auto_zu" 3 "man_auf" 4 "auto_auf" 6 "fehler_schalter_haengt" 7 "fehler_schalter_unplausibel" ;
VAL_ 1504 SAD_Anf_ESC_Zuschaltung 0 "inaktiv" 1 "aktiv" ;
VAL_ 2463978605 SCode_Target 0 "Init" ;
VAL_ 2463978605 SCode_Data 0 "Init" ;
VAL_ 1522 KBI_Phototransistor 254 "Init" 255 "Fehler" ;
VAL_ 1522 KBI_Dimmpoti 126 "Nicht verfügbar" 127 "Fehler" ;
VAL_ 1167 SK1_Key_Data_10 0 "Init" ;
VAL_ 980 BH_Blinker_li 0 "nicht_betaetigt" 1 "Blinkerhebel_Pos_li_betaetigt" ;
VAL_ 980 BH_Blinker_re 0 "nicht_betaetigt" 1 "Blinkerhebel_Pos_re_betaetigt" ;
VAL_ 980 BH_Lichthupe 0 "nicht_betaetigt" 1 "Blinkerhebel in Richtung Lichthupe betaetigt" ;
VAL_ 980 BH_Fernlicht 0 "nicht_betaetigt" 1 "Blinkerhebel_in_Richtung_Fernlicht_betaetigt" ;
VAL_ 980 WH_Tipwischen 0 "nicht_betaetigt" 1 "betaetigt" ;
VAL_ 980 WH_Intervall 0 "aus" 1 "Wischerhebel in Stellung Intervall" ;
VAL_ 980 WH_WischerStufe1 0 "aus" 1 "Wischerhebel in Stufe Wischen 1" ;
VAL_ 980 WH_WischerStufe2 0 "aus" 1 "Wischerhebel in Stufe Wischen 2" ;
VAL_ 980 WH_Frontwaschen 0 "aus" 1 "Wischerhebel in Stellung Wisch Wasch vorne" ;
VAL_ 980 WH_Heckintervall 0 "nicht_betaetigt" 1 "Wischerhebel in Stellung Heckintervall" ;
VAL_ 980 WH_Heckwaschen 0 "nicht_betaetigt" 1 "Wischerhebel in Stellung Wisch Wasch hinten" ;
VAL_ 980 WH_Intervallstufen 0 "Init / Default" 1 "Intervallstufe 1" 5 "Intervallstufe 2" 9 "Intervallstufe 3" 13 "Intervallstufe 4" 15 "Fehler" ;
VAL_ 980 FAS_Taster 0 "nicht_betaetigt" 1 "betaetigt" ;
VAL_ 980 FAS_Taster_Fehler 0 "kein_Fehler" 1 "Fehler" ;
VAL_ 980 SMLS_Hupe 0 "nicht_betaetigt" 1 "Hupe_gedrueckt" ;
VAL_ 980 LRH_On_Off 0 "LRH_aus__keine Anzeige" 1 "LRH_aus" 2 "LRH_ein" 3 "Fehler" ;
VAL_ 980 LSS_Tastencode 0 "Key_Released__No_Key" 4 "Up" 5 "Down" 7 "OK__ThumbWheel_Button" ;
VAL_ 980 LRH_aktiv 0 "inaktiv" 1 "aktiv" ;
VAL_ 980 SMLS_P_verriegelt 0 "Init" 1 "nicht_verriegelt" 2 "verriegelt" 3 "Fehler" ;
VAL_ 980 SMLS_P_verriegelt_plausibel 0 "unplausibel" 1 "plausibel" ;
VAL_ 980 WH_SRA 0 "SRA_Aus" 1 "SRA_Ein" ;
VAL_ 980 WH_Wischer_Fehler 0 "kein_Fehler" 1 "Fehler" ;
VAL_ 980 BH_Blinker_Fehler 0 "kein_Fehler" 1 "Fehler" ;
VAL_ 980 SMLS_PTT 0 "nicht_betaetigt" 1 "PTT_gedrueckt" ;
VAL_ 980 WH_Tipwischen_lang 0 "nicht_betaetigt" 1 "betaetigt" ;
VAL_ 2589283756 SOK_ungeschuetzte_Zeit 0 "Init" ;
VAL_ 1467 SoSe_SunInt_2D_Li 254 "Init" 255 "Fehler" ;
VAL_ 1467 SoSe_SunInt_2D_Re 254 "Init" 255 "Fehler" ;
VAL_ 2527679739 STK_FSH_Anf 0 "keine_Anforderung" 1 "Frontscheibenheizung_Anf" ;
VAL_ 2527679739 STK_HSH_Anf 0 "keine_Anforderung" 1 "Heckscheibenheizung_Anf" ;
VAL_ 2527679739 STK_Klima_Temp 29 "VW_high_30C" 30 "Init" 31 "Fehler" ;
VAL_ 2527679739 STK_KurzVK_Anf 0 "nicht_angefordert" 1 "angefordert" ;
VAL_ 2527679739 STK_Standklima_Anf 0 "nicht_angefordert" 1 "angefordert" ;
VAL_ 2527679739 STK_Standklima_Timer_Status 0 "Standklimatimer_nicht_aktiv" 1 "Standklimatimer_aktiv" ;
VAL_ 2527679739 STK_AirCLeaner_Anf 0 "nicht_angefordert" 1 "angefordert" ;
VAL_ 2527679739 STK_VK_Modus 0 "keine_Vorkonditionierung" 1 "Sofort_Konditionierung" 2 "zeitversetzte_Konditionierung" 3 "Fehler" ;
VAL_ 2527679739 STK_ErwVK_Anf 0 "nicht_angefordert" 1 "angefordert" ;
VAL_ 2527679739 STK_ErwVK_Modus 0 "nicht_angefordert" 1 "Fahrerzone" 2 "Beifahrerzone" 3 "Heckzone_links" 4 "Heckzone_rechts" 5 "Scheibenheizung" ;
VAL_ 2527679739 STK_Berechnungsphase 0 "keine_Berechnungsphase" 1 "Berechnungsphase_erforderlich" 2 "Init" 3 "Fehler" ;
VAL_ 2527679739 STK_VK_Timer_Status 0 "nicht_aktiv" 1 "aktiv" 2 "Sofortstart_aktiv" ;
VAL_ 2527679739 STK_Anf_AussenspiegelHZ 0 "nicht_angefordert" 1 "angefordert" ;
VAL_ 2527679739 STK_ErwVK_Beifahrerzone 0 "nicht_angefordert" 1 "Beifahrerzone_angefordert" ;
VAL_ 2527679739 STK_ErwVK_Fahrerzone 0 "nicht_angefordert" 1 "Fahrerzone_angefordert" ;
VAL_ 2527679739 STK_ErwVK_Heckzone_links 0 "nicht_angefordert" 1 "Heckzone_links_angefordert" ;
VAL_ 2527679739 STK_ErwVK_Heckzone_rechts 0 "nicht_angefordert" 1 "Heckzone_rechts_angefordert" ;
VAL_ 2527679739 STK_ErwVK_Scheibenheizung 0 "nicht_angefordert" 1 "Scheibenheizung_angefordert" ;
VAL_ 2527679739 STK_VK_STH_Einsatz 0 "Verbrennerstandheizung verbieten" 1 "Automatik (Verbrennerstandheizung erlauben)" 2 "Verbrennerstandheizung erzwingen" 3 "reserviert" 4 "reserviert" 5 "reserviert" 6 "Init" 7 "Fehler" ;
VAL_ 2527679739 STK_Voko_LED 0 "Aus" 1 "Ein" ;
VAL_ 2527679739 STK_MaxLeistung 254 "Init" 255 "Fehler" ;
VAL_ 2527679739 STK_GesamtEnergiebedarf 254 "Init" 255 "Fehler" ;
VAL_ 2527679739 STK_Stecker_Status 0 "kein_Stecker_erkannt" 1 "AC_Stecker_erkannt" 2 "DC_Stecker_erkannt" ;
VAL_ 2527679739 STK_ErwVK_Heckzone2_links 0 "nicht_angefordert" 1 "Heckzone2_links_angefordert" ;
VAL_ 2527679739 STK_ErwVK_Heckzone2_rechts 0 "nicht_angefordert" 1 "Heckzone2_rechts_angefordert" ;
VAL_ 1313 STH_Funk_ein 0 "kein Funkbefehl zum Einschalten" 1 "Funkbefehl zum Einschalten erhalten" ;
VAL_ 1313 STH_Funk_aus 0 "kein Funkbefehl" 1 "Funkbefehl zum Ausschalten erhalten" ;
VAL_ 1313 STH_Zusatzheizung 0 "Zuheizer aus" 1 "Zuheizer ein" ;
VAL_ 1313 STH_LED 0 "keine Rückmeldung" 1 "Rueckmeldung Standheizung in Betrieb" ;
VAL_ 1313 STH_Geblaese 0 "kein Einschaltbefehl an die Klimaanlage, Gebläse" 1 "Einschaltbefehl an die Klimaanlage, Gebläse" ;
VAL_ 1313 STH_EKP_Anst 0 "EKP nicht ansteuern" 1 "EKP ansteuern" ;
VAL_ 1313 STH_Start_folgt 0 "kein_Start_folgt" 1 "Start_folgt" ;
VAL_ 1313 STH_Ventil_Status 0 "Ventil_offen__grosser_Kreislauf" 1 "Ventil_geschlossen__kleiner_Kreislauf" ;
VAL_ 1313 STH_Fehler_ElWaPu 0 "kein_Fehler" 1 "Fehler" ;
VAL_ 1313 STH_Pumpen_Anf_extern 0 "nicht_angefordert" 1 "angefordert" ;
VAL_ 1313 STH_KL_HUP 0 "Aus" 1 "Ein" ;
VAL_ 1313 STH_Fehlerstatus 0 "kein_Fehler" 1 "Unterspannung" 2 "Tankfuellstand_zu_gering" 3 "Fehler_Betrieb_verhindert" 4 "Heizgeraet_verriegelt" 5 "Fehler_Betrieb_nicht_verhindert" 6 "Emissionsüberschreitung" ;
VAL_ 1313 STH_Wassertemp 254 "Init" 255 "Fehler" ;
VAL_ 1313 STH_Texte 0 "keine_Anzeige" 1 "Batteriemanagementeinschraenkung" 2 "Kraftstoffmangel" 3 "interner_Systemfehler" 4 "Heizzeitueberschreitung" ;
VAL_ 1313 STH_Motorvorwaermung 0 "keine Motorvorwärmung erfolgt" 1 "Aufheizung mit Motorvorwärmung erfolgt" ;
VAL_ 1313 STH_Servicemode 0 "Servicemode nicht aktiv" 1 "Servicemode aktiv" ;
VAL_ 1313 STH_war_aktiv 0 "war inaktiv" 1 "Standheizung war letzte halbe Stunde aktiv" ;
VAL_ 1313 STH_KVS_Ueberlauf 0 "kein Überlauf" 1 "Kraftstoffverbrauchssignal, mindestens ein Überlauf hat stattgefunden" ;
VAL_ 1313 STH_SH_ZH 0 "Heizgeraet_WZH" 1 "Heizgeraet_ZH" ;
VAL_ 1413 SI_Sammel_SG_Fehler 61 "Reserviert" 62 "Overflow" 63 "ungueltig" ;
VAL_ 1413 SI_P_Mode_gueltig 0 "dezentraler_Produktionsmode" 1 "zentraler_Produktionsmode" ;
VAL_ 1413 SI_Diagnose_Aktiv 0 "inaktiv" 1 "aktiv" ;
VAL_ 1413 SI_QRS_Mode 0 "QRS_Messmodus_nicht_aktiv" 1 "QRS_Messmodus_aktiv" ;
VAL_ 1413 SI_T_Mode 0 "Transportmodus_nicht_aktiv" 1 "Transportmodus_aktiv" ;
VAL_ 1413 SI_NWDF 0 "Ueberwachung_nicht_freigegeben" 1 "Ueberwachung_freigegeben" ;
VAL_ 1413 SI_NWDF_gueltig 0 "NWDF_wird_nicht_unterstuetzt" 1 "NWDF_wird_unterstuetzt" ;
VAL_ 1413 SI_Sammelfehler 0 "kein_Sammelfehler" 1 "Sammelfehler" ;
VAL_ 1413 GW_KD_Fehler 0 "kein_KD_Fehler" 1 "KD_Fehler" ;
VAL_ 1413 SI_T_Schutz 0 "Transportschutz_nicht_aktiv" 1 "Transportschutz_aktiv" ;
VAL_ 1413 SI_P_Mode 0 "inaktiv" 1 "aktiv" ;
VAL_ 1413 SI_BUS_01 0 "keine_Busruhe" 1 "Busruhe" ;
VAL_ 1413 SI_BUS_02 0 "keine_Busruhe" 1 "Busruhe" ;
VAL_ 1413 SI_BUS_03 0 "keine_Busruhe" 1 "Busruhe" ;
VAL_ 1413 SI_BUS_04 0 "keine_Busruhe" 1 "Busruhe" ;
VAL_ 1413 SI_BUS_05 0 "keine_Busruhe" 1 "Busruhe" ;
VAL_ 1413 SI_BUS_06 0 "keine_Busruhe" 1 "Busruhe" ;
VAL_ 1413 SI_BUS_07 0 "keine_Busruhe" 1 "Busruhe" ;
VAL_ 1413 SI_BUS_08 0 "keine_Busruhe" 1 "Busruhe" ;
VAL_ 1413 SI_BUS_09 0 "keine_Busruhe" 1 "Busruhe" ;
VAL_ 1413 SI_BUS_10 0 "keine_Busruhe" 1 "Busruhe" ;
VAL_ 1413 SI_BUS_11 0 "keine_Busruhe" 1 "Busruhe" ;
VAL_ 1413 SI_BUS_12 0 "keine_Busruhe" 1 "Busruhe" ;
VAL_ 1413 SI_BUS_13 0 "keine_Busruhe" 1 "Busruhe" ;
VAL_ 1413 SI_BUS_14 0 "keine_Busruhe" 1 "Busruhe" ;
VAL_ 1413 SI_BUS_15 0 "keine_Busruhe" 1 "Busruhe" ;
VAL_ 1413 SI_NWDF_30 0 "Ueberwachung_nicht_freigegeben" 1 "Ueberwachung_freigegeben" ;
VAL_ 1413 SI_Bus_Identifikation 16 "CAN_Diagnose" 17 "CAN_Antrieb" 18 "CAN_Komfort" 19 "CAN_Infotainment" 20 "CAN_Fahrwerk" 21 "CAN_Extended" 22 "CAN_Hybrid" 23 "CAN_Lade" 24 "CAN_Kombi" 25 "CAN_Komfort_2" 26 "CAN_AFS" 27 "CAN_MIB" 28 "CAN_Batterie_BMC" 29 "CAN_Motor" 31 "CAN_Airbag_Sicherheitssysteme" 33 "CAN_FahrerAssistenzSysteme" 34 "CAN_Migration" 35 "CAN_Connect" 36 "CAN_AnzeigeBedienung" 37 "CAN_ElectricalVehicle" 40 "CAN_Telematik" 41 "CAN_MFL" 42 "CAN_FahrerAssistenzSysteme_2" 43 "CAN_FahrerAssistenzSysteme_3" 47 "CAN_Komfort_3" 48 "FlexRay_A" 49 "FlexRay_B" 97 "VLAN_FAS" 98 "VLAN_Infotainment" 99 "VLAN_Connect" 100 "VLAN_Komfort" 101 "VLAN_Antrieb" 102 "VLAN_Diagnose" 103 "VLAN_Internet" 104 "VLAN_Gateway" 105 "VLAN_Remote_FC" 106 "VLAN_Connect_2" 107 "VLAN_Licht" 108 "VLAN_Charge" 109 "VLAN_Cockpit" 110 "VLAN_Connect_3" 111 "VLAN_IoT" 112 "VLAN_CarPerformance" 113 "VLAN_ConMod" 114 "VLAN_FAS2" 176 "HCP1_CANFD01" 177 "HCP1_CANFD02" 178 "HCP1_CANFD03" 179 "HCP1_CANFD04" 180 "HCP1_CANFD05" 181 "HCP1_CANFD06" 182 "HCP1_CANFD07" 183 "HCP1_CANFD08" 186 "HCP4_CANFD03" 187 "HCP4_CANFD04" 188 "HCP1_CANFD09" 189 "HCP4_CANFD06" 190 "HCP4_CANFD07" 191 "HCP4_CANFD08" 192 "HCP4_CANFD09" 193 "HCP4_CANFD10" 194 "HCP1_CANFD10" 195 "ICAS1_CANFD2_HCP5_CANFD02" 196 "HCP1_CANFD11" 197 "WU_HCP1_CANFD" 199 "WU_HCP2_CANFD" 200 "WU_HCP3_CANFD" 201 "WU_HCP4_CANFD" 202 "HCP3_CANFD02" 204 "ESC_CANFD" 205 "HCP4_CANFD11" 206 "HCP4_CANFD12" 207 "CAN_Innenraumsensorik" 212 "WU_ConMod_CANFD" 213 "WU_PASD_CANFD" 215 "CAN_MobileDeviceKey" 217 "CAN_Tuerantrieb_VL" 218 "CAN_Tuerantrieb_VR" 219 "CAN_Tuerantrieb_HL" 220 "CAN_Tuerantrieb_HR" ;
VAL_ 1413 SI_CAB_V14 0 "Init" 1 "CAB_01_Antrieb" 2 "CAB_02_Hybrid_Laden" 4 "CAB_03_Fahrwerk" 8 "CAB_04_Fahrerassistenz" 16 "CAB_05_Komfort" 32 "CAB_06_Anzeige" 64 "CAB_07_Connect" 128 "CAB_08_MIB" 256 "CAB_09_Standheizung" 1024 "CAB_11_VLAN_Fahrerassistenz" 2048 "CAB_12_VLAN_Komfort" 4096 "CAB_13_VLAN_Connect" 8192 "CAB_14_VLAN_Infotainment" 16384 "CAB_15_Laden" 32768 "CAB_16_Licht" ;
VAL_ 619 TA_ACC_Sollstatus 0 "Init" 1 "ACC_aktivieren" 2 "ACC_deaktivieren" ;
VAL_ 619 TA_Status 0 "Keine_Anzeige" 1 "Passiv" 2 "Aktiv" 3 "Warnung" ;
VAL_ 619 TA_Spurwechsel 0 "Kein_Spurwechsel" 1 "Spurwechsel_links" 2 "Spurwechsel_rechts" 3 "Spurwechselfreigabe_links" 4 "Spurwechselfreigabe_rechts" 5 "TA_Modus_StandBy" 6 "Spurwechselfreigabe_li_und_re" ;
VAL_ 619 TA_Texte 0 "Keine_Anzeige" 1 "Nicht_verfuegbar" 2 "Modus_TA_m_ass_Spurwechsel_gewae" 3 "Modus_ACC_ausgewaehlt" 4 "Modus_TravelAssist_ausgewaehlt" 5 "Spurwechsel_nicht_verfuegbar" 6 "Spurwechsel_abgebrochen" 7 "Spurw_abgebr_Lenkung_uebernehmen" ;
VAL_ 619 TA_FoD_Status 0 "Init" 1 "kein_TA_verbaut" 2 "TA_Low_verbaut" 3 "TA_Low_und_TA_High_verbaut" ;
VAL_ 619 TA_Spurwechsel_Ready 0 "nicht_moeglich" 1 "links_moeglich" 2 "rechts_moeglich" 3 "links_rechts_moeglich" ;
VAL_ 619 TA_Texte_02 0 "Keine_Anzeige" 1 "TA_zur_Zeit_nicht_aktivierbar" 2 "Zurzeit_nur_Spurfuehrung_verfueg" 3 "Fahreruebernahme_stumm" 4 "Fahreruebernahme_leise" 5 "Systemgrenzenwarnung" 6 "Fehler_TA_Low_keine_Sensorsicht" 7 "Fehler_TA_High_keine_Sensorsicht" 8 "Reserved_08" 9 "Reserved_09" 10 "Reserved_10" 11 "Reserved_11" 12 "Reserved_12" 13 "Reserved_13" 14 "Reserved_14" 15 "Reserved_15" ;
VAL_ 619 TA_Handsoff_LED 0 "keine_Anzeige" 1 "weiss" 2 "rot" 3 "reserviert" ;
VAL_ 619 TA_aktiv_HMI 0 "nicht_aktiv" 1 "TA_Low_aktiv" 2 "TA_High_aktiv" ;
VAL_ 619 TA_Fehler 0 "kein_Fehler" 1 "Fehler_TA_Low" 2 "Fehler_TA_Low_keine_Sensorsicht" 3 "Fehler_TA_High" 4 "Fehler_TA_High_keine_Sensorsicht" ;
VAL_ 619 TA_Ueberholhilfe 0 "Init" 1 "keine_Ueberholhilfe" 2 "ACC_Ueberholhilfe" 3 "TA_FSW_Ueberholhilfe" ;
VAL_ 619 TA_FSW_Zuruecklenken 0 "Init" 1 "FSW_Zuruecklenken_nicht_aktiv" 2 "FSW_Zuruecklenken_aktiv" 3 "reserved" ;
VAL_ 619 TA_FSW_Wartegrund_Umfeld 0 "Keine_Anzeige" 1 "Umfeld_vorne" 2 "Umfeld_hinten" 3 "Linientyp_Ego" 4 "Querbeschleunigung" 5 "Geschwindigkeit_Sonstiges" ;
VAL_ 619 TA_FSW_Warten 0 "FSW_Wartemodus_nicht_aktiv" 1 "FSW_Wartemodus_aktiv_links" 2 "FSW_Wartemodus_aktiv_rechts" ;
VAL_ 1001 Thermo_Pred_T_dyn_Innen 254 "Init" 255 "Fehler" ;
VAL_ 1001 Thermo_Pred_P_dyn_Innen 2046 "Init" 2047 "Fehler" ;
VAL_ 1001 Thermo_Pred_P_stat_Innen 2046 "Init" 2047 "Fehler" ;
VAL_ 1001 Thermo_Verbrauch_BTL_Ueberlauf 0 "kein_Ueberlauf" 1 "Ueberlauf" ;
VAL_ 1001 Thermo_Verbrauch_Innen_Ueberlauf 0 "kein_Ueberlauf" 1 "Ueberlauf" ;
VAL_ 1447 ORU_KombiTimer 0 "ORU_Inaktiv" 1 "ORU_Start" ;
VAL_ 1447 MOD_Energie_Anf 0 "Keine_Anforderung" 1 "Anforderung_NV" 2 "Anforderung_HV_Nutzung_Erlaubt" 3 "Fehler" ;
VAL_ 1447 FaceRec_Enroll_Challenge_Request 0 "SEND_NOTHING" 1 "SEND_CHALLENGE" ;
VAL_ 1447 eCall_Mute_Anf 0 "kein_mute" 1 "mute" ;
VAL_ 1447 FoD_Anz_Funktionsabschaltung 0 "Init" 1 "Popup_aufschalten" ;
VAL_ 1447 iCall_active 0 "inaktiv" 1 "aktiv" ;
VAL_ 1447 bCall_active 0 "bcall_inactive" 1 "bcall_active" ;
VAL_ 1447 MOD_Request_ServiceKey 0 "Init" 1 "Aktuallisierungsanfrage" ;
VAL_ 1447 eCall_Funktionsstatus_02 0 "kein_Fehler" 1 "Manueller_Notruf_aktiv" 2 "Automatischer_Notruf_aktiv" 7 "Init" ;
VAL_ 1447 eCall_Funktionsstatus 0 "kein_Fehler" 1 "Fkt_eingeschraenkt" 2 "Fkt_eingeschraenkt_service" 3 "Fkt_nicht_verfuegbar" 4 "Fkt_Service" 5 "Fkt_deaktiviert" 6 "Fkt_aktiviert" 7 "init" ;
VAL_ 1447 TM_Spiegel_Anklappen 0 "Init" 1 "Spiegel_anklappen" ;
VAL_ 1447 TM_Nur_Hupen 0 "inaktiv" 1 "aktiv" ;
VAL_ 1447 TM_Door_Lock 0 "Init" 1 "door_lock" ;
VAL_ 1447 TM_Door_Unlock 0 "Init" 1 "door_unlock" ;
VAL_ 1447 TM_Warnblinken 0 "Init" 1 "Warnblinken_on" ;
VAL_ 1447 TM_Panik_Alarm 0 "Init" 1 "panik_alarm_on" ;
VAL_ 1447 TM_ZV_Signatur 0 "Init" ;
VAL_ 977 BT_Tuer_geoeffnet 0 "geschlossen" 1 "offen" ;
VAL_ 977 BT_verriegelt 0 "Init" 1 "verriegelt" ;
VAL_ 977 BT_gesafet 0 "Init" 1 "gesafet" ;
VAL_ 977 BT_Schluesselschalter_auf 0 "Init" 1 "Schluesselschalter_auf_betaetigt" ;
VAL_ 977 BT_Schluesselschalter_zu 0 "Init" 1 "Schluesselschalter_zu_betaetigt" ;
VAL_ 977 BT_Unlock_Taster 0 "Init" 1 "Unlock_Taster_betaetigt" ;
VAL_ 977 BT_Lock_Taster 0 "Init" 1 "Lock_Taster_betaetigt" ;
VAL_ 977 BT_Sperrklinke 0 "Schloss_in_Vorraste_und_Hauptraste" 1 "Tuer_auf_oder_Tuer_Position_zwischen_Vor_und_Hauptraste" ;
VAL_ 977 BT_TAG_betaetigt 0 "Init" 1 "Tuerinnengriff_betaetigt" ;
VAL_ 977 BT_TIG_betaetigt 0 "Init" 1 "Tuerinnengriff_betaetigt" ;
VAL_ 977 BT_Tuer_Status 0 "Init" 1 "Tuer_geschlossen" 2 "Tuer_offen" 3 "Fehler" ;
VAL_ 977 BT_TSG_hinten_verbaut 0 "nicht verbaut" 1 "verbaut" ;
VAL_ 977 BT_Sp_Blk_def 0 "iO" 1 "Spiegel_Blinker_defekt" ;
VAL_ 977 BT_FH_S_ManHoch 0 "Init" 1 "FH_Schalter_man_hoch_gedrueckt" ;
VAL_ 977 BT_FH_S_AutoHoch 0 "Init" 1 "FH_Schalter_auto_hoch_gedrueckt" ;
VAL_ 977 BT_FH_S_ManTief 0 "Init" 1 "FH_Schalter_man_tief_gedrueckt" ;
VAL_ 977 BT_FH_S_AutoTief 0 "Init" 1 "FH_Schalter_auto_tief_gedrueckt" ;
VAL_ 977 BT_FH_Bew_hoch 0 "Init" 1 "FH_ist_in_Bewegung_hoch" ;
VAL_ 977 BT_FH_Bew_tief 0 "Init" 1 "FH_ist_in_Bewegung_tief" ;
VAL_ 977 BT_FH_Fang 0 "ausserhalb_Fangbereich" 1 "innerhalb_Fangbereich" ;
VAL_ 977 BT_FH_Block 0 "Init" 1 "Fensterheber_Block" ;
VAL_ 977 BT_FH_Thermo 0 "Init" 1 "Thermoschutz_aktiv" ;
VAL_ 977 BT_UEKB_aktiviert 0 "Init" 1 "aktiv" ;
VAL_ 977 BT_Kisi_Fehler 0 "kein_Fehler" 1 "Fehler" ;
VAL_ 977 BT_FH_normiert 0 "Init" 1 "Fenster_normiert" ;
VAL_ 977 BT_Schliesstaster 0 "nicht_betaetigt" 1 "betaetigt" ;
VAL_ 977 BT_Zuziehhilfe_aktiv 0 "Init" 1 "Zuziehhilfe_aktiv" ;
VAL_ 977 BT_SP_ausgerastet 0 "Init" 1 "Spiegel_ausgerastet" ;
VAL_ 977 BT_SP_lr_aktiv 0 "Init" 1 "Spiegel_xAchse_aktiv" ;
VAL_ 977 BT_SP_ht_aktiv 0 "Init" 1 "Spiegel_yAchse_aktiv" ;
VAL_ 977 BT_SP_Heizung_aktiv 0 "BF_Spiegelheizung_aus" 1 "BF_Spiegelheizung_ein" ;
VAL_ 977 BT_Oben_Block_erw 0 "Fensterheber_nicht_in_Blockerwar" 1 "Fensterheber_in_Blockerwartung_o" ;
VAL_ 977 BT_Unten_Block_erw 0 "Fensterheber_nicht_in_Blockerwar" 1 "Fensterheber_in_Blockerwartung_u" ;
VAL_ 977 BT_Tuer_Status_QBit 0 "Status_Tuerkontakt_sicher" 1 "Status_Tuerkontakt_unsicher" ;
VAL_ 977 BFS_Status_eTAG 0 "Init" 1 "Griff_ausgefahren" 2 "Griff_eingefahren" 3 "Fehler" ;
VAL_ 977 BT_TCR_Mode_aktiv 0 "TCR_Mode_deaktiv" 1 "TCR_Mode_aktiv" ;
VAL_ 977 BT_Lock_Unlock_Taster 0 "nicht_betaetigt" 1 "betaetigt" ;
VAL_ 977 BT_SP_Heizung_Status 0 "Init" 1 "Status_Spiegelheizung_ein" ;
VAL_ 977 ASW_Warnung_aktiv_BFS 0 "nicht_angefordert" 1 "angefordert" ;
VAL_ 977 BT_FH_Pos_oben 1 "Scheibe oben (nach Absenken auf Position) " ;
VAL_ 977 BT_Tuerschloss_defekt 0 "Tuerschloss_funktionsfaehig" 1 "Tuerschloss_defekt" ;
VAL_ 977 BT_Tueroeffnen_Warnung 0 "Tuerwarnung_nicht_aktiv" 1 "Tuerwarnung_aktiv" ;
VAL_ 977 BT_Lock_Taster_inv 0 "Lock Taster betätigt" 1 "Lock Taster nicht betätigt" ;
VAL_ 977 BT_Schluesselschalter_zu_inv 0 "Schlüsselschalter betätigt" 1 "Schlüsselschalter nicht betätigt" ;
VAL_ 977 BT_SWA_HMI_defekt 0 "SWA_kein_Fehler" 1 "SWA_Fehler" ;
VAL_ 977 BT_ASW_HMI_defekt 0 "ASW_kein_Fehler" 1 "ASW_Fehler" ;
VAL_ 976 FT_Tuer_geoeffnet 0 "geschlossen" 1 "Tuer_offen" ;
VAL_ 976 FT_verriegelt 0 "Init" 1 "verriegelt" ;
VAL_ 976 FT_gesafet 0 "Init" 1 "gesafet" ;
VAL_ 976 FT_Schluesselschalter_auf 0 "Init" 1 "Schluesselschalter_auf_betaetigt" ;
VAL_ 976 FT_Schluesselschalter_zu 1 "Schluesselschalter zu betaetigt" ;
VAL_ 976 FT_Unlock_Taster 0 "Init" 1 "Unlock_Taster_betaetigt" ;
VAL_ 976 FT_Lock_Taster 0 "Init" 1 "Lock_Taster_betaetigt" ;
VAL_ 976 FT_Sperrklinke 0 "Schloss_in_Vorraste_und_Hauptraste" 1 "Tuer_auf_oder_Tuer_Position_zwischen_Vor_und_Hauptraste" ;
VAL_ 976 FT_TAG_betaetigt 0 "nicht_betaetigt" 1 "betaetigt" ;
VAL_ 976 FT_TIG_betaetigt 0 "nicht_betaetigt" 1 "betaetigt" ;
VAL_ 976 FT_IRUE_Taste 0 "Init" 1 "IRUE_Taste_betaetigt" ;
VAL_ 976 FT_HD_Taste 0 "nicht_betaetigt" 1 "Heckdeckeltaste_betaetigt" ;
VAL_ 976 FT_TD_Taste_Fehler 0 "iO" 1 "defekt" ;
VAL_ 976 FT_TD_Taste 0 "Init" 1 "Tankdeckel_Taster_betaetigt" ;
VAL_ 976 SSR_Temp_Freigabe 0 "SSR_Deaktiviert" 1 "SSR_Freigegeben" ;
VAL_ 976 FT_HD_Taste_2 0 "Taste_nicht_gedrueckt" 1 "Taste_gedrueckt" ;
VAL_ 976 FT_Lock_Unlock_Taster 0 "nicht_betaetigt" 1 "betaetigt" ;
VAL_ 976 FT_TSG_hinten_verbaut 0 "nicht verbaut" 1 "verbaut" ;
VAL_ 976 FT_Sp_Blk_def 0 "iO" 1 "defekt" ;
VAL_ 976 FT_FH_S_ManHoch 0 "Init" 1 "FH_Schalter_man_hoch_betaetigt" ;
VAL_ 976 FT_FH_S_AutoHoch 0 "Init" 1 "FH_Schalter_auto_hoch_betaetigt" ;
VAL_ 976 FT_FH_S_ManTief 0 "Init" 1 "FH_Schalter_man_tief_betaetigt" ;
VAL_ 976 FT_FH_S_AutoTief 0 "Init" 1 "FH_Schalter_auto_tief_betaetigt" ;
VAL_ 976 FT_FH_Bew_hoch 0 "Init" 1 "FH_in_Bewegung_hoch" ;
VAL_ 976 FT_FH_Bew_tief 0 "Init" 1 "FH_in_Bewegung_tief" ;
VAL_ 976 FT_FH_Fang 0 "ausserhalb_Fangbereich" 1 "innerhalb_Fangbereich" ;
VAL_ 976 FT_FH_Block 0 "Init" 1 "Fenster_Block" ;
VAL_ 976 FT_FH_Thermo 0 "Init" 1 "Thermoschutz_aktiv" ;
VAL_ 976 FT_UEKB_aktiviert 0 "Init" 1 "UEKB_aktiv" ;
VAL_ 976 ASW_HMI_defekt 0 "iO" 1 "defekt" ;
VAL_ 976 FT_FH_normiert 0 "Init" 1 "Fenster_normiert" ;
VAL_ 976 FT_Schliesstaster 1 "Schliesstaster_betaetigt" ;
VAL_ 976 FT_Zuziehhilfe_aktiv 0 "Init" 1 "Zuziehilfe_aktiv" ;
VAL_ 976 FT_SP_ausgerastet 0 "Init" 1 "Spiegel_ausgerastet" ;
VAL_ 976 FT_SP_lr_aktiv 0 "Init" 1 "Spiegel_xAchse_aktiv" ;
VAL_ 976 FT_SP_ht_aktiv 0 "Init" 1 "Spiegel_yAchse_aktiv" ;
VAL_ 976 ASW_wakeup 0 "Sleep" 1 "Wakeup" ;
VAL_ 976 FT_Oben_Block_erw 0 "Fensterheber_nicht_in_Blockerwar" 1 "Fensterheber_in_Blockerwartung_o" ;
VAL_ 976 FT_Unten_Block_erw 0 "Fensterheber_nicht_in_Blockerwar" 1 "Fensterheber_in_Blockerwartung_u" ;
VAL_ 976 FT_Kisi_li_aktiv 0 "inaktiv" 1 "aktiv" ;
VAL_ 976 FT_Kisi_re_aktiv 0 "inaktiv" 1 "aktiv" ;
VAL_ 976 FT_Kisi_Taster_li 0 "nicht_betaetigt" 1 "betaetigt" ;
VAL_ 976 FT_Kisi_Taster_re 0 "nicht_betaetigt" 1 "betaetigt" ;
VAL_ 976 FT_BFS_Fond_Freigabe 0 "Init" 1 "Freigabe_fuer_Fondbedienung_BFS" ;
VAL_ 976 FT_Kisi_Fehler 0 "kein_Fehler" 1 "Fehler" ;
VAL_ 976 FT_Daemmglas 0 "Normalglas_verbaut" 1 "Daemmglas_verbaut" ;
VAL_ 976 FT_SP_Heizung_Status 0 "Init" 1 "Status_Spiegelheizung_ein" ;
VAL_ 976 ASW_Warnung_aktiv_FS 0 "nicht_angefordert" 1 "angefordert" ;
VAL_ 976 FT_FH_Pos_oben 1 "Scheibe oben (nach Absenken auf Position) " ;
VAL_ 976 FT_Tuerschloss_defekt 0 "Tuerschloss_funktionsfaehig" 1 "Tuerschloss_defekt" ;
VAL_ 976 FT_SWA_Taster 0 "Taster_nicht_betaetigt" 1 "Taster_betaetigt" ;
VAL_ 976 SWA_HMI_Diagnose 0 "kein_Fehler_erkannt" 1 "Fehler_Taster_erkannt" 2 "Fehler_LED_erkannt" 3 "Fehler_LED_und_Taster_erkannt" ;
VAL_ 976 FS_Status_eTAG 0 "Init" 1 "Griff_ausgefahren" 2 "Griff_eingefahren" 3 "Fehler" ;
